VERSION ""

NS_ :

BS_:

BU_: TCM_Diesel ECM_Diesel BECMB_EPM TCM ECM Generic_BCM GWM _delete APIM BCM DCDC_VQM PAM TSTR PCM

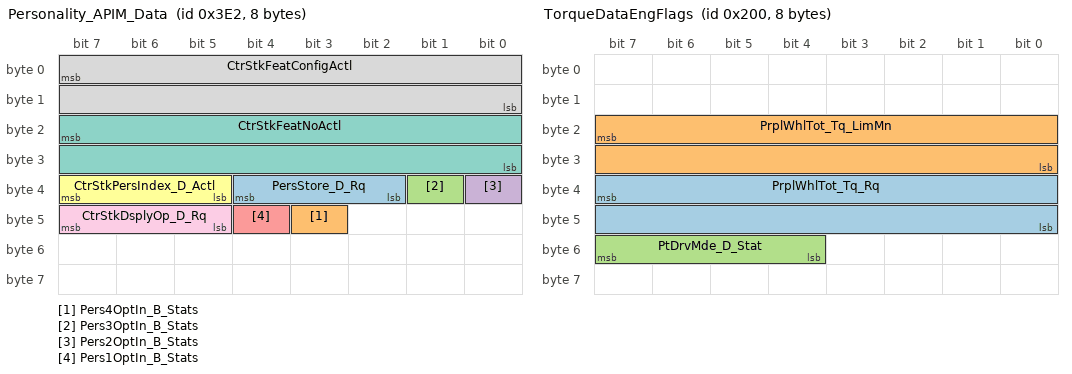
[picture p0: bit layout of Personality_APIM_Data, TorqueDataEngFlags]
BO_ 994 Personality_APIM_Data: 8 APIM
 SG_ PersStore_D_Rq : 36|3@0+ (1,0) [0|7] "SED"  GWM
 SG_ Pers4OptIn_B_Stats : 43|1@0+ (1,0) [0|1] "SED"  GWM,BCM
 SG_ Pers3OptIn_B_Stats : 33|1@0+ (1,0) [0|1] "SED"  GWM,BCM
 SG_ Pers2OptIn_B_Stats : 32|1@0+ (1,0) [0|1] "SED"  GWM,BCM
 SG_ Pers1OptIn_B_Stats : 44|1@0+ (1,0) [0|1] "SED"  GWM,BCM
 SG_ CtrStkPersIndex_D_Actl : 39|3@0+ (1,0) [0|7] "SED"  GWM,BCM
 SG_ CtrStkFeatNoActl : 23|16@0+ (1,0) [0|65535] "Undefined"  GWM,BCM
 SG_ CtrStkFeatConfigActl : 7|16@0+ (1,0) [0|65535] "Undefined"  GWM,BCM
 SG_ CtrStkDsplyOp_D_Rq : 47|3@0+ (1,0) [0|7] "SED"  GWM,BCM

BO_ 512 TorqueDataEngFlags: 8 PCM
 SG_ PrplWhlTot_Tq_Rq : 39|16@0+ (4,-131072) [-131072|131068] "Nm"  GWM
 SG_ PrplWhlTot_Tq_LimMn : 23|16@0+ (4,-131072) [-131072|131068] "Nm"  GWM
 SG_ PtDrvMde_D_Stat : 55|4@0+ (1,0) [0|15] "SED"  GWM

BO_ 65 Global_PATS_Control_Info: 8 BCM
 SG_ immoControlData_T1 : 15|40@0+ (1,0) [0|1099511627775] "Encrypted"  ECM_Diesel,ECM,PCM
 SG_ immoControlCmd_T1 : 7|3@0+ (1,0) [0|7] "SED"  ECM_Diesel,ECM,PCM

BO_ 1838 TesterPhysicalResBCM: 8 BCM
 SG_ TesterPhysicalResBCM : 7|64@0+ (1,0) [0|1.84467E+019] "unitless"  TSTR

BO_ 1830 TesterPhysicalReqBCM: 8 TSTR
 SG_ TesterPhysicalReqBCM : 7|64@0+ (1,0) [0|1.84467E+019] "unitless"  BCM

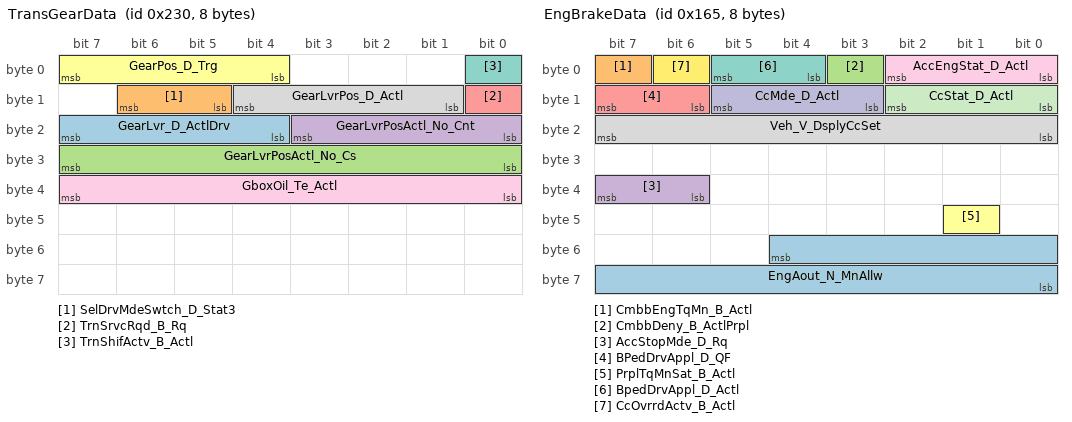
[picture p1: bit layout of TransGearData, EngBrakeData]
BO_ 560 TransGearData: 8 PCM
 SG_ GearLvr_D_ActlDrv : 23|4@0+ (1,0) [0|15] "SED"  GWM
 SG_ SelDrvMdeSwtch_D_Stat3 : 14|2@0+ (1,0) [0|3] "SED"  GWM
 SG_ GearLvrPosActl_No_Cs : 31|8@0+ (1,0) [0|255] "Unitless"  ECM_Diesel,GWM
 SG_ GearLvrPosActl_No_Cnt : 19|4@0+ (1,0) [0|15] "Unitless"  ECM_Diesel,GWM
 SG_ TrnSrvcRqd_B_Rq : 8|1@0+ (1,0) [0|1] "SED"  GWM
 SG_ GearPos_D_Trg : 7|4@0+ (1,0) [0|15] "SED"  ECM_Diesel,ECM,GWM
 SG_ TrnShifActv_B_Actl : 0|1@0+ (1,0) [0|1] "SED"  ECM_Diesel,ECM,GWM
 SG_ GearLvrPos_D_Actl : 12|4@0+ (1,0) [0|15] "SED"  ECM_Diesel,ECM,PAM,BCM,GWM
 SG_ GboxOil_Te_Actl : 39|8@0+ (1,-60) [-60|193] "degC"  ECM_Diesel,ECM,GWM

BO_ 357 EngBrakeData: 8 PCM
 SG_ EngAout_N_MnAllw : 52|13@0+ (2,0) [0|16382] "rpm"  GWM
 SG_ CmbbEngTqMn_B_Actl : 7|1@0+ (1,0) [0|1] "SED"  GWM
 SG_ CmbbDeny_B_ActlPrpl : 3|1@0+ (1,0) [0|1] "SED"  GWM
 SG_ AccStopMde_D_Rq : 39|2@0+ (1,0) [0|3] "SED"  GWM
 SG_ BPedDrvAppl_D_QF : 15|2@0+ (1,0) [0|3] "SED"  TCM_Diesel,TCM,GWM
 SG_ PrplTqMnSat_B_Actl : 41|1@0+ (1,0) [0|1] "SED"  GWM
 SG_ BpedDrvAppl_D_Actl : 5|2@0+ (1,0) [0|3] "SED"  TCM_Diesel,TCM,GWM
 SG_ Veh_V_DsplyCcSet : 23|8@0+ (1,0) [0|253] "Unitless"  GWM
 SG_ AccEngStat_D_Actl : 2|3@0+ (1,0) [0|7] "SED"  GWM
 SG_ CcMde_D_Actl : 13|3@0+ (1,0) [0|7] "SED"  TCM_Diesel,TCM,GWM
 SG_ CcStat_D_Actl : 10|3@0+ (1,0) [0|7] "SED"  TCM_Diesel,TCM,GWM
 SG_ CcOvrrdActv_B_Actl : 6|1@0+ (1,0) [0|1] "SED"  TCM_Diesel,TCM,GWM

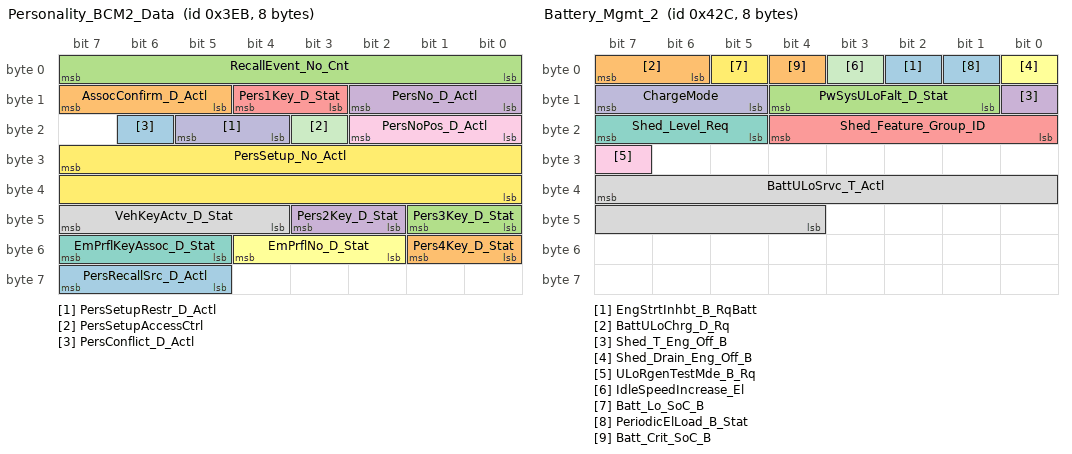
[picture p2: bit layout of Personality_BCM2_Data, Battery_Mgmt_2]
BO_ 1003 Personality_BCM2_Data: 8 BCM
 SG_ PersRecallSrc_D_Actl : 63|3@0+ (1,0) [0|7] "SED"  GWM
 SG_ Pers4Key_D_Stat : 49|2@0+ (1,0) [0|3] "SED"  GWM
 SG_ Pers3Key_D_Stat : 41|2@0+ (1,0) [0|3] "SED"  GWM
 SG_ Pers2Key_D_Stat : 43|2@0+ (1,0) [0|3] "SED"  GWM
 SG_ Pers1Key_D_Stat : 12|2@0+ (1,0) [0|3] "SED"  GWM
 SG_ EmPrflNo_D_Stat : 52|3@0+ (1,0) [0|7] "SED"  GWM
 SG_ EmPrflKeyAssoc_D_Stat : 55|3@0+ (1,0) [0|7] "SED"  GWM
 SG_ VehKeyActv_D_Stat : 47|4@0+ (1,0) [0|15] "SED"  GWM
 SG_ PersNoPos_D_Actl : 18|3@0+ (1,0) [0|7] "SED"  APIM,GWM
 SG_ PersSetupRestr_D_Actl : 21|2@0+ (1,0) [0|3] "SED"  APIM,GWM
 SG_ PersSetupAccessCtrl : 19|1@0+ (1,0) [0|1] "SED"  APIM,GWM
 SG_ PersSetup_No_Actl : 31|16@0+ (1,0) [0|65535] "Number"  APIM,GWM
 SG_ PersConflict_D_Actl : 22|1@0+ (1,0) [0|1] "SED"  APIM,GWM
 SG_ AssocConfirm_D_Actl : 15|3@0+ (1,0) [0|7] "SED"  APIM,GWM
 SG_ RecallEvent_No_Cnt : 7|8@0+ (1,0) [0|255] "Counts"  APIM,GWM
 SG_ PersNo_D_Actl : 10|3@0+ (1,0) [0|7] "SED"  APIM,GWM

BO_ 2016 TesterPhysicalReqPCM: 8 TSTR
 SG_ TesterPhysicalReqPCM : 7|64@0+ (1,0) [0|1.84467E+019] "unitless"  ECM_Diesel,ECM,PCM

BO_ 1034 GGCC_Config_Mgmt_ID_1: 8 BCM
 SG_ VehicleGGCCData : 7|64@0+ (1,0) [0|1.84467E+019] "mixed"  TCM_Diesel,ECM_Diesel,TCM,ECM,PAM,GWM,PCM

BO_ 1068 Battery_Mgmt_2: 8 BCM
 SG_ EngStrtInhbt_B_RqBatt : 2|1@0+ (1,0) [0|1] "SED"  ECM_Diesel,ECM,GWM,PCM
 SG_ BattULoChrg_D_Rq : 7|2@0+ (1,0) [0|3] "SED"  ECM_Diesel,ECM,GWM,PCM
 SG_ PwSysULoFalt_D_Stat : 12|4@0+ (1,0) [0|15] "SED"  GWM
 SG_ Shed_T_Eng_Off_B : 8|1@0+ (1,0) [0|1] "SED"  GWM
 SG_ Shed_Feature_Group_ID : 20|5@0+ (1,0) [0|31] "SED"  ECM_Diesel,ECM,PCM,GWM
 SG_ Shed_Drain_Eng_Off_B : 0|1@0+ (1,0) [0|1] "SED"  GWM
 SG_ Shed_Level_Req : 23|3@0+ (1,0) [0|7] "SED"  ECM_Diesel,ECM,PCM,GWM
 SG_ BattULoSrvc_T_Actl : 39|12@0+ (1,0) [0|4095] "days"  GWM
 SG_ ULoRgenTestMde_B_Rq : 31|1@0+ (1,0) [0|1] "SED"  ECM_Diesel,ECM,GWM,PCM
 SG_ ChargeMode : 15|3@0+ (1,0) [0|7] "SED"  ECM_Diesel,ECM,GWM,PCM
 SG_ IdleSpeedIncrease_El : 3|1@0+ (1,0) [0|1] "SED"  GWM
 SG_ Batt_Lo_SoC_B : 5|1@0+ (1,0) [0|1] "SED"  GWM
 SG_ PeriodicElLoad_B_Stat : 1|1@0+ (1,0) [0|1] "SED"  ECM_Diesel,GWM
 SG_ Batt_Crit_SoC_B : 4|1@0+ (1,0) [0|1] "SED"  GWM

BO_ 947 BodyInfo_3: 8 BCM
 SG_ ValetMode_D_Mem : 16|1@0+ (1,0) [0|1] "SED"  GWM
 SG_ DimmingLvlEvnt_No_Actl : 18|2@0+ (1,0) [0|3] "unitless"  GWM
 SG_ DrStatDrvErrCnt_B_Stat : 19|1@0+ (1,0) [0|1] "SED"  ECM_Diesel,ECM,GWM,PCM
 SG_ TurnLghtRight_D_Rq : 63|2@0+ (1,0) [0|3] "SED"  GWM
 SG_ TurnLghtRightOn_B_Stat : 35|1@0+ (1,0) [0|1] "SED"  GWM
 SG_ TurnLghtLeftOn_B_Stat : 54|1@0+ (1,0) [0|1] "SED"  GWM
 SG_ FogLghtRearOn_B_Stat : 1|1@0+ (1,0) [0|1] "SED"  GWM
 SG_ Backlit_LED_Status : 23|4@0+ (1,0) [0|15] "SED"  GWM
 SG_ TurnLghtLeft_D_Rq : 9|2@0+ (1,0) [0|3] "SED"  GWM
 SG_ FogLghtFrontOn_B_Stat : 56|1@0+ (1,0) [0|1] "SED"  GWM
 SG_ IgnKeyType_D_Actl : 39|4@0+ (1,0) [0|15] "SED"  ECM_Diesel,ECM,GWM,PCM,PAM
 SG_ Parklamp_Status : 3|2@0+ (1,0) [0|3] "SED"  GWM
 SG_ Litval : 47|8@0+ (1,0) [0|253] "SED"  GWM
 SG_ Key_In_Ignition_Stat : 11|1@0+ (1,0) [0|1] "SED"  GWM
 SG_ Ignition_Status : 7|4@0+ (1,0) [0|15] "SED"  TCM_Diesel,ECM_Diesel,BECMB_EPM,TCM,ECM,PAM,PCM,GWM
 SG_ Dimming_Lvl : 31|8@0+ (1,0) [0|253] "SED"  GWM
 SG_ Day_Night_Status : 15|2@0+ (1,0) [0|3] "SED"  ECM_Diesel,ECM,PAM,PCM,GWM
 SG_ Remote_Start_Status : 13|2@0+ (1,0) [0|3] "SED"  BECMB_EPM,GWM
 SG_ DrStatTgate_B_Actl : 0|1@0+ (1,0) [0|1] "SED"  PAM,GWM
 SG_ DrStatRr_B_Actl : 49|1@0+ (1,0) [0|1] "SED"  PAM,GWM
 SG_ DrStatRl_B_Actl : 48|1@0+ (1,0) [0|1] "SED"  PAM,GWM
 SG_ DrStatPsngr_B_Actl : 60|1@0+ (1,0) [0|1] "SED"  PAM,GWM
 SG_ DrStatInnrTgate_B_Actl : 58|1@0+ (1,0) [0|1] "SED"  PAM,GWM
 SG_ DrStatHood_B_Actl : 59|1@0+ (1,0) [0|1] "SED"  GWM
 SG_ DrStatDrv_B_Actl : 61|1@0+ (1,0) [0|1] "SED"  ECM_Diesel,ECM,PAM,PCM,GWM
 SG_ PrkBrkActv_B_Actl : 55|1@0+ (1,0) [0|1] "SED"  TCM_Diesel,ECM_Diesel,TCM,ECM,PAM,PCM,GWM
 SG_ LifeCycMde_D_Actl : 53|4@0+ (1,0) [0|15] "SED"  TCM_Diesel,ECM_Diesel,TCM,ECM,PAM,PCM,GWM
 SG_ Delay_Accy : 57|1@0+ (1,0) [0|1] "SED"  GWM
 SG_ CrashEvnt_D_Stat : 34|2@0+ (1,0) [0|3] "SED"  GWM
 SG_ FuelPmpInhbt_B_Stat : 32|1@0+ (1,0) [0|1] "SED"  GWM
 SG_ BodySrvcRqd_B_Rq : 10|1@0+ (1,0) [0|1] "SED"  GWM

BO_ 986 Personality_APIM_Data3_HS1: 8 GWM
 SG_ LightAmbIntsty_No_Rq : 15|8@0+ (1,0) [0|255] "unitless"  BCM
 SG_ LightAmbColor_No_Rq : 7|8@0+ (1,0) [0|255] "Discrete"  BCM

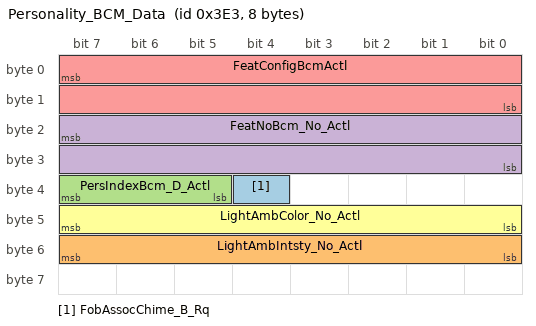
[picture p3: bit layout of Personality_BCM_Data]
BO_ 995 Personality_BCM_Data: 8 BCM
 SG_ FobAssocChime_B_Rq : 36|1@0+ (1,0) [0|1] "SED"  GWM
 SG_ LightAmbIntsty_No_Actl : 55|8@0+ (1,0) [0|255] "unitless"  APIM,GWM
 SG_ PersIndexBcm_D_Actl : 39|3@0+ (1,0) [0|7] "SED"  APIM,GWM
 SG_ FeatNoBcm_No_Actl : 23|16@0+ (1,0) [0|65535] "Number"  APIM,GWM
 SG_ FeatConfigBcmActl : 7|16@0+ (1,0) [0|65535] "Undefined"  APIM,GWM
 SG_ LightAmbColor_No_Actl : 47|8@0+ (1,0) [0|255] "Discrete"  APIM,GWM

BO_ 2000 TesterPhysicalReqAPIM: 8 TSTR
 SG_ TesterPhysicalReqAPIM : 7|64@0+ (1,0) [0|1.84467E+019] "unitless"  APIM

BO_TX_BU_ 994 : GWM,APIM;
BO_TX_BU_ 512 : ECM_Diesel,ECM,PCM;
BO_TX_BU_ 560 : TCM_Diesel,TCM,PCM;
BO_TX_BU_ 357 : ECM_Diesel,ECM,PCM;
CM_ SG_ 512 PtDrvMde_D_Stat "Applicable to Raptor, this signal will be removed for SDM, PCM will not transmit as of 10/15/15
";
CM_ BO_ 65 "Provide control function information to the target function of the Passive Anti-Theft Subsystem";
CM_ SG_ 560 GearLvrPosActl_No_Cs "TCM_D Tx only on P552";
CM_ SG_ 560 GearLvrPosActl_No_Cnt "TCM_D Tx only on P552";
CM_ SG_ 560 TrnSrvcRqd_B_Rq "Signal not transmitted on Diesel and HEV variants.";
CM_ SG_ 560 GearPos_D_Trg "Signal not transmitted on HEV variants.";
CM_ SG_ 560 TrnShifActv_B_Actl "Signal not transmitted on HEV variants.";
CM_ SG_ 560 GboxOil_Te_Actl "Signal not transmitted on HEV variants.";
CM_ SG_ 357 EngAout_N_MnAllw "Transmitted by ECM_D only on P552";
CM_ SG_ 357 CmbbEngTqMn_B_Actl "Not Supported on 2018.5 ECM_Diesel NID";
CM_ SG_ 357 CmbbDeny_B_ActlPrpl "Not Supported on 2018.5 ECM_Diesel NID
";
CM_ SG_ 357 AccStopMde_D_Rq "ABSGenSigTimeoutTime=1000
Not Supported by ECM_Diesel NID";
CM_ SG_ 357 BpedDrvAppl_D_Actl "CCMGenSigTimeoutTime=1000";
CM_ SG_ 357 CcStat_D_Actl "ABSGenSigTimeoutTime=1000";
CM_ SG_ 1034 VehicleGGCCData "RCMGenSigTimeout=6000";
CM_ SG_ 947 Dimming_Lvl "Refer to Vehicle Interior Illum Dimming Ctrl Sys Eng Spec, Table 2

";
CM_ SG_ 947 PrkBrkActv_B_Actl "Signal not transmitted on vehicles with electric park brake. ";
BA_DEF_ SG_  "U_V36X_MY18_5_Gas_Tx" ENUM  "No","Yes";
BA_DEF_ SG_  "U_V36X_MY18_5_Hev_Tx" ENUM  "No","Yes";
BA_DEF_ SG_  "U_V36X_MY19_5_Diesel_Tx" ENUM  "No","Yes";
BA_DEF_ SG_  "U_V363E_N_MY19_5_20_Gas_Tx" ENUM  "No","Yes";
BA_DEF_ SG_  "U_V363E_N_MY19_5_20_Diesel_Tx" ENUM  "No","Yes";
BA_DEF_ SG_  "U_CD42_MY19_Diesel_Tx" ENUM  "No","Yes";
BA_DEF_ SG_  "U_V408_MY18_Diesel_Rx" ENUM  "No","Yes";
BA_DEF_ SG_  "U_V408_MY18_Gas_Tx" ENUM  "No","Yes";
BA_DEF_ SG_  "U_V408_MY18_Diesel_Tx" ENUM  "No","Yes";
BA_DEF_ SG_  "U_V36X_MY18_5_Diesel_Tx" ENUM  "No","Yes";
BA_DEF_ SG_  "U_P552_MY18_5_Gas_Tx" ENUM  "No","Yes";
BA_DEF_ SG_  "U_P552_MY18_5_Diesel_Tx" ENUM  "No","Yes";
BA_DEF_ SG_  "U_U55x_MY18_Gas_Rx" ENUM  "No","Yes";
BA_DEF_ SG_  "U_U55x_MY18_Gas_Tx" ENUM  "No","Yes";
BA_DEF_ BO_  "FrameGatewayNetwork" STRING ;
BA_DEF_ SG_  "U_C489_MY17_Gas_Rx" ENUM  "No","Yes";
BA_DEF_ SG_  "U_CD43_MY17_Gas_Rx" ENUM  "No","Yes";
BA_DEF_ SG_  "U_P552_MY17_Gas_Rx" ENUM  "No","Yes";
BA_DEF_ SG_  "U_B515_MCA_MY17_Diesel_Rx" ENUM  "No","Yes";
BA_DEF_ SG_  "U_B515_MCA_MY17_Gas_Rx" ENUM  "No","Yes";
BA_DEF_ SG_  "U_C489_MY17_Gas_Tx" ENUM  "No","Yes";
BA_DEF_ SG_  "U_CD43_MY17_Gas_Tx" ENUM  "No","Yes";
BA_DEF_ SG_  "U_P552_MY17_Gas_Tx" ENUM  "No","Yes";
BA_DEF_ SG_  "U_B515_MCA_MY17_Diesel_Tx" ENUM  "No","Yes";
BA_DEF_ SG_  "U_B515_MCA_MY17_Gas_Tx" ENUM  "No","Yes";
BA_DEF_ SG_  "U_B479_MY17_Gas_Rx" ENUM  "No","Yes";
BA_DEF_ SG_  "U_CD4_MY17_Diesel_Rx" ENUM  "No","Yes";
BA_DEF_ SG_  "U_CD4_MY17_Gas_Rx" ENUM  "No","Yes";
BA_DEF_ SG_  "U_CD4_MY17_Hev_Rx" ENUM  "No","Yes";
BA_DEF_ SG_  "U_CD4_MY17_Phev_Rx" ENUM  "No","Yes";
BA_DEF_ SG_  "U_CD42_MY16_Diesel_Rx" ENUM  "No","Yes";
BA_DEF_ SG_  "U_CD42_MY16_Gas_Rx" ENUM  "No","Yes";
BA_DEF_ SG_  "U_CD4_MY17_Diesel_Tx" ENUM  "No","Yes";
BA_DEF_ SG_  "U_CD4_MY17_Gas_Tx" ENUM  "No","Yes";
BA_DEF_ SG_  "U_CD4_MY17_Hev_Tx" ENUM  "No","Yes";
BA_DEF_ SG_  "U_CD4_MY17_Phev_Tx" ENUM  "No","Yes";
BA_DEF_ SG_  "U_CD42_MY16_Diesel_Tx" ENUM  "No","Yes";
BA_DEF_ SG_  "U_CD42_MY16_Gas_Tx" ENUM  "No","Yes";
BA_DEF_ SG_  "U_CD42_MY15_Diesel_Rx" ENUM  "No","Yes";
BA_DEF_ SG_  "U_CD42_MY15_Gas_Rx" ENUM  "No","Yes";
BA_DEF_ SG_  "U_U502_MY16_Gas_Rx" ENUM  "No","Yes";
BA_DEF_ SG_  "U_P558_MY17_Gas_Rx" ENUM  "No","Yes";
BA_DEF_ SG_  "U_P558_MY17_Diesel_Rx" ENUM  "No","Yes";
BA_DEF_ SG_  "U_V36X_MY16_5_Diesel_Rx" ENUM  "No","Yes";
BA_DEF_ SG_  "U_CD42_MY15_Diesel_Tx" ENUM  "No","Yes";
BA_DEF_ SG_  "U_CD42_MY15_Gas_Tx" ENUM  "No","Yes";
BA_DEF_ SG_  "U_U502_MY16_Gas_Tx" ENUM  "No","Yes";
BA_DEF_ SG_  "U_CD4_MY15_Diesel_Tx" ENUM  "No","Yes";
BA_DEF_ SG_  "U_CD4_MY15_Gas_Tx" ENUM  "No","Yes";
BA_DEF_ SG_  "U_CD4_MY15_Hev_Tx" ENUM  "No","Yes";
BA_DEF_ SG_  "U_CD4_MY15_Phev_Tx" ENUM  "No","Yes";
BA_DEF_ SG_  "U_P558_MY17_Gas_Tx" ENUM  "No","Yes";
BA_DEF_ SG_  "U_P558_MY17_Diesel_Tx" ENUM  "No","Yes";
BA_DEF_ SG_  "U_V36X_MY16_5_Diesel_Tx" ENUM  "No","Yes";
BA_DEF_ SG_  "GenSigTimeoutTime_TCM" INT 0 100000;
BA_DEF_ SG_  "Gateway_ID" INT 0 0;
BA_DEF_ BO_  "FrameGatewayHS3" HEX 0 1407;
BA_DEF_ BO_  "NetworkInitialization" ENUM  "No","Yes";
BA_DEF_ BO_  "FrameGatewayId" HEX 0 1407;
BA_DEF_ BO_  "GenMsgStartDelayTime" INT 0 10000;
BA_DEF_ BO_  "GenMsgDelayTime" INT 0 1000;
BA_DEF_ BO_  "GenMsgCycleTime" INT 0 100000;
BA_DEF_ BO_  "GenMsgSendType" ENUM  "FixedPeriodic","Event","EnabledPeriodic","NotUsed","NotUsed","EventPeriodic","NotUsed","NotUsed","NoMsgSendType";
BA_DEF_ SG_  "U_CD4_MY14_Phev_Tx" ENUM  "No","Yes";
BA_DEF_ SG_  "U_CD4_MY14_Hev_Tx" ENUM  "No","Yes";
BA_DEF_ SG_  "U_CD4_MY14_Gas_Tx" ENUM  "No","Yes";
BA_DEF_ SG_  "U_CD4_MY14_Diesel_Tx" ENUM  "No","Yes";
BA_DEF_ SG_  "U_CD43_MY16_Gas_Tx" ENUM  "No","Yes";
BA_DEF_ SG_  "U_UP375_MY15_Diesel_Tx" ENUM  "No","Yes";
BA_DEF_ SG_  "U_UP375_MY15_Gas_Tx" ENUM  "No","Yes";
BA_DEF_ SG_  "U_U502_MY15_Gas_Tx" ENUM  "No","Yes";
BA_DEF_ SG_  "U_C489_MY14_Gas_Tx" ENUM  "No","Yes";
BA_DEF_ SG_  "U_S550_MY15_Gas_Tx" ENUM  "No","Yes";
BA_DEF_ SG_  "U_P552_MY15_Gas_Tx" ENUM  "No","Yes";
BA_DEF_ SG_  "U_CD42_MY14_Gas_Tx" ENUM  "No","Yes";
BA_DEF_ SG_  "U_CD42_MY14_Diesel_Tx" ENUM  "No","Yes";
BA_DEF_ SG_  "U_CD4_MY13_Phev_Tx" ENUM  "No","Yes";
BA_DEF_ SG_  "U_CD4_MY13_Hev_Tx" ENUM  "No","Yes";
BA_DEF_ SG_  "U_CD4_MY13_Gas_Tx" ENUM  "No","Yes";
BA_DEF_ SG_  "U_CD4_MY13_Diesel_Tx" ENUM  "No","Yes";
BA_DEF_ SG_  "U_CD4_MY14_Phev_Rx" ENUM  "No","Yes";
BA_DEF_ SG_  "U_CD4_MY14_Hev_Rx" ENUM  "No","Yes";
BA_DEF_ SG_  "U_CD4_MY14_Gas_Rx" ENUM  "No","Yes";
BA_DEF_ SG_  "U_CD4_MY14_Diesel_Rx" ENUM  "No","Yes";
BA_DEF_ SG_  "U_CD43_MY16_Gas_Rx" ENUM  "No","Yes";
BA_DEF_ SG_  "U_UP375_MY15_Diesel_Rx" ENUM  "No","Yes";
BA_DEF_ SG_  "U_UP375_MY15_Gas_Rx" ENUM  "No","Yes";
BA_DEF_ SG_  "U_B479_MY15_Gas_Rx" ENUM  "No","Yes";
BA_DEF_ SG_  "U_U502_MY15_Gas_Rx" ENUM  "No","Yes";
BA_DEF_ SG_  "U_C489_MY14_Gas_Rx" ENUM  "No","Yes";
BA_DEF_ SG_  "U_S550_MY15_Gas_Rx" ENUM  "No","Yes";
BA_DEF_ SG_  "U_P552_MY15_Gas_Rx" ENUM  "No","Yes";
BA_DEF_ SG_  "U_CD42_MY14_Gas_Rx" ENUM  "No","Yes";
BA_DEF_ SG_  "U_CD42_MY14_Diesel_Rx" ENUM  "No","Yes";
BA_DEF_ SG_  "U_CD4_MY13_Phev_Rx" ENUM  "No","Yes";
BA_DEF_ SG_  "U_CD4_MY13_Hev_Rx" ENUM  "No","Yes";
BA_DEF_ SG_  "U_CD4_MY13_Gas_Rx" ENUM  "No","Yes";
BA_DEF_ SG_  "U_CD4_MY13_Diesel_Rx" ENUM  "No","Yes";
BA_DEF_ SG_  "ContentDependant" ENUM  "No","Yes";
BA_DEF_ SG_  "GenSigStartValue" INT 0 1000000000;
BA_DEF_ SG_  "CrossOver_LIN" ENUM  "No","Yes";
BA_DEF_ SG_  "CrossOver_InfoCAN" ENUM  "No","Yes";
BA_DEF_ SG_  "WakeupSignal" ENUM  "No","Yes";
BA_DEF_ SG_  "GenSigSendType" ENUM  "Cyclic","OnWrite","vector_leerstring","OnChange","vector_leerstring","IfActive","vector_leerstring","NoSigSendType";
BA_DEF_ BO_  "DiagRequest" ENUM  "No","Yes";
BA_DEF_ BO_  "DiagResponse" ENUM  "No","Yes";
BA_DEF_ BO_  "GenMsgILSupport" ENUM  "No","Yes";
BA_DEF_DEF_  "U_V36X_MY18_5_Gas_Tx" "No";
BA_DEF_DEF_  "U_V36X_MY18_5_Hev_Tx" "No";
BA_DEF_DEF_  "U_V36X_MY19_5_Diesel_Tx" "No";
BA_DEF_DEF_  "U_V363E_N_MY19_5_20_Gas_Tx" "No";
BA_DEF_DEF_  "U_V363E_N_MY19_5_20_Diesel_Tx" "No";
BA_DEF_DEF_  "U_CD42_MY19_Diesel_Tx" "No";
BA_DEF_DEF_  "U_V408_MY18_Diesel_Rx" "No";
BA_DEF_DEF_  "U_V408_MY18_Gas_Tx" "No";
BA_DEF_DEF_  "U_V408_MY18_Diesel_Tx" "No";
BA_DEF_DEF_  "U_V36X_MY18_5_Diesel_Tx" "No";
BA_DEF_DEF_  "U_P552_MY18_5_Gas_Tx" "No";
BA_DEF_DEF_  "U_P552_MY18_5_Diesel_Tx" "No";
BA_DEF_DEF_  "U_U55x_MY18_Gas_Rx" "No";
BA_DEF_DEF_  "U_U55x_MY18_Gas_Tx" "No";
BA_DEF_DEF_  "FrameGatewayNetwork" "NONE";
BA_DEF_DEF_  "U_C489_MY17_Gas_Rx" "No";
BA_DEF_DEF_  "U_CD43_MY17_Gas_Rx" "No";
BA_DEF_DEF_  "U_P552_MY17_Gas_Rx" "No";
BA_DEF_DEF_  "U_B515_MCA_MY17_Diesel_Rx" "No";
BA_DEF_DEF_  "U_B515_MCA_MY17_Gas_Rx" "No";
BA_DEF_DEF_  "U_C489_MY17_Gas_Tx" "No";
BA_DEF_DEF_  "U_CD43_MY17_Gas_Tx" "No";
BA_DEF_DEF_  "U_P552_MY17_Gas_Tx" "No";
BA_DEF_DEF_  "U_B515_MCA_MY17_Diesel_Tx" "No";
BA_DEF_DEF_  "U_B515_MCA_MY17_Gas_Tx" "No";
BA_DEF_DEF_  "U_B479_MY17_Gas_Rx" "No";
BA_DEF_DEF_  "U_CD4_MY17_Diesel_Rx" "No";
BA_DEF_DEF_  "U_CD4_MY17_Gas_Rx" "No";
BA_DEF_DEF_  "U_CD4_MY17_Hev_Rx" "No";
BA_DEF_DEF_  "U_CD4_MY17_Phev_Rx" "No";
BA_DEF_DEF_  "U_CD42_MY16_Diesel_Rx" "No";
BA_DEF_DEF_  "U_CD42_MY16_Gas_Rx" "No";
BA_DEF_DEF_  "U_CD4_MY17_Diesel_Tx" "No";
BA_DEF_DEF_  "U_CD4_MY17_Gas_Tx" "No";
BA_DEF_DEF_  "U_CD4_MY17_Hev_Tx" "No";
BA_DEF_DEF_  "U_CD4_MY17_Phev_Tx" "No";
BA_DEF_DEF_  "U_CD42_MY16_Diesel_Tx" "No";
BA_DEF_DEF_  "U_CD42_MY16_Gas_Tx" "No";
BA_DEF_DEF_  "U_CD42_MY15_Diesel_Rx" "No";
BA_DEF_DEF_  "U_CD42_MY15_Gas_Rx" "No";
BA_DEF_DEF_  "U_U502_MY16_Gas_Rx" "No";
BA_DEF_DEF_  "U_P558_MY17_Gas_Rx" "No";
BA_DEF_DEF_  "U_P558_MY17_Diesel_Rx" "No";
BA_DEF_DEF_  "U_V36X_MY16_5_Diesel_Rx" "No";
BA_DEF_DEF_  "U_CD42_MY15_Diesel_Tx" "No";
BA_DEF_DEF_  "U_CD42_MY15_Gas_Tx" "No";
BA_DEF_DEF_  "U_U502_MY16_Gas_Tx" "No";
BA_DEF_DEF_  "U_CD4_MY15_Diesel_Tx" "No";
BA_DEF_DEF_  "U_CD4_MY15_Gas_Tx" "No";
BA_DEF_DEF_  "U_CD4_MY15_Hev_Tx" "No";
BA_DEF_DEF_  "U_CD4_MY15_Phev_Tx" "No";
BA_DEF_DEF_  "U_P558_MY17_Gas_Tx" "No";
BA_DEF_DEF_  "U_P558_MY17_Diesel_Tx" "No";
BA_DEF_DEF_  "U_V36X_MY16_5_Diesel_Tx" "No";
BA_DEF_DEF_  "GenSigTimeoutTime_TCM" 5000;
BA_DEF_DEF_  "Gateway_ID" 0;
BA_DEF_DEF_  "FrameGatewayHS3" 0;
BA_DEF_DEF_  "NetworkInitialization" "No";
BA_DEF_DEF_  "FrameGatewayId" 0;
BA_DEF_DEF_  "GenMsgStartDelayTime" 0;
BA_DEF_DEF_  "GenMsgDelayTime" 20;
BA_DEF_DEF_  "GenMsgCycleTime" 0;
BA_DEF_DEF_  "GenMsgSendType" "NoMsgSendType";
BA_DEF_DEF_  "U_CD4_MY14_Phev_Tx" "No";
BA_DEF_DEF_  "U_CD4_MY14_Hev_Tx" "No";
BA_DEF_DEF_  "U_CD4_MY14_Gas_Tx" "No";
BA_DEF_DEF_  "U_CD4_MY14_Diesel_Tx" "No";
BA_DEF_DEF_  "U_CD43_MY16_Gas_Tx" "No";
BA_DEF_DEF_  "U_UP375_MY15_Diesel_Tx" "No";
BA_DEF_DEF_  "U_UP375_MY15_Gas_Tx" "No";
BA_DEF_DEF_  "U_U502_MY15_Gas_Tx" "No";
BA_DEF_DEF_  "U_C489_MY14_Gas_Tx" "No";
BA_DEF_DEF_  "U_S550_MY15_Gas_Tx" "No";
BA_DEF_DEF_  "U_P552_MY15_Gas_Tx" "No";
BA_DEF_DEF_  "U_CD42_MY14_Gas_Tx" "No";
BA_DEF_DEF_  "U_CD42_MY14_Diesel_Tx" "No";
BA_DEF_DEF_  "U_CD4_MY13_Phev_Tx" "No";
BA_DEF_DEF_  "U_CD4_MY13_Hev_Tx" "No";
BA_DEF_DEF_  "U_CD4_MY13_Gas_Tx" "No";
BA_DEF_DEF_  "U_CD4_MY13_Diesel_Tx" "No";
BA_DEF_DEF_  "U_CD4_MY14_Phev_Rx" "No";
BA_DEF_DEF_  "U_CD4_MY14_Hev_Rx" "No";
BA_DEF_DEF_  "U_CD4_MY14_Gas_Rx" "No";
BA_DEF_DEF_  "U_CD4_MY14_Diesel_Rx" "No";
BA_DEF_DEF_  "U_CD43_MY16_Gas_Rx" "No";
BA_DEF_DEF_  "U_UP375_MY15_Diesel_Rx" "No";
BA_DEF_DEF_  "U_UP375_MY15_Gas_Rx" "No";
BA_DEF_DEF_  "U_B479_MY15_Gas_Rx" "No";
BA_DEF_DEF_  "U_U502_MY15_Gas_Rx" "No";
BA_DEF_DEF_  "U_C489_MY14_Gas_Rx" "No";
BA_DEF_DEF_  "U_S550_MY15_Gas_Rx" "No";
BA_DEF_DEF_  "U_P552_MY15_Gas_Rx" "No";
BA_DEF_DEF_  "U_CD42_MY14_Gas_Rx" "No";
BA_DEF_DEF_  "U_CD42_MY14_Diesel_Rx" "No";
BA_DEF_DEF_  "U_CD4_MY13_Phev_Rx" "No";
BA_DEF_DEF_  "U_CD4_MY13_Hev_Rx" "No";
BA_DEF_DEF_  "U_CD4_MY13_Gas_Rx" "No";
BA_DEF_DEF_  "U_CD4_MY13_Diesel_Rx" "No";
BA_DEF_DEF_  "ContentDependant" "No";
BA_DEF_DEF_  "GenSigStartValue" 0;
BA_DEF_DEF_  "CrossOver_LIN" "No";
BA_DEF_DEF_  "CrossOver_InfoCAN" "No";
BA_DEF_DEF_  "WakeupSignal" "No";
BA_DEF_DEF_  "GenSigSendType" "NoSigSendType";
BA_DEF_DEF_  "DiagRequest" "No";
BA_DEF_DEF_  "DiagResponse" "No";
BA_DEF_DEF_  "GenMsgILSupport" "Yes";
BA_ "NetworkInitialization" BO_ 994 1;
BA_ "FrameGatewayHS3" BO_ 994 987;
BA_ "GenMsgSendType" BO_ 994 5;
BA_ "GenMsgCycleTime" BO_ 994 1000;
BA_ "GenMsgSendType" BO_ 512 0;
BA_ "GenMsgCycleTime" BO_ 512 20;
BA_ "GenMsgDelayTime" BO_ 512 10;
BA_ "NetworkInitialization" BO_ 512 1;
BA_ "GenMsgSendType" BO_ 65 0;
BA_ "GenMsgCycleTime" BO_ 65 20;
BA_ "GenMsgDelayTime" BO_ 65 10;
BA_ "GenMsgILSupport" BO_ 1838 0;
BA_ "DiagResponse" BO_ 1838 1;
BA_ "GenMsgSendType" BO_ 1838 1;
BA_ "GenMsgDelayTime" BO_ 1838 0;
BA_ "GenMsgILSupport" BO_ 1830 0;
BA_ "DiagRequest" BO_ 1830 1;
BA_ "GenMsgSendType" BO_ 1830 1;
BA_ "GenMsgDelayTime" BO_ 1830 0;
BA_ "GenMsgSendType" BO_ 560 0;
BA_ "GenMsgCycleTime" BO_ 560 20;
BA_ "GenMsgDelayTime" BO_ 560 10;
BA_ "NetworkInitialization" BO_ 560 1;
BA_ "GenMsgSendType" BO_ 357 0;
BA_ "GenMsgCycleTime" BO_ 357 20;
BA_ "GenMsgDelayTime" BO_ 357 10;
BA_ "NetworkInitialization" BO_ 357 1;
BA_ "GenMsgSendType" BO_ 1003 5;
BA_ "GenMsgCycleTime" BO_ 1003 1000;
BA_ "NetworkInitialization" BO_ 1003 1;
BA_ "GenMsgILSupport" BO_ 2016 0;
BA_ "DiagRequest" BO_ 2016 1;
BA_ "GenMsgSendType" BO_ 2016 1;
BA_ "GenMsgDelayTime" BO_ 2016 0;
BA_ "GenMsgSendType" BO_ 1034 0;
BA_ "GenMsgCycleTime" BO_ 1034 200;
BA_ "GenMsgSendType" BO_ 1068 0;
BA_ "GenMsgCycleTime" BO_ 1068 50;
BA_ "NetworkInitialization" BO_ 947 1;
BA_ "GenMsgSendType" BO_ 947 5;
BA_ "GenMsgCycleTime" BO_ 947 500;
BA_ "GenMsgStartDelayTime" BO_ 947 100;
BA_ "FrameGatewayNetwork" BO_ 986 "HS3_CAN";
BA_ "FrameGatewayId" BO_ 986 986;
BA_ "FrameGatewayHS3" BO_ 986 986;
BA_ "GenMsgSendType" BO_ 995 5;
BA_ "GenMsgCycleTime" BO_ 995 1000;
BA_ "GenMsgILSupport" BO_ 2000 0;
BA_ "DiagRequest" BO_ 2000 1;
BA_ "GenMsgSendType" BO_ 2000 1;
BA_ "GenMsgDelayTime" BO_ 2000 0;
BA_ "CrossOver_InfoCAN" SG_ 994 PersStore_D_Rq 1;
BA_ "GenSigSendType" SG_ 994 PersStore_D_Rq 3;
BA_ "U_CD4_MY13_Diesel_Tx" SG_ 994 PersStore_D_Rq 1;
BA_ "U_CD4_MY13_Gas_Tx" SG_ 994 PersStore_D_Rq 1;
BA_ "U_CD4_MY13_Hev_Tx" SG_ 994 PersStore_D_Rq 1;
BA_ "U_CD4_MY13_Phev_Tx" SG_ 994 PersStore_D_Rq 1;
BA_ "U_CD42_MY14_Diesel_Tx" SG_ 994 PersStore_D_Rq 1;
BA_ "U_CD42_MY14_Gas_Tx" SG_ 994 PersStore_D_Rq 1;
BA_ "U_P552_MY15_Gas_Tx" SG_ 994 PersStore_D_Rq 1;
BA_ "U_S550_MY15_Gas_Tx" SG_ 994 PersStore_D_Rq 1;
BA_ "U_C489_MY14_Gas_Tx" SG_ 994 PersStore_D_Rq 1;
BA_ "U_U502_MY15_Gas_Tx" SG_ 994 PersStore_D_Rq 1;
BA_ "U_CD43_MY16_Gas_Tx" SG_ 994 PersStore_D_Rq 1;
BA_ "U_CD4_MY14_Diesel_Tx" SG_ 994 PersStore_D_Rq 1;
BA_ "U_CD4_MY14_Gas_Tx" SG_ 994 PersStore_D_Rq 1;
BA_ "U_CD4_MY14_Hev_Tx" SG_ 994 PersStore_D_Rq 1;
BA_ "U_CD4_MY14_Phev_Tx" SG_ 994 PersStore_D_Rq 1;
BA_ "CrossOver_InfoCAN" SG_ 994 Pers4OptIn_B_Stats 1;
BA_ "GenSigSendType" SG_ 994 Pers4OptIn_B_Stats 3;
BA_ "U_CD4_MY13_Diesel_Rx" SG_ 994 Pers4OptIn_B_Stats 1;
BA_ "U_CD4_MY13_Gas_Rx" SG_ 994 Pers4OptIn_B_Stats 1;
BA_ "U_CD4_MY13_Hev_Rx" SG_ 994 Pers4OptIn_B_Stats 1;
BA_ "U_CD4_MY13_Phev_Rx" SG_ 994 Pers4OptIn_B_Stats 1;
BA_ "U_CD42_MY14_Diesel_Rx" SG_ 994 Pers4OptIn_B_Stats 1;
BA_ "U_CD42_MY14_Gas_Rx" SG_ 994 Pers4OptIn_B_Stats 1;
BA_ "U_P552_MY15_Gas_Rx" SG_ 994 Pers4OptIn_B_Stats 1;
BA_ "U_S550_MY15_Gas_Rx" SG_ 994 Pers4OptIn_B_Stats 1;
BA_ "U_C489_MY14_Gas_Rx" SG_ 994 Pers4OptIn_B_Stats 1;
BA_ "U_U502_MY15_Gas_Rx" SG_ 994 Pers4OptIn_B_Stats 1;
BA_ "U_UP375_MY15_Gas_Rx" SG_ 994 Pers4OptIn_B_Stats 1;
BA_ "U_UP375_MY15_Diesel_Rx" SG_ 994 Pers4OptIn_B_Stats 1;
BA_ "U_CD43_MY16_Gas_Rx" SG_ 994 Pers4OptIn_B_Stats 1;
BA_ "U_CD4_MY14_Diesel_Rx" SG_ 994 Pers4OptIn_B_Stats 1;
BA_ "U_CD4_MY14_Gas_Rx" SG_ 994 Pers4OptIn_B_Stats 1;
BA_ "U_CD4_MY14_Hev_Rx" SG_ 994 Pers4OptIn_B_Stats 1;
BA_ "U_CD4_MY14_Phev_Rx" SG_ 994 Pers4OptIn_B_Stats 1;
BA_ "U_CD4_MY13_Diesel_Tx" SG_ 994 Pers4OptIn_B_Stats 1;
BA_ "U_CD4_MY13_Gas_Tx" SG_ 994 Pers4OptIn_B_Stats 1;
BA_ "U_CD4_MY13_Hev_Tx" SG_ 994 Pers4OptIn_B_Stats 1;
BA_ "U_CD4_MY13_Phev_Tx" SG_ 994 Pers4OptIn_B_Stats 1;
BA_ "U_CD42_MY14_Diesel_Tx" SG_ 994 Pers4OptIn_B_Stats 1;
BA_ "U_CD42_MY14_Gas_Tx" SG_ 994 Pers4OptIn_B_Stats 1;
BA_ "U_P552_MY15_Gas_Tx" SG_ 994 Pers4OptIn_B_Stats 1;
BA_ "U_S550_MY15_Gas_Tx" SG_ 994 Pers4OptIn_B_Stats 1;
BA_ "U_C489_MY14_Gas_Tx" SG_ 994 Pers4OptIn_B_Stats 1;
BA_ "U_U502_MY15_Gas_Tx" SG_ 994 Pers4OptIn_B_Stats 1;
BA_ "U_CD43_MY16_Gas_Tx" SG_ 994 Pers4OptIn_B_Stats 1;
BA_ "U_CD4_MY14_Diesel_Tx" SG_ 994 Pers4OptIn_B_Stats 1;
BA_ "U_CD4_MY14_Gas_Tx" SG_ 994 Pers4OptIn_B_Stats 1;
BA_ "U_CD4_MY14_Hev_Tx" SG_ 994 Pers4OptIn_B_Stats 1;
BA_ "U_CD4_MY14_Phev_Tx" SG_ 994 Pers4OptIn_B_Stats 1;
BA_ "CrossOver_InfoCAN" SG_ 994 Pers3OptIn_B_Stats 1;
BA_ "GenSigSendType" SG_ 994 Pers3OptIn_B_Stats 3;
BA_ "U_CD4_MY13_Diesel_Rx" SG_ 994 Pers3OptIn_B_Stats 1;
BA_ "U_CD4_MY13_Gas_Rx" SG_ 994 Pers3OptIn_B_Stats 1;
BA_ "U_CD4_MY13_Hev_Rx" SG_ 994 Pers3OptIn_B_Stats 1;
BA_ "U_CD4_MY13_Phev_Rx" SG_ 994 Pers3OptIn_B_Stats 1;
BA_ "U_CD42_MY14_Diesel_Rx" SG_ 994 Pers3OptIn_B_Stats 1;
BA_ "U_CD42_MY14_Gas_Rx" SG_ 994 Pers3OptIn_B_Stats 1;
BA_ "U_P552_MY15_Gas_Rx" SG_ 994 Pers3OptIn_B_Stats 1;
BA_ "U_S550_MY15_Gas_Rx" SG_ 994 Pers3OptIn_B_Stats 1;
BA_ "U_C489_MY14_Gas_Rx" SG_ 994 Pers3OptIn_B_Stats 1;
BA_ "U_U502_MY15_Gas_Rx" SG_ 994 Pers3OptIn_B_Stats 1;
BA_ "U_UP375_MY15_Gas_Rx" SG_ 994 Pers3OptIn_B_Stats 1;
BA_ "U_UP375_MY15_Diesel_Rx" SG_ 994 Pers3OptIn_B_Stats 1;
BA_ "U_CD43_MY16_Gas_Rx" SG_ 994 Pers3OptIn_B_Stats 1;
BA_ "U_CD4_MY14_Diesel_Rx" SG_ 994 Pers3OptIn_B_Stats 1;
BA_ "U_CD4_MY14_Gas_Rx" SG_ 994 Pers3OptIn_B_Stats 1;
BA_ "U_CD4_MY14_Hev_Rx" SG_ 994 Pers3OptIn_B_Stats 1;
BA_ "U_CD4_MY14_Phev_Rx" SG_ 994 Pers3OptIn_B_Stats 1;
BA_ "U_CD4_MY13_Diesel_Tx" SG_ 994 Pers3OptIn_B_Stats 1;
BA_ "U_CD4_MY13_Gas_Tx" SG_ 994 Pers3OptIn_B_Stats 1;
BA_ "U_CD4_MY13_Hev_Tx" SG_ 994 Pers3OptIn_B_Stats 1;
BA_ "U_CD4_MY13_Phev_Tx" SG_ 994 Pers3OptIn_B_Stats 1;
BA_ "U_CD42_MY14_Diesel_Tx" SG_ 994 Pers3OptIn_B_Stats 1;
BA_ "U_CD42_MY14_Gas_Tx" SG_ 994 Pers3OptIn_B_Stats 1;
BA_ "U_P552_MY15_Gas_Tx" SG_ 994 Pers3OptIn_B_Stats 1;
BA_ "U_S550_MY15_Gas_Tx" SG_ 994 Pers3OptIn_B_Stats 1;
BA_ "U_C489_MY14_Gas_Tx" SG_ 994 Pers3OptIn_B_Stats 1;
BA_ "U_U502_MY15_Gas_Tx" SG_ 994 Pers3OptIn_B_Stats 1;
BA_ "U_CD43_MY16_Gas_Tx" SG_ 994 Pers3OptIn_B_Stats 1;
BA_ "U_CD4_MY14_Diesel_Tx" SG_ 994 Pers3OptIn_B_Stats 1;
BA_ "U_CD4_MY14_Gas_Tx" SG_ 994 Pers3OptIn_B_Stats 1;
BA_ "U_CD4_MY14_Hev_Tx" SG_ 994 Pers3OptIn_B_Stats 1;
BA_ "U_CD4_MY14_Phev_Tx" SG_ 994 Pers3OptIn_B_Stats 1;
BA_ "CrossOver_InfoCAN" SG_ 994 Pers2OptIn_B_Stats 1;
BA_ "GenSigSendType" SG_ 994 Pers2OptIn_B_Stats 3;
BA_ "U_CD4_MY13_Diesel_Rx" SG_ 994 Pers2OptIn_B_Stats 1;
BA_ "U_CD4_MY13_Gas_Rx" SG_ 994 Pers2OptIn_B_Stats 1;
BA_ "U_CD4_MY13_Hev_Rx" SG_ 994 Pers2OptIn_B_Stats 1;
BA_ "U_CD4_MY13_Phev_Rx" SG_ 994 Pers2OptIn_B_Stats 1;
BA_ "U_CD42_MY14_Diesel_Rx" SG_ 994 Pers2OptIn_B_Stats 1;
BA_ "U_CD42_MY14_Gas_Rx" SG_ 994 Pers2OptIn_B_Stats 1;
BA_ "U_P552_MY15_Gas_Rx" SG_ 994 Pers2OptIn_B_Stats 1;
BA_ "U_S550_MY15_Gas_Rx" SG_ 994 Pers2OptIn_B_Stats 1;
BA_ "U_C489_MY14_Gas_Rx" SG_ 994 Pers2OptIn_B_Stats 1;
BA_ "U_U502_MY15_Gas_Rx" SG_ 994 Pers2OptIn_B_Stats 1;
BA_ "U_UP375_MY15_Gas_Rx" SG_ 994 Pers2OptIn_B_Stats 1;
BA_ "U_UP375_MY15_Diesel_Rx" SG_ 994 Pers2OptIn_B_Stats 1;
BA_ "U_CD43_MY16_Gas_Rx" SG_ 994 Pers2OptIn_B_Stats 1;
BA_ "U_CD4_MY14_Diesel_Rx" SG_ 994 Pers2OptIn_B_Stats 1;
BA_ "U_CD4_MY14_Gas_Rx" SG_ 994 Pers2OptIn_B_Stats 1;
BA_ "U_CD4_MY14_Hev_Rx" SG_ 994 Pers2OptIn_B_Stats 1;
BA_ "U_CD4_MY14_Phev_Rx" SG_ 994 Pers2OptIn_B_Stats 1;
BA_ "U_CD4_MY13_Diesel_Tx" SG_ 994 Pers2OptIn_B_Stats 1;
BA_ "U_CD4_MY13_Gas_Tx" SG_ 994 Pers2OptIn_B_Stats 1;
BA_ "U_CD4_MY13_Hev_Tx" SG_ 994 Pers2OptIn_B_Stats 1;
BA_ "U_CD4_MY13_Phev_Tx" SG_ 994 Pers2OptIn_B_Stats 1;
BA_ "U_CD42_MY14_Diesel_Tx" SG_ 994 Pers2OptIn_B_Stats 1;
BA_ "U_CD42_MY14_Gas_Tx" SG_ 994 Pers2OptIn_B_Stats 1;
BA_ "U_P552_MY15_Gas_Tx" SG_ 994 Pers2OptIn_B_Stats 1;
BA_ "U_S550_MY15_Gas_Tx" SG_ 994 Pers2OptIn_B_Stats 1;
BA_ "U_C489_MY14_Gas_Tx" SG_ 994 Pers2OptIn_B_Stats 1;
BA_ "U_U502_MY15_Gas_Tx" SG_ 994 Pers2OptIn_B_Stats 1;
BA_ "U_CD43_MY16_Gas_Tx" SG_ 994 Pers2OptIn_B_Stats 1;
BA_ "U_CD4_MY14_Diesel_Tx" SG_ 994 Pers2OptIn_B_Stats 1;
BA_ "U_CD4_MY14_Gas_Tx" SG_ 994 Pers2OptIn_B_Stats 1;
BA_ "U_CD4_MY14_Hev_Tx" SG_ 994 Pers2OptIn_B_Stats 1;
BA_ "U_CD4_MY14_Phev_Tx" SG_ 994 Pers2OptIn_B_Stats 1;
BA_ "CrossOver_InfoCAN" SG_ 994 Pers1OptIn_B_Stats 1;
BA_ "GenSigSendType" SG_ 994 Pers1OptIn_B_Stats 3;
BA_ "U_CD4_MY13_Diesel_Rx" SG_ 994 Pers1OptIn_B_Stats 1;
BA_ "U_CD4_MY13_Gas_Rx" SG_ 994 Pers1OptIn_B_Stats 1;
BA_ "U_CD4_MY13_Hev_Rx" SG_ 994 Pers1OptIn_B_Stats 1;
BA_ "U_CD4_MY13_Phev_Rx" SG_ 994 Pers1OptIn_B_Stats 1;
BA_ "U_CD42_MY14_Diesel_Rx" SG_ 994 Pers1OptIn_B_Stats 1;
BA_ "U_CD42_MY14_Gas_Rx" SG_ 994 Pers1OptIn_B_Stats 1;
BA_ "U_P552_MY15_Gas_Rx" SG_ 994 Pers1OptIn_B_Stats 1;
BA_ "U_S550_MY15_Gas_Rx" SG_ 994 Pers1OptIn_B_Stats 1;
BA_ "U_C489_MY14_Gas_Rx" SG_ 994 Pers1OptIn_B_Stats 1;
BA_ "U_U502_MY15_Gas_Rx" SG_ 994 Pers1OptIn_B_Stats 1;
BA_ "U_UP375_MY15_Gas_Rx" SG_ 994 Pers1OptIn_B_Stats 1;
BA_ "U_UP375_MY15_Diesel_Rx" SG_ 994 Pers1OptIn_B_Stats 1;
BA_ "U_CD43_MY16_Gas_Rx" SG_ 994 Pers1OptIn_B_Stats 1;
BA_ "U_CD4_MY14_Diesel_Rx" SG_ 994 Pers1OptIn_B_Stats 1;
BA_ "U_CD4_MY14_Gas_Rx" SG_ 994 Pers1OptIn_B_Stats 1;
BA_ "U_CD4_MY14_Hev_Rx" SG_ 994 Pers1OptIn_B_Stats 1;
BA_ "U_CD4_MY14_Phev_Rx" SG_ 994 Pers1OptIn_B_Stats 1;
BA_ "U_CD4_MY13_Diesel_Tx" SG_ 994 Pers1OptIn_B_Stats 1;
BA_ "U_CD4_MY13_Gas_Tx" SG_ 994 Pers1OptIn_B_Stats 1;
BA_ "U_CD4_MY13_Hev_Tx" SG_ 994 Pers1OptIn_B_Stats 1;
BA_ "U_CD4_MY13_Phev_Tx" SG_ 994 Pers1OptIn_B_Stats 1;
BA_ "U_CD42_MY14_Diesel_Tx" SG_ 994 Pers1OptIn_B_Stats 1;
BA_ "U_CD42_MY14_Gas_Tx" SG_ 994 Pers1OptIn_B_Stats 1;
BA_ "U_P552_MY15_Gas_Tx" SG_ 994 Pers1OptIn_B_Stats 1;
BA_ "U_S550_MY15_Gas_Tx" SG_ 994 Pers1OptIn_B_Stats 1;
BA_ "U_C489_MY14_Gas_Tx" SG_ 994 Pers1OptIn_B_Stats 1;
BA_ "U_U502_MY15_Gas_Tx" SG_ 994 Pers1OptIn_B_Stats 1;
BA_ "U_CD43_MY16_Gas_Tx" SG_ 994 Pers1OptIn_B_Stats 1;
BA_ "U_CD4_MY14_Diesel_Tx" SG_ 994 Pers1OptIn_B_Stats 1;
BA_ "U_CD4_MY14_Gas_Tx" SG_ 994 Pers1OptIn_B_Stats 1;
BA_ "U_CD4_MY14_Hev_Tx" SG_ 994 Pers1OptIn_B_Stats 1;
BA_ "U_CD4_MY14_Phev_Tx" SG_ 994 Pers1OptIn_B_Stats 1;
BA_ "CrossOver_InfoCAN" SG_ 994 CtrStkPersIndex_D_Actl 1;
BA_ "GenSigStartValue" SG_ 994 CtrStkPersIndex_D_Actl 4;
BA_ "GenSigSendType" SG_ 994 CtrStkPersIndex_D_Actl 3;
BA_ "U_CD4_MY13_Diesel_Rx" SG_ 994 CtrStkPersIndex_D_Actl 1;
BA_ "U_CD4_MY13_Gas_Rx" SG_ 994 CtrStkPersIndex_D_Actl 1;
BA_ "U_CD4_MY13_Hev_Rx" SG_ 994 CtrStkPersIndex_D_Actl 1;
BA_ "U_CD4_MY13_Phev_Rx" SG_ 994 CtrStkPersIndex_D_Actl 1;
BA_ "U_CD42_MY14_Diesel_Rx" SG_ 994 CtrStkPersIndex_D_Actl 1;
BA_ "U_CD42_MY14_Gas_Rx" SG_ 994 CtrStkPersIndex_D_Actl 1;
BA_ "U_P552_MY15_Gas_Rx" SG_ 994 CtrStkPersIndex_D_Actl 1;
BA_ "U_S550_MY15_Gas_Rx" SG_ 994 CtrStkPersIndex_D_Actl 1;
BA_ "U_C489_MY14_Gas_Rx" SG_ 994 CtrStkPersIndex_D_Actl 1;
BA_ "U_U502_MY15_Gas_Rx" SG_ 994 CtrStkPersIndex_D_Actl 1;
BA_ "U_UP375_MY15_Gas_Rx" SG_ 994 CtrStkPersIndex_D_Actl 1;
BA_ "U_UP375_MY15_Diesel_Rx" SG_ 994 CtrStkPersIndex_D_Actl 1;
BA_ "U_CD43_MY16_Gas_Rx" SG_ 994 CtrStkPersIndex_D_Actl 1;
BA_ "U_CD4_MY14_Diesel_Rx" SG_ 994 CtrStkPersIndex_D_Actl 1;
BA_ "U_CD4_MY14_Gas_Rx" SG_ 994 CtrStkPersIndex_D_Actl 1;
BA_ "U_CD4_MY14_Hev_Rx" SG_ 994 CtrStkPersIndex_D_Actl 1;
BA_ "U_CD4_MY14_Phev_Rx" SG_ 994 CtrStkPersIndex_D_Actl 1;
BA_ "U_CD4_MY13_Diesel_Tx" SG_ 994 CtrStkPersIndex_D_Actl 1;
BA_ "U_CD4_MY13_Gas_Tx" SG_ 994 CtrStkPersIndex_D_Actl 1;
BA_ "U_CD4_MY13_Hev_Tx" SG_ 994 CtrStkPersIndex_D_Actl 1;
BA_ "U_CD4_MY13_Phev_Tx" SG_ 994 CtrStkPersIndex_D_Actl 1;
BA_ "U_CD42_MY14_Diesel_Tx" SG_ 994 CtrStkPersIndex_D_Actl 1;
BA_ "U_CD42_MY14_Gas_Tx" SG_ 994 CtrStkPersIndex_D_Actl 1;
BA_ "U_P552_MY15_Gas_Tx" SG_ 994 CtrStkPersIndex_D_Actl 1;
BA_ "U_S550_MY15_Gas_Tx" SG_ 994 CtrStkPersIndex_D_Actl 1;
BA_ "U_C489_MY14_Gas_Tx" SG_ 994 CtrStkPersIndex_D_Actl 1;
BA_ "U_U502_MY15_Gas_Tx" SG_ 994 CtrStkPersIndex_D_Actl 1;
BA_ "U_CD43_MY16_Gas_Tx" SG_ 994 CtrStkPersIndex_D_Actl 1;
BA_ "U_CD4_MY14_Diesel_Tx" SG_ 994 CtrStkPersIndex_D_Actl 1;
BA_ "U_CD4_MY14_Gas_Tx" SG_ 994 CtrStkPersIndex_D_Actl 1;
BA_ "U_CD4_MY14_Hev_Tx" SG_ 994 CtrStkPersIndex_D_Actl 1;
BA_ "U_CD4_MY14_Phev_Tx" SG_ 994 CtrStkPersIndex_D_Actl 1;
BA_ "CrossOver_InfoCAN" SG_ 994 CtrStkFeatNoActl 1;
BA_ "GenSigSendType" SG_ 994 CtrStkFeatNoActl 3;
BA_ "U_CD4_MY13_Diesel_Rx" SG_ 994 CtrStkFeatNoActl 1;
BA_ "U_CD4_MY13_Gas_Rx" SG_ 994 CtrStkFeatNoActl 1;
BA_ "U_CD4_MY13_Hev_Rx" SG_ 994 CtrStkFeatNoActl 1;
BA_ "U_CD4_MY13_Phev_Rx" SG_ 994 CtrStkFeatNoActl 1;
BA_ "U_CD42_MY14_Diesel_Rx" SG_ 994 CtrStkFeatNoActl 1;
BA_ "U_CD42_MY14_Gas_Rx" SG_ 994 CtrStkFeatNoActl 1;
BA_ "U_P552_MY15_Gas_Rx" SG_ 994 CtrStkFeatNoActl 1;
BA_ "U_S550_MY15_Gas_Rx" SG_ 994 CtrStkFeatNoActl 1;
BA_ "U_C489_MY14_Gas_Rx" SG_ 994 CtrStkFeatNoActl 1;
BA_ "U_U502_MY15_Gas_Rx" SG_ 994 CtrStkFeatNoActl 1;
BA_ "U_UP375_MY15_Gas_Rx" SG_ 994 CtrStkFeatNoActl 1;
BA_ "U_UP375_MY15_Diesel_Rx" SG_ 994 CtrStkFeatNoActl 1;
BA_ "U_CD43_MY16_Gas_Rx" SG_ 994 CtrStkFeatNoActl 1;
BA_ "U_CD4_MY14_Diesel_Rx" SG_ 994 CtrStkFeatNoActl 1;
BA_ "U_CD4_MY14_Gas_Rx" SG_ 994 CtrStkFeatNoActl 1;
BA_ "U_CD4_MY14_Hev_Rx" SG_ 994 CtrStkFeatNoActl 1;
BA_ "U_CD4_MY14_Phev_Rx" SG_ 994 CtrStkFeatNoActl 1;
BA_ "U_CD4_MY13_Diesel_Tx" SG_ 994 CtrStkFeatNoActl 1;
BA_ "U_CD4_MY13_Gas_Tx" SG_ 994 CtrStkFeatNoActl 1;
BA_ "U_CD4_MY13_Hev_Tx" SG_ 994 CtrStkFeatNoActl 1;
BA_ "U_CD4_MY13_Phev_Tx" SG_ 994 CtrStkFeatNoActl 1;
BA_ "U_CD42_MY14_Diesel_Tx" SG_ 994 CtrStkFeatNoActl 1;
BA_ "U_CD42_MY14_Gas_Tx" SG_ 994 CtrStkFeatNoActl 1;
BA_ "U_P552_MY15_Gas_Tx" SG_ 994 CtrStkFeatNoActl 1;
BA_ "U_S550_MY15_Gas_Tx" SG_ 994 CtrStkFeatNoActl 1;
BA_ "U_C489_MY14_Gas_Tx" SG_ 994 CtrStkFeatNoActl 1;
BA_ "U_U502_MY15_Gas_Tx" SG_ 994 CtrStkFeatNoActl 1;
BA_ "U_CD43_MY16_Gas_Tx" SG_ 994 CtrStkFeatNoActl 1;
BA_ "U_CD4_MY14_Diesel_Tx" SG_ 994 CtrStkFeatNoActl 1;
BA_ "U_CD4_MY14_Gas_Tx" SG_ 994 CtrStkFeatNoActl 1;
BA_ "U_CD4_MY14_Hev_Tx" SG_ 994 CtrStkFeatNoActl 1;
BA_ "U_CD4_MY14_Phev_Tx" SG_ 994 CtrStkFeatNoActl 1;
BA_ "CrossOver_InfoCAN" SG_ 994 CtrStkFeatConfigActl 1;
BA_ "GenSigSendType" SG_ 994 CtrStkFeatConfigActl 3;
BA_ "U_CD4_MY13_Diesel_Rx" SG_ 994 CtrStkFeatConfigActl 1;
BA_ "U_CD4_MY13_Gas_Rx" SG_ 994 CtrStkFeatConfigActl 1;
BA_ "U_CD4_MY13_Hev_Rx" SG_ 994 CtrStkFeatConfigActl 1;
BA_ "U_CD4_MY13_Phev_Rx" SG_ 994 CtrStkFeatConfigActl 1;
BA_ "U_CD42_MY14_Diesel_Rx" SG_ 994 CtrStkFeatConfigActl 1;
BA_ "U_CD42_MY14_Gas_Rx" SG_ 994 CtrStkFeatConfigActl 1;
BA_ "U_P552_MY15_Gas_Rx" SG_ 994 CtrStkFeatConfigActl 1;
BA_ "U_S550_MY15_Gas_Rx" SG_ 994 CtrStkFeatConfigActl 1;
BA_ "U_C489_MY14_Gas_Rx" SG_ 994 CtrStkFeatConfigActl 1;
BA_ "U_U502_MY15_Gas_Rx" SG_ 994 CtrStkFeatConfigActl 1;
BA_ "U_UP375_MY15_Gas_Rx" SG_ 994 CtrStkFeatConfigActl 1;
BA_ "U_UP375_MY15_Diesel_Rx" SG_ 994 CtrStkFeatConfigActl 1;
BA_ "U_CD43_MY16_Gas_Rx" SG_ 994 CtrStkFeatConfigActl 1;
BA_ "U_CD4_MY14_Diesel_Rx" SG_ 994 CtrStkFeatConfigActl 1;
BA_ "U_CD4_MY14_Gas_Rx" SG_ 994 CtrStkFeatConfigActl 1;
BA_ "U_CD4_MY14_Hev_Rx" SG_ 994 CtrStkFeatConfigActl 1;
BA_ "U_CD4_MY14_Phev_Rx" SG_ 994 CtrStkFeatConfigActl 1;
BA_ "U_CD4_MY13_Diesel_Tx" SG_ 994 CtrStkFeatConfigActl 1;
BA_ "U_CD4_MY13_Gas_Tx" SG_ 994 CtrStkFeatConfigActl 1;
BA_ "U_CD4_MY13_Hev_Tx" SG_ 994 CtrStkFeatConfigActl 1;
BA_ "U_CD4_MY13_Phev_Tx" SG_ 994 CtrStkFeatConfigActl 1;
BA_ "U_CD42_MY14_Diesel_Tx" SG_ 994 CtrStkFeatConfigActl 1;
BA_ "U_CD42_MY14_Gas_Tx" SG_ 994 CtrStkFeatConfigActl 1;
BA_ "U_P552_MY15_Gas_Tx" SG_ 994 CtrStkFeatConfigActl 1;
BA_ "U_S550_MY15_Gas_Tx" SG_ 994 CtrStkFeatConfigActl 1;
BA_ "U_C489_MY14_Gas_Tx" SG_ 994 CtrStkFeatConfigActl 1;
BA_ "U_U502_MY15_Gas_Tx" SG_ 994 CtrStkFeatConfigActl 1;
BA_ "U_CD43_MY16_Gas_Tx" SG_ 994 CtrStkFeatConfigActl 1;
BA_ "U_CD4_MY14_Diesel_Tx" SG_ 994 CtrStkFeatConfigActl 1;
BA_ "U_CD4_MY14_Gas_Tx" SG_ 994 CtrStkFeatConfigActl 1;
BA_ "U_CD4_MY14_Hev_Tx" SG_ 994 CtrStkFeatConfigActl 1;
BA_ "U_CD4_MY14_Phev_Tx" SG_ 994 CtrStkFeatConfigActl 1;
BA_ "CrossOver_InfoCAN" SG_ 994 CtrStkDsplyOp_D_Rq 1;
BA_ "GenSigSendType" SG_ 994 CtrStkDsplyOp_D_Rq 3;
BA_ "U_CD4_MY13_Diesel_Rx" SG_ 994 CtrStkDsplyOp_D_Rq 1;
BA_ "U_CD4_MY13_Gas_Rx" SG_ 994 CtrStkDsplyOp_D_Rq 1;
BA_ "U_CD4_MY13_Hev_Rx" SG_ 994 CtrStkDsplyOp_D_Rq 1;
BA_ "U_CD4_MY13_Phev_Rx" SG_ 994 CtrStkDsplyOp_D_Rq 1;
BA_ "U_CD42_MY14_Diesel_Rx" SG_ 994 CtrStkDsplyOp_D_Rq 1;
BA_ "U_CD42_MY14_Gas_Rx" SG_ 994 CtrStkDsplyOp_D_Rq 1;
BA_ "U_P552_MY15_Gas_Rx" SG_ 994 CtrStkDsplyOp_D_Rq 1;
BA_ "U_S550_MY15_Gas_Rx" SG_ 994 CtrStkDsplyOp_D_Rq 1;
BA_ "U_C489_MY14_Gas_Rx" SG_ 994 CtrStkDsplyOp_D_Rq 1;
BA_ "U_U502_MY15_Gas_Rx" SG_ 994 CtrStkDsplyOp_D_Rq 1;
BA_ "U_UP375_MY15_Gas_Rx" SG_ 994 CtrStkDsplyOp_D_Rq 1;
BA_ "U_UP375_MY15_Diesel_Rx" SG_ 994 CtrStkDsplyOp_D_Rq 1;
BA_ "U_CD43_MY16_Gas_Rx" SG_ 994 CtrStkDsplyOp_D_Rq 1;
BA_ "U_CD4_MY14_Diesel_Rx" SG_ 994 CtrStkDsplyOp_D_Rq 1;
BA_ "U_CD4_MY14_Gas_Rx" SG_ 994 CtrStkDsplyOp_D_Rq 1;
BA_ "U_CD4_MY14_Hev_Rx" SG_ 994 CtrStkDsplyOp_D_Rq 1;
BA_ "U_CD4_MY14_Phev_Rx" SG_ 994 CtrStkDsplyOp_D_Rq 1;
BA_ "U_CD4_MY13_Diesel_Tx" SG_ 994 CtrStkDsplyOp_D_Rq 1;
BA_ "U_CD4_MY13_Gas_Tx" SG_ 994 CtrStkDsplyOp_D_Rq 1;
BA_ "U_CD4_MY13_Hev_Tx" SG_ 994 CtrStkDsplyOp_D_Rq 1;
BA_ "U_CD4_MY13_Phev_Tx" SG_ 994 CtrStkDsplyOp_D_Rq 1;
BA_ "U_CD42_MY14_Diesel_Tx" SG_ 994 CtrStkDsplyOp_D_Rq 1;
BA_ "U_CD42_MY14_Gas_Tx" SG_ 994 CtrStkDsplyOp_D_Rq 1;
BA_ "U_P552_MY15_Gas_Tx" SG_ 994 CtrStkDsplyOp_D_Rq 1;
BA_ "U_S550_MY15_Gas_Tx" SG_ 994 CtrStkDsplyOp_D_Rq 1;
BA_ "U_C489_MY14_Gas_Tx" SG_ 994 CtrStkDsplyOp_D_Rq 1;
BA_ "U_U502_MY15_Gas_Tx" SG_ 994 CtrStkDsplyOp_D_Rq 1;
BA_ "U_CD43_MY16_Gas_Tx" SG_ 994 CtrStkDsplyOp_D_Rq 1;
BA_ "U_CD4_MY14_Diesel_Tx" SG_ 994 CtrStkDsplyOp_D_Rq 1;
BA_ "U_CD4_MY14_Gas_Tx" SG_ 994 CtrStkDsplyOp_D_Rq 1;
BA_ "U_CD4_MY14_Hev_Tx" SG_ 994 CtrStkDsplyOp_D_Rq 1;
BA_ "U_CD4_MY14_Phev_Tx" SG_ 994 CtrStkDsplyOp_D_Rq 1;
BA_ "U_CD4_MY13_Gas_Tx" SG_ 512 PrplWhlTot_Tq_Rq 1;
BA_ "U_CD42_MY14_Gas_Tx" SG_ 512 PrplWhlTot_Tq_Rq 1;
BA_ "U_P552_MY15_Gas_Tx" SG_ 512 PrplWhlTot_Tq_Rq 1;
BA_ "U_S550_MY15_Gas_Tx" SG_ 512 PrplWhlTot_Tq_Rq 1;
BA_ "U_C489_MY14_Gas_Tx" SG_ 512 PrplWhlTot_Tq_Rq 1;
BA_ "U_U502_MY15_Gas_Tx" SG_ 512 PrplWhlTot_Tq_Rq 1;
BA_ "U_UP375_MY15_Gas_Tx" SG_ 512 PrplWhlTot_Tq_Rq 1;
BA_ "U_CD43_MY16_Gas_Tx" SG_ 512 PrplWhlTot_Tq_Rq 1;
BA_ "U_CD4_MY14_Gas_Tx" SG_ 512 PrplWhlTot_Tq_Rq 1;
BA_ "U_CD4_MY13_Gas_Tx" SG_ 512 PrplWhlTot_Tq_LimMn 1;
BA_ "U_CD42_MY14_Gas_Tx" SG_ 512 PrplWhlTot_Tq_LimMn 1;
BA_ "U_P552_MY15_Gas_Tx" SG_ 512 PrplWhlTot_Tq_LimMn 1;
BA_ "U_S550_MY15_Gas_Tx" SG_ 512 PrplWhlTot_Tq_LimMn 1;
BA_ "U_C489_MY14_Gas_Tx" SG_ 512 PrplWhlTot_Tq_LimMn 1;
BA_ "U_U502_MY15_Gas_Tx" SG_ 512 PrplWhlTot_Tq_LimMn 1;
BA_ "U_UP375_MY15_Gas_Tx" SG_ 512 PrplWhlTot_Tq_LimMn 1;
BA_ "U_CD43_MY16_Gas_Tx" SG_ 512 PrplWhlTot_Tq_LimMn 1;
BA_ "U_CD4_MY14_Gas_Tx" SG_ 512 PrplWhlTot_Tq_LimMn 1;
BA_ "ContentDependant" SG_ 512 PtDrvMde_D_Stat 1;
BA_ "U_P552_MY15_Gas_Tx" SG_ 512 PtDrvMde_D_Stat 1;
BA_ "U_S550_MY15_Gas_Tx" SG_ 512 PtDrvMde_D_Stat 1;
BA_ "U_CD43_MY16_Gas_Tx" SG_ 512 PtDrvMde_D_Stat 1;
BA_ "U_CD4_MY13_Gas_Rx" SG_ 65 immoControlData_T1 1;
BA_ "U_CD42_MY14_Gas_Rx" SG_ 65 immoControlData_T1 1;
BA_ "U_P552_MY15_Gas_Rx" SG_ 65 immoControlData_T1 1;
BA_ "U_S550_MY15_Gas_Rx" SG_ 65 immoControlData_T1 1;
BA_ "U_C489_MY14_Gas_Rx" SG_ 65 immoControlData_T1 1;
BA_ "U_U502_MY15_Gas_Rx" SG_ 65 immoControlData_T1 1;
BA_ "U_UP375_MY15_Gas_Rx" SG_ 65 immoControlData_T1 1;
BA_ "U_CD43_MY16_Gas_Rx" SG_ 65 immoControlData_T1 1;
BA_ "U_CD4_MY14_Gas_Rx" SG_ 65 immoControlData_T1 1;
BA_ "U_CD4_MY13_Diesel_Tx" SG_ 65 immoControlData_T1 1;
BA_ "U_CD4_MY13_Gas_Tx" SG_ 65 immoControlData_T1 1;
BA_ "U_CD4_MY13_Hev_Tx" SG_ 65 immoControlData_T1 1;
BA_ "U_CD4_MY13_Phev_Tx" SG_ 65 immoControlData_T1 1;
BA_ "U_CD42_MY14_Diesel_Tx" SG_ 65 immoControlData_T1 1;
BA_ "U_CD42_MY14_Gas_Tx" SG_ 65 immoControlData_T1 1;
BA_ "U_P552_MY15_Gas_Tx" SG_ 65 immoControlData_T1 1;
BA_ "U_S550_MY15_Gas_Tx" SG_ 65 immoControlData_T1 1;
BA_ "U_C489_MY14_Gas_Tx" SG_ 65 immoControlData_T1 1;
BA_ "U_U502_MY15_Gas_Tx" SG_ 65 immoControlData_T1 1;
BA_ "U_UP375_MY15_Gas_Tx" SG_ 65 immoControlData_T1 1;
BA_ "U_UP375_MY15_Diesel_Tx" SG_ 65 immoControlData_T1 1;
BA_ "U_CD43_MY16_Gas_Tx" SG_ 65 immoControlData_T1 1;
BA_ "U_CD4_MY14_Diesel_Tx" SG_ 65 immoControlData_T1 1;
BA_ "U_CD4_MY14_Gas_Tx" SG_ 65 immoControlData_T1 1;
BA_ "U_CD4_MY14_Hev_Tx" SG_ 65 immoControlData_T1 1;
BA_ "U_CD4_MY14_Phev_Tx" SG_ 65 immoControlData_T1 1;
BA_ "U_CD4_MY13_Gas_Rx" SG_ 65 immoControlCmd_T1 1;
BA_ "U_CD42_MY14_Gas_Rx" SG_ 65 immoControlCmd_T1 1;
BA_ "U_P552_MY15_Gas_Rx" SG_ 65 immoControlCmd_T1 1;
BA_ "U_S550_MY15_Gas_Rx" SG_ 65 immoControlCmd_T1 1;
BA_ "U_C489_MY14_Gas_Rx" SG_ 65 immoControlCmd_T1 1;
BA_ "U_U502_MY15_Gas_Rx" SG_ 65 immoControlCmd_T1 1;
BA_ "U_UP375_MY15_Gas_Rx" SG_ 65 immoControlCmd_T1 1;
BA_ "U_CD43_MY16_Gas_Rx" SG_ 65 immoControlCmd_T1 1;
BA_ "U_CD4_MY14_Gas_Rx" SG_ 65 immoControlCmd_T1 1;
BA_ "U_CD4_MY13_Diesel_Tx" SG_ 65 immoControlCmd_T1 1;
BA_ "U_CD4_MY13_Gas_Tx" SG_ 65 immoControlCmd_T1 1;
BA_ "U_CD4_MY13_Hev_Tx" SG_ 65 immoControlCmd_T1 1;
BA_ "U_CD4_MY13_Phev_Tx" SG_ 65 immoControlCmd_T1 1;
BA_ "U_CD42_MY14_Diesel_Tx" SG_ 65 immoControlCmd_T1 1;
BA_ "U_CD42_MY14_Gas_Tx" SG_ 65 immoControlCmd_T1 1;
BA_ "U_P552_MY15_Gas_Tx" SG_ 65 immoControlCmd_T1 1;
BA_ "U_S550_MY15_Gas_Tx" SG_ 65 immoControlCmd_T1 1;
BA_ "U_C489_MY14_Gas_Tx" SG_ 65 immoControlCmd_T1 1;
BA_ "U_U502_MY15_Gas_Tx" SG_ 65 immoControlCmd_T1 1;
BA_ "U_UP375_MY15_Gas_Tx" SG_ 65 immoControlCmd_T1 1;
BA_ "U_UP375_MY15_Diesel_Tx" SG_ 65 immoControlCmd_T1 1;
BA_ "U_CD43_MY16_Gas_Tx" SG_ 65 immoControlCmd_T1 1;
BA_ "U_CD4_MY14_Diesel_Tx" SG_ 65 immoControlCmd_T1 1;
BA_ "U_CD4_MY14_Gas_Tx" SG_ 65 immoControlCmd_T1 1;
BA_ "U_CD4_MY14_Hev_Tx" SG_ 65 immoControlCmd_T1 1;
BA_ "U_CD4_MY14_Phev_Tx" SG_ 65 immoControlCmd_T1 1;
BA_ "GenSigSendType" SG_ 1838 TesterPhysicalResBCM 3;
BA_ "U_CD4_MY13_Diesel_Rx" SG_ 1838 TesterPhysicalResBCM 1;
BA_ "U_CD4_MY13_Gas_Rx" SG_ 1838 TesterPhysicalResBCM 1;
BA_ "U_CD4_MY13_Hev_Rx" SG_ 1838 TesterPhysicalResBCM 1;
BA_ "U_CD4_MY13_Phev_Rx" SG_ 1838 TesterPhysicalResBCM 1;
BA_ "U_CD42_MY14_Diesel_Rx" SG_ 1838 TesterPhysicalResBCM 1;
BA_ "U_CD42_MY14_Gas_Rx" SG_ 1838 TesterPhysicalResBCM 1;
BA_ "U_P552_MY15_Gas_Rx" SG_ 1838 TesterPhysicalResBCM 1;
BA_ "U_S550_MY15_Gas_Rx" SG_ 1838 TesterPhysicalResBCM 1;
BA_ "U_C489_MY14_Gas_Rx" SG_ 1838 TesterPhysicalResBCM 1;
BA_ "U_CD4_MY13_Diesel_Tx" SG_ 1838 TesterPhysicalResBCM 1;
BA_ "U_CD4_MY13_Gas_Tx" SG_ 1838 TesterPhysicalResBCM 1;
BA_ "U_CD4_MY13_Hev_Tx" SG_ 1838 TesterPhysicalResBCM 1;
BA_ "U_CD4_MY13_Phev_Tx" SG_ 1838 TesterPhysicalResBCM 1;
BA_ "U_CD42_MY14_Diesel_Tx" SG_ 1838 TesterPhysicalResBCM 1;
BA_ "U_CD42_MY14_Gas_Tx" SG_ 1838 TesterPhysicalResBCM 1;
BA_ "U_P552_MY15_Gas_Tx" SG_ 1838 TesterPhysicalResBCM 1;
BA_ "U_S550_MY15_Gas_Tx" SG_ 1838 TesterPhysicalResBCM 1;
BA_ "U_C489_MY14_Gas_Tx" SG_ 1838 TesterPhysicalResBCM 1;
BA_ "U_U502_MY15_Gas_Tx" SG_ 1838 TesterPhysicalResBCM 1;
BA_ "U_UP375_MY15_Gas_Tx" SG_ 1838 TesterPhysicalResBCM 1;
BA_ "U_UP375_MY15_Diesel_Tx" SG_ 1838 TesterPhysicalResBCM 1;
BA_ "U_CD43_MY16_Gas_Tx" SG_ 1838 TesterPhysicalResBCM 1;
BA_ "U_CD4_MY14_Diesel_Tx" SG_ 1838 TesterPhysicalResBCM 1;
BA_ "U_CD4_MY14_Gas_Tx" SG_ 1838 TesterPhysicalResBCM 1;
BA_ "U_CD4_MY14_Hev_Tx" SG_ 1838 TesterPhysicalResBCM 1;
BA_ "U_CD4_MY14_Phev_Tx" SG_ 1838 TesterPhysicalResBCM 1;
BA_ "GenSigSendType" SG_ 1830 TesterPhysicalReqBCM 3;
BA_ "U_CD4_MY13_Diesel_Rx" SG_ 1830 TesterPhysicalReqBCM 1;
BA_ "U_CD4_MY13_Gas_Rx" SG_ 1830 TesterPhysicalReqBCM 1;
BA_ "U_CD4_MY13_Hev_Rx" SG_ 1830 TesterPhysicalReqBCM 1;
BA_ "U_CD4_MY13_Phev_Rx" SG_ 1830 TesterPhysicalReqBCM 1;
BA_ "U_CD42_MY14_Diesel_Rx" SG_ 1830 TesterPhysicalReqBCM 1;
BA_ "U_CD42_MY14_Gas_Rx" SG_ 1830 TesterPhysicalReqBCM 1;
BA_ "U_P552_MY15_Gas_Rx" SG_ 1830 TesterPhysicalReqBCM 1;
BA_ "U_S550_MY15_Gas_Rx" SG_ 1830 TesterPhysicalReqBCM 1;
BA_ "U_C489_MY14_Gas_Rx" SG_ 1830 TesterPhysicalReqBCM 1;
BA_ "U_U502_MY15_Gas_Rx" SG_ 1830 TesterPhysicalReqBCM 1;
BA_ "U_UP375_MY15_Gas_Rx" SG_ 1830 TesterPhysicalReqBCM 1;
BA_ "U_UP375_MY15_Diesel_Rx" SG_ 1830 TesterPhysicalReqBCM 1;
BA_ "U_CD43_MY16_Gas_Rx" SG_ 1830 TesterPhysicalReqBCM 1;
BA_ "U_CD4_MY14_Diesel_Rx" SG_ 1830 TesterPhysicalReqBCM 1;
BA_ "U_CD4_MY14_Gas_Rx" SG_ 1830 TesterPhysicalReqBCM 1;
BA_ "U_CD4_MY14_Hev_Rx" SG_ 1830 TesterPhysicalReqBCM 1;
BA_ "U_CD4_MY14_Phev_Rx" SG_ 1830 TesterPhysicalReqBCM 1;
BA_ "U_CD4_MY13_Diesel_Tx" SG_ 1830 TesterPhysicalReqBCM 1;
BA_ "U_CD4_MY13_Gas_Tx" SG_ 1830 TesterPhysicalReqBCM 1;
BA_ "U_CD4_MY13_Hev_Tx" SG_ 1830 TesterPhysicalReqBCM 1;
BA_ "U_CD4_MY13_Phev_Tx" SG_ 1830 TesterPhysicalReqBCM 1;
BA_ "U_CD42_MY14_Diesel_Tx" SG_ 1830 TesterPhysicalReqBCM 1;
BA_ "U_CD42_MY14_Gas_Tx" SG_ 1830 TesterPhysicalReqBCM 1;
BA_ "U_P552_MY15_Gas_Tx" SG_ 1830 TesterPhysicalReqBCM 1;
BA_ "U_S550_MY15_Gas_Tx" SG_ 1830 TesterPhysicalReqBCM 1;
BA_ "U_C489_MY14_Gas_Tx" SG_ 1830 TesterPhysicalReqBCM 1;
BA_ "U_V408_MY18_Diesel_Rx" SG_ 560 GearLvr_D_ActlDrv 1;
BA_ "U_U55x_MY18_Gas_Tx" SG_ 560 GearLvr_D_ActlDrv 1;
BA_ "U_V408_MY18_Diesel_Tx" SG_ 560 GearLvr_D_ActlDrv 1;
BA_ "U_P552_MY18_5_Gas_Tx" SG_ 560 GearLvr_D_ActlDrv 1;
BA_ "U_P552_MY18_5_Diesel_Tx" SG_ 560 GearLvr_D_ActlDrv 1;
BA_ "U_CD42_MY19_Diesel_Tx" SG_ 560 GearLvr_D_ActlDrv 1;
BA_ "U_U55x_MY18_Gas_Tx" SG_ 560 GearLvrPosActl_No_Cs 1;
BA_ "U_CD42_MY16_Diesel_Tx" SG_ 560 GearLvrPosActl_No_Cs 1;
BA_ "U_CD4_MY17_Diesel_Tx" SG_ 560 GearLvrPosActl_No_Cs 1;
BA_ "U_CD4_MY14_Diesel_Tx" SG_ 560 GearLvrPosActl_No_Cs 1;
BA_ "U_CD42_MY16_Diesel_Rx" SG_ 560 GearLvrPosActl_No_Cs 1;
BA_ "U_CD4_MY17_Diesel_Rx" SG_ 560 GearLvrPosActl_No_Cs 1;
BA_ "U_CD4_MY14_Diesel_Rx" SG_ 560 GearLvrPosActl_No_Cs 1;
BA_ "U_CD42_MY15_Diesel_Rx" SG_ 560 GearLvrPosActl_No_Cs 1;
BA_ "U_CD4_MY13_Diesel_Rx" SG_ 560 GearLvrPosActl_No_Cs 1;
BA_ "ContentDependant" SG_ 560 GearLvrPosActl_No_Cs 1;
BA_ "U_U55x_MY18_Gas_Tx" SG_ 560 GearLvrPosActl_No_Cnt 1;
BA_ "U_CD42_MY16_Diesel_Tx" SG_ 560 GearLvrPosActl_No_Cnt 1;
BA_ "U_CD4_MY17_Diesel_Tx" SG_ 560 GearLvrPosActl_No_Cnt 1;
BA_ "U_CD4_MY14_Diesel_Tx" SG_ 560 GearLvrPosActl_No_Cnt 1;
BA_ "U_CD42_MY16_Diesel_Rx" SG_ 560 GearLvrPosActl_No_Cnt 1;
BA_ "U_CD4_MY17_Diesel_Rx" SG_ 560 GearLvrPosActl_No_Cnt 1;
BA_ "U_CD4_MY14_Diesel_Rx" SG_ 560 GearLvrPosActl_No_Cnt 1;
BA_ "U_CD42_MY15_Diesel_Rx" SG_ 560 GearLvrPosActl_No_Cnt 1;
BA_ "U_CD4_MY13_Diesel_Rx" SG_ 560 GearLvrPosActl_No_Cnt 1;
BA_ "ContentDependant" SG_ 560 GearLvrPosActl_No_Cnt 1;
BA_ "CrossOver_InfoCAN" SG_ 560 TrnSrvcRqd_B_Rq 1;
BA_ "ContentDependant" SG_ 560 TrnSrvcRqd_B_Rq 1;
BA_ "U_CD4_MY13_Gas_Tx" SG_ 560 TrnSrvcRqd_B_Rq 1;
BA_ "U_CD42_MY14_Gas_Tx" SG_ 560 TrnSrvcRqd_B_Rq 1;
BA_ "U_P552_MY15_Gas_Tx" SG_ 560 TrnSrvcRqd_B_Rq 1;
BA_ "U_S550_MY15_Gas_Tx" SG_ 560 TrnSrvcRqd_B_Rq 1;
BA_ "U_C489_MY14_Gas_Tx" SG_ 560 TrnSrvcRqd_B_Rq 1;
BA_ "U_U502_MY15_Gas_Tx" SG_ 560 TrnSrvcRqd_B_Rq 1;
BA_ "U_UP375_MY15_Gas_Tx" SG_ 560 TrnSrvcRqd_B_Rq 1;
BA_ "U_CD43_MY16_Gas_Tx" SG_ 560 TrnSrvcRqd_B_Rq 1;
BA_ "U_CD4_MY14_Gas_Tx" SG_ 560 TrnSrvcRqd_B_Rq 1;
BA_ "CrossOver_InfoCAN" SG_ 560 GearPos_D_Trg 1;
BA_ "ContentDependant" SG_ 560 GearPos_D_Trg 1;
BA_ "U_CD4_MY13_Gas_Tx" SG_ 560 GearPos_D_Trg 1;
BA_ "U_CD42_MY14_Gas_Tx" SG_ 560 GearPos_D_Trg 1;
BA_ "U_P552_MY15_Gas_Tx" SG_ 560 GearPos_D_Trg 1;
BA_ "U_S550_MY15_Gas_Tx" SG_ 560 GearPos_D_Trg 1;
BA_ "U_C489_MY14_Gas_Tx" SG_ 560 GearPos_D_Trg 1;
BA_ "U_U502_MY15_Gas_Tx" SG_ 560 GearPos_D_Trg 1;
BA_ "U_UP375_MY15_Gas_Tx" SG_ 560 GearPos_D_Trg 1;
BA_ "U_CD43_MY16_Gas_Tx" SG_ 560 GearPos_D_Trg 1;
BA_ "U_CD4_MY14_Gas_Tx" SG_ 560 GearPos_D_Trg 1;
BA_ "GenSigStartValue" SG_ 560 GearPos_D_Trg 15;
BA_ "ContentDependant" SG_ 560 TrnShifActv_B_Actl 1;
BA_ "U_CD4_MY13_Gas_Tx" SG_ 560 TrnShifActv_B_Actl 1;
BA_ "U_CD42_MY14_Gas_Tx" SG_ 560 TrnShifActv_B_Actl 1;
BA_ "U_P552_MY15_Gas_Tx" SG_ 560 TrnShifActv_B_Actl 1;
BA_ "U_S550_MY15_Gas_Tx" SG_ 560 TrnShifActv_B_Actl 1;
BA_ "U_C489_MY14_Gas_Tx" SG_ 560 TrnShifActv_B_Actl 1;
BA_ "U_U502_MY15_Gas_Tx" SG_ 560 TrnShifActv_B_Actl 1;
BA_ "U_UP375_MY15_Gas_Tx" SG_ 560 TrnShifActv_B_Actl 1;
BA_ "U_CD43_MY16_Gas_Tx" SG_ 560 TrnShifActv_B_Actl 1;
BA_ "U_CD4_MY14_Gas_Tx" SG_ 560 TrnShifActv_B_Actl 1;
BA_ "CrossOver_InfoCAN" SG_ 560 GearLvrPos_D_Actl 1;
BA_ "CrossOver_LIN" SG_ 560 GearLvrPos_D_Actl 1;
BA_ "U_CD4_MY13_Diesel_Rx" SG_ 560 GearLvrPos_D_Actl 1;
BA_ "U_CD4_MY13_Gas_Rx" SG_ 560 GearLvrPos_D_Actl 1;
BA_ "U_CD4_MY13_Hev_Rx" SG_ 560 GearLvrPos_D_Actl 1;
BA_ "U_CD4_MY13_Phev_Rx" SG_ 560 GearLvrPos_D_Actl 1;
BA_ "U_CD42_MY14_Diesel_Rx" SG_ 560 GearLvrPos_D_Actl 1;
BA_ "U_CD42_MY14_Gas_Rx" SG_ 560 GearLvrPos_D_Actl 1;
BA_ "U_P552_MY15_Gas_Rx" SG_ 560 GearLvrPos_D_Actl 1;
BA_ "U_S550_MY15_Gas_Rx" SG_ 560 GearLvrPos_D_Actl 1;
BA_ "U_C489_MY14_Gas_Rx" SG_ 560 GearLvrPos_D_Actl 1;
BA_ "U_U502_MY15_Gas_Rx" SG_ 560 GearLvrPos_D_Actl 1;
BA_ "U_UP375_MY15_Gas_Rx" SG_ 560 GearLvrPos_D_Actl 1;
BA_ "U_UP375_MY15_Diesel_Rx" SG_ 560 GearLvrPos_D_Actl 1;
BA_ "U_CD43_MY16_Gas_Rx" SG_ 560 GearLvrPos_D_Actl 1;
BA_ "U_CD4_MY14_Diesel_Rx" SG_ 560 GearLvrPos_D_Actl 1;
BA_ "U_CD4_MY14_Gas_Rx" SG_ 560 GearLvrPos_D_Actl 1;
BA_ "U_CD4_MY14_Hev_Rx" SG_ 560 GearLvrPos_D_Actl 1;
BA_ "U_CD4_MY14_Phev_Rx" SG_ 560 GearLvrPos_D_Actl 1;
BA_ "U_CD4_MY13_Gas_Tx" SG_ 560 GearLvrPos_D_Actl 1;
BA_ "U_CD42_MY14_Gas_Tx" SG_ 560 GearLvrPos_D_Actl 1;
BA_ "U_P552_MY15_Gas_Tx" SG_ 560 GearLvrPos_D_Actl 1;
BA_ "U_S550_MY15_Gas_Tx" SG_ 560 GearLvrPos_D_Actl 1;
BA_ "U_C489_MY14_Gas_Tx" SG_ 560 GearLvrPos_D_Actl 1;
BA_ "U_U502_MY15_Gas_Tx" SG_ 560 GearLvrPos_D_Actl 1;
BA_ "U_UP375_MY15_Gas_Tx" SG_ 560 GearLvrPos_D_Actl 1;
BA_ "U_CD43_MY16_Gas_Tx" SG_ 560 GearLvrPos_D_Actl 1;
BA_ "U_CD4_MY14_Gas_Tx" SG_ 560 GearLvrPos_D_Actl 1;
BA_ "ContentDependant" SG_ 560 GboxOil_Te_Actl 1;
BA_ "U_CD4_MY13_Gas_Tx" SG_ 560 GboxOil_Te_Actl 1;
BA_ "U_CD42_MY14_Gas_Tx" SG_ 560 GboxOil_Te_Actl 1;
BA_ "U_P552_MY15_Gas_Tx" SG_ 560 GboxOil_Te_Actl 1;
BA_ "U_S550_MY15_Gas_Tx" SG_ 560 GboxOil_Te_Actl 1;
BA_ "U_C489_MY14_Gas_Tx" SG_ 560 GboxOil_Te_Actl 1;
BA_ "U_U502_MY15_Gas_Tx" SG_ 560 GboxOil_Te_Actl 1;
BA_ "U_CD43_MY16_Gas_Tx" SG_ 560 GboxOil_Te_Actl 1;
BA_ "U_CD4_MY14_Gas_Tx" SG_ 560 GboxOil_Te_Actl 1;
BA_ "GenSigStartValue" SG_ 560 GboxOil_Te_Actl 254;
BA_ "ContentDependant" SG_ 357 EngAout_N_MnAllw 1;
BA_ "U_V36X_MY16_5_Diesel_Tx" SG_ 357 EngAout_N_MnAllw 1;
BA_ "U_P558_MY17_Diesel_Tx" SG_ 357 EngAout_N_MnAllw 1;
BA_ "U_CD4_MY17_Phev_Tx" SG_ 357 EngAout_N_MnAllw 1;
BA_ "U_CD4_MY17_Hev_Tx" SG_ 357 EngAout_N_MnAllw 1;
BA_ "U_CD4_MY14_Phev_Tx" SG_ 357 EngAout_N_MnAllw 1;
BA_ "U_CD4_MY14_Hev_Tx" SG_ 357 EngAout_N_MnAllw 1;
BA_ "U_UP375_MY15_Diesel_Tx" SG_ 357 EngAout_N_MnAllw 1;
BA_ "U_V36X_MY16_5_Diesel_Rx" SG_ 357 EngAout_N_MnAllw 1;
BA_ "U_P558_MY17_Diesel_Rx" SG_ 357 EngAout_N_MnAllw 1;
BA_ "U_CD4_MY17_Phev_Rx" SG_ 357 EngAout_N_MnAllw 1;
BA_ "U_CD4_MY17_Hev_Rx" SG_ 357 EngAout_N_MnAllw 1;
BA_ "U_CD4_MY14_Phev_Rx" SG_ 357 EngAout_N_MnAllw 1;
BA_ "U_CD4_MY14_Hev_Rx" SG_ 357 EngAout_N_MnAllw 1;
BA_ "U_UP375_MY15_Diesel_Rx" SG_ 357 EngAout_N_MnAllw 1;
BA_ "ContentDependant" SG_ 357 CmbbEngTqMn_B_Actl 1;
BA_ "U_CD43_MY16_Gas_Tx" SG_ 357 CmbbEngTqMn_B_Actl 1;
BA_ "U_CD4_MY14_Diesel_Tx" SG_ 357 CmbbEngTqMn_B_Actl 1;
BA_ "U_CD4_MY17_Diesel_Tx" SG_ 357 CmbbEngTqMn_B_Actl 1;
BA_ "U_CD4_MY17_Gas_Tx" SG_ 357 CmbbEngTqMn_B_Actl 1;
BA_ "U_V36X_MY16_5_Diesel_Tx" SG_ 357 CmbbEngTqMn_B_Actl 1;
BA_ "U_CD42_MY16_Diesel_Tx" SG_ 357 CmbbEngTqMn_B_Actl 1;
BA_ "U_CD43_MY17_Gas_Tx" SG_ 357 CmbbEngTqMn_B_Actl 1;
BA_ "U_U55x_MY18_Gas_Tx" SG_ 357 CmbbEngTqMn_B_Actl 1;
BA_ "ContentDependant" SG_ 357 CmbbDeny_B_ActlPrpl 1;
BA_ "U_CD43_MY16_Gas_Tx" SG_ 357 CmbbDeny_B_ActlPrpl 1;
BA_ "U_CD4_MY14_Diesel_Tx" SG_ 357 CmbbDeny_B_ActlPrpl 1;
BA_ "U_CD4_MY17_Diesel_Tx" SG_ 357 CmbbDeny_B_ActlPrpl 1;
BA_ "U_CD4_MY17_Gas_Tx" SG_ 357 CmbbDeny_B_ActlPrpl 1;
BA_ "U_V36X_MY16_5_Diesel_Tx" SG_ 357 CmbbDeny_B_ActlPrpl 1;
BA_ "U_CD42_MY16_Diesel_Tx" SG_ 357 CmbbDeny_B_ActlPrpl 1;
BA_ "U_CD43_MY17_Gas_Tx" SG_ 357 CmbbDeny_B_ActlPrpl 1;
BA_ "U_U55x_MY18_Gas_Tx" SG_ 357 CmbbDeny_B_ActlPrpl 1;
BA_ "ContentDependant" SG_ 357 AccStopMde_D_Rq 1;
BA_ "U_CD4_MY13_Hev_Tx" SG_ 357 AccStopMde_D_Rq 1;
BA_ "U_CD4_MY13_Phev_Tx" SG_ 357 AccStopMde_D_Rq 1;
BA_ "U_CD43_MY16_Gas_Tx" SG_ 357 AccStopMde_D_Rq 1;
BA_ "U_CD4_MY14_Diesel_Tx" SG_ 357 AccStopMde_D_Rq 1;
BA_ "U_CD4_MY14_Gas_Tx" SG_ 357 AccStopMde_D_Rq 1;
BA_ "U_CD4_MY14_Hev_Tx" SG_ 357 AccStopMde_D_Rq 1;
BA_ "U_CD4_MY14_Phev_Tx" SG_ 357 AccStopMde_D_Rq 1;
BA_ "U_CD4_MY17_Diesel_Tx" SG_ 357 AccStopMde_D_Rq 1;
BA_ "U_CD4_MY17_Gas_Tx" SG_ 357 AccStopMde_D_Rq 1;
BA_ "U_CD4_MY17_Hev_Tx" SG_ 357 AccStopMde_D_Rq 1;
BA_ "U_CD4_MY17_Phev_Tx" SG_ 357 AccStopMde_D_Rq 1;
BA_ "U_CD42_MY16_Diesel_Tx" SG_ 357 AccStopMde_D_Rq 1;
BA_ "U_CD42_MY16_Gas_Tx" SG_ 357 AccStopMde_D_Rq 1;
BA_ "U_CD43_MY17_Gas_Tx" SG_ 357 AccStopMde_D_Rq 1;
BA_ "U_U55x_MY18_Gas_Tx" SG_ 357 AccStopMde_D_Rq 1;
BA_ "U_CD4_MY13_Gas_Tx" SG_ 357 BPedDrvAppl_D_QF 1;
BA_ "U_CD42_MY14_Gas_Tx" SG_ 357 BPedDrvAppl_D_QF 1;
BA_ "U_P552_MY15_Gas_Tx" SG_ 357 BPedDrvAppl_D_QF 1;
BA_ "U_S550_MY15_Gas_Tx" SG_ 357 BPedDrvAppl_D_QF 1;
BA_ "U_C489_MY14_Gas_Tx" SG_ 357 BPedDrvAppl_D_QF 1;
BA_ "U_U502_MY15_Gas_Tx" SG_ 357 BPedDrvAppl_D_QF 1;
BA_ "U_UP375_MY15_Gas_Tx" SG_ 357 BPedDrvAppl_D_QF 1;
BA_ "U_CD43_MY16_Gas_Tx" SG_ 357 BPedDrvAppl_D_QF 1;
BA_ "U_CD4_MY14_Gas_Tx" SG_ 357 BPedDrvAppl_D_QF 1;
BA_ "GenSigTimeoutTime_TCM" SG_ 357 BPedDrvAppl_D_QF 60;
BA_ "U_CD4_MY13_Gas_Tx" SG_ 357 PrplTqMnSat_B_Actl 1;
BA_ "U_CD42_MY14_Gas_Tx" SG_ 357 PrplTqMnSat_B_Actl 1;
BA_ "U_P552_MY15_Gas_Tx" SG_ 357 PrplTqMnSat_B_Actl 1;
BA_ "U_S550_MY15_Gas_Tx" SG_ 357 PrplTqMnSat_B_Actl 1;
BA_ "U_C489_MY14_Gas_Tx" SG_ 357 PrplTqMnSat_B_Actl 1;
BA_ "U_U502_MY15_Gas_Tx" SG_ 357 PrplTqMnSat_B_Actl 1;
BA_ "U_UP375_MY15_Gas_Tx" SG_ 357 PrplTqMnSat_B_Actl 1;
BA_ "U_CD43_MY16_Gas_Tx" SG_ 357 PrplTqMnSat_B_Actl 1;
BA_ "U_CD4_MY14_Gas_Tx" SG_ 357 PrplTqMnSat_B_Actl 1;
BA_ "CrossOver_InfoCAN" SG_ 357 BpedDrvAppl_D_Actl 1;
BA_ "U_CD4_MY13_Gas_Tx" SG_ 357 BpedDrvAppl_D_Actl 1;
BA_ "U_CD42_MY14_Gas_Tx" SG_ 357 BpedDrvAppl_D_Actl 1;
BA_ "U_P552_MY15_Gas_Tx" SG_ 357 BpedDrvAppl_D_Actl 1;
BA_ "U_S550_MY15_Gas_Tx" SG_ 357 BpedDrvAppl_D_Actl 1;
BA_ "U_C489_MY14_Gas_Tx" SG_ 357 BpedDrvAppl_D_Actl 1;
BA_ "U_U502_MY15_Gas_Tx" SG_ 357 BpedDrvAppl_D_Actl 1;
BA_ "U_UP375_MY15_Gas_Tx" SG_ 357 BpedDrvAppl_D_Actl 1;
BA_ "U_CD43_MY16_Gas_Tx" SG_ 357 BpedDrvAppl_D_Actl 1;
BA_ "U_CD4_MY14_Gas_Tx" SG_ 357 BpedDrvAppl_D_Actl 1;
BA_ "GenSigTimeoutTime_TCM" SG_ 357 BpedDrvAppl_D_Actl 60;
BA_ "CrossOver_InfoCAN" SG_ 357 Veh_V_DsplyCcSet 1;
BA_ "U_CD4_MY13_Gas_Tx" SG_ 357 Veh_V_DsplyCcSet 1;
BA_ "U_CD42_MY14_Gas_Tx" SG_ 357 Veh_V_DsplyCcSet 1;
BA_ "U_P552_MY15_Gas_Tx" SG_ 357 Veh_V_DsplyCcSet 1;
BA_ "U_S550_MY15_Gas_Tx" SG_ 357 Veh_V_DsplyCcSet 1;
BA_ "U_C489_MY14_Gas_Tx" SG_ 357 Veh_V_DsplyCcSet 1;
BA_ "U_U502_MY15_Gas_Tx" SG_ 357 Veh_V_DsplyCcSet 1;
BA_ "U_UP375_MY15_Gas_Tx" SG_ 357 Veh_V_DsplyCcSet 1;
BA_ "U_CD43_MY16_Gas_Tx" SG_ 357 Veh_V_DsplyCcSet 1;
BA_ "U_CD4_MY14_Gas_Tx" SG_ 357 Veh_V_DsplyCcSet 1;
BA_ "U_CD4_MY13_Gas_Tx" SG_ 357 AccEngStat_D_Actl 1;
BA_ "U_CD42_MY14_Gas_Tx" SG_ 357 AccEngStat_D_Actl 1;
BA_ "U_P552_MY15_Gas_Tx" SG_ 357 AccEngStat_D_Actl 1;
BA_ "U_S550_MY15_Gas_Tx" SG_ 357 AccEngStat_D_Actl 1;
BA_ "U_C489_MY14_Gas_Tx" SG_ 357 AccEngStat_D_Actl 1;
BA_ "U_U502_MY15_Gas_Tx" SG_ 357 AccEngStat_D_Actl 1;
BA_ "U_UP375_MY15_Gas_Tx" SG_ 357 AccEngStat_D_Actl 1;
BA_ "U_CD43_MY16_Gas_Tx" SG_ 357 AccEngStat_D_Actl 1;
BA_ "U_CD4_MY14_Gas_Tx" SG_ 357 AccEngStat_D_Actl 1;
BA_ "U_CD4_MY13_Gas_Tx" SG_ 357 CcMde_D_Actl 1;
BA_ "U_CD42_MY14_Gas_Tx" SG_ 357 CcMde_D_Actl 1;
BA_ "U_P552_MY15_Gas_Tx" SG_ 357 CcMde_D_Actl 1;
BA_ "U_S550_MY15_Gas_Tx" SG_ 357 CcMde_D_Actl 1;
BA_ "U_C489_MY14_Gas_Tx" SG_ 357 CcMde_D_Actl 1;
BA_ "U_U502_MY15_Gas_Tx" SG_ 357 CcMde_D_Actl 1;
BA_ "U_UP375_MY15_Gas_Tx" SG_ 357 CcMde_D_Actl 1;
BA_ "U_CD43_MY16_Gas_Tx" SG_ 357 CcMde_D_Actl 1;
BA_ "U_CD4_MY14_Gas_Tx" SG_ 357 CcMde_D_Actl 1;
BA_ "GenSigTimeoutTime_TCM" SG_ 357 CcMde_D_Actl 60;
BA_ "CrossOver_InfoCAN" SG_ 357 CcStat_D_Actl 1;
BA_ "U_CD4_MY13_Gas_Tx" SG_ 357 CcStat_D_Actl 1;
BA_ "U_CD42_MY14_Gas_Tx" SG_ 357 CcStat_D_Actl 1;
BA_ "U_P552_MY15_Gas_Tx" SG_ 357 CcStat_D_Actl 1;
BA_ "U_S550_MY15_Gas_Tx" SG_ 357 CcStat_D_Actl 1;
BA_ "U_C489_MY14_Gas_Tx" SG_ 357 CcStat_D_Actl 1;
BA_ "U_U502_MY15_Gas_Tx" SG_ 357 CcStat_D_Actl 1;
BA_ "U_UP375_MY15_Gas_Tx" SG_ 357 CcStat_D_Actl 1;
BA_ "U_CD43_MY16_Gas_Tx" SG_ 357 CcStat_D_Actl 1;
BA_ "U_CD4_MY14_Gas_Tx" SG_ 357 CcStat_D_Actl 1;
BA_ "GenSigTimeoutTime_TCM" SG_ 357 CcStat_D_Actl 60;
BA_ "CrossOver_InfoCAN" SG_ 357 CcOvrrdActv_B_Actl 1;
BA_ "U_CD4_MY13_Gas_Tx" SG_ 357 CcOvrrdActv_B_Actl 1;
BA_ "U_CD42_MY14_Gas_Tx" SG_ 357 CcOvrrdActv_B_Actl 1;
BA_ "U_P552_MY15_Gas_Tx" SG_ 357 CcOvrrdActv_B_Actl 1;
BA_ "U_S550_MY15_Gas_Tx" SG_ 357 CcOvrrdActv_B_Actl 1;
BA_ "U_C489_MY14_Gas_Tx" SG_ 357 CcOvrrdActv_B_Actl 1;
BA_ "U_U502_MY15_Gas_Tx" SG_ 357 CcOvrrdActv_B_Actl 1;
BA_ "U_UP375_MY15_Gas_Tx" SG_ 357 CcOvrrdActv_B_Actl 1;
BA_ "U_CD43_MY16_Gas_Tx" SG_ 357 CcOvrrdActv_B_Actl 1;
BA_ "U_CD4_MY14_Gas_Tx" SG_ 357 CcOvrrdActv_B_Actl 1;
BA_ "GenSigTimeoutTime_TCM" SG_ 357 CcOvrrdActv_B_Actl 60;
BA_ "GenSigSendType" SG_ 1003 PersRecallSrc_D_Actl 3;
BA_ "U_U55x_MY18_Gas_Tx" SG_ 1003 PersRecallSrc_D_Actl 1;
BA_ "U_V36X_MY18_5_Hev_Tx" SG_ 1003 Pers4Key_D_Stat 1;
BA_ "U_V36X_MY18_5_Gas_Tx" SG_ 1003 Pers4Key_D_Stat 1;
BA_ "U_V363E_N_MY19_5_20_Diesel_Tx" SG_ 1003 Pers4Key_D_Stat 1;
BA_ "U_V363E_N_MY19_5_20_Gas_Tx" SG_ 1003 Pers4Key_D_Stat 1;
BA_ "U_V36X_MY19_5_Diesel_Tx" SG_ 1003 Pers4Key_D_Stat 1;
BA_ "U_P552_MY18_5_Diesel_Tx" SG_ 1003 Pers4Key_D_Stat 1;
BA_ "U_P552_MY18_5_Gas_Tx" SG_ 1003 Pers4Key_D_Stat 1;
BA_ "U_V36X_MY18_5_Diesel_Tx" SG_ 1003 Pers4Key_D_Stat 1;
BA_ "U_V408_MY18_Diesel_Tx" SG_ 1003 Pers4Key_D_Stat 1;
BA_ "U_V408_MY18_Gas_Tx" SG_ 1003 Pers4Key_D_Stat 1;
BA_ "U_U55x_MY18_Gas_Tx" SG_ 1003 Pers4Key_D_Stat 1;
BA_ "GenSigSendType" SG_ 1003 Pers4Key_D_Stat 3;
BA_ "U_V36X_MY18_5_Hev_Tx" SG_ 1003 Pers3Key_D_Stat 1;
BA_ "U_V36X_MY18_5_Gas_Tx" SG_ 1003 Pers3Key_D_Stat 1;
BA_ "U_V363E_N_MY19_5_20_Diesel_Tx" SG_ 1003 Pers3Key_D_Stat 1;
BA_ "U_V363E_N_MY19_5_20_Gas_Tx" SG_ 1003 Pers3Key_D_Stat 1;
BA_ "U_V36X_MY19_5_Diesel_Tx" SG_ 1003 Pers3Key_D_Stat 1;
BA_ "U_P552_MY18_5_Diesel_Tx" SG_ 1003 Pers3Key_D_Stat 1;
BA_ "U_P552_MY18_5_Gas_Tx" SG_ 1003 Pers3Key_D_Stat 1;
BA_ "U_V36X_MY18_5_Diesel_Tx" SG_ 1003 Pers3Key_D_Stat 1;
BA_ "U_V408_MY18_Diesel_Tx" SG_ 1003 Pers3Key_D_Stat 1;
BA_ "U_V408_MY18_Gas_Tx" SG_ 1003 Pers3Key_D_Stat 1;
BA_ "U_U55x_MY18_Gas_Tx" SG_ 1003 Pers3Key_D_Stat 1;
BA_ "GenSigSendType" SG_ 1003 Pers3Key_D_Stat 3;
BA_ "U_V36X_MY18_5_Hev_Tx" SG_ 1003 Pers2Key_D_Stat 1;
BA_ "U_V36X_MY18_5_Gas_Tx" SG_ 1003 Pers2Key_D_Stat 1;
BA_ "U_V363E_N_MY19_5_20_Diesel_Tx" SG_ 1003 Pers2Key_D_Stat 1;
BA_ "U_V363E_N_MY19_5_20_Gas_Tx" SG_ 1003 Pers2Key_D_Stat 1;
BA_ "U_V36X_MY19_5_Diesel_Tx" SG_ 1003 Pers2Key_D_Stat 1;
BA_ "U_P552_MY18_5_Diesel_Tx" SG_ 1003 Pers2Key_D_Stat 1;
BA_ "U_P552_MY18_5_Gas_Tx" SG_ 1003 Pers2Key_D_Stat 1;
BA_ "U_V36X_MY18_5_Diesel_Tx" SG_ 1003 Pers2Key_D_Stat 1;
BA_ "U_V408_MY18_Diesel_Tx" SG_ 1003 Pers2Key_D_Stat 1;
BA_ "U_V408_MY18_Gas_Tx" SG_ 1003 Pers2Key_D_Stat 1;
BA_ "U_U55x_MY18_Gas_Tx" SG_ 1003 Pers2Key_D_Stat 1;
BA_ "GenSigSendType" SG_ 1003 Pers2Key_D_Stat 3;
BA_ "U_V36X_MY18_5_Hev_Tx" SG_ 1003 Pers1Key_D_Stat 1;
BA_ "U_V36X_MY18_5_Gas_Tx" SG_ 1003 Pers1Key_D_Stat 1;
BA_ "U_V363E_N_MY19_5_20_Diesel_Tx" SG_ 1003 Pers1Key_D_Stat 1;
BA_ "U_V363E_N_MY19_5_20_Gas_Tx" SG_ 1003 Pers1Key_D_Stat 1;
BA_ "U_V36X_MY19_5_Diesel_Tx" SG_ 1003 Pers1Key_D_Stat 1;
BA_ "U_P552_MY18_5_Diesel_Tx" SG_ 1003 Pers1Key_D_Stat 1;
BA_ "U_P552_MY18_5_Gas_Tx" SG_ 1003 Pers1Key_D_Stat 1;
BA_ "U_V36X_MY18_5_Diesel_Tx" SG_ 1003 Pers1Key_D_Stat 1;
BA_ "U_V408_MY18_Diesel_Tx" SG_ 1003 Pers1Key_D_Stat 1;
BA_ "U_V408_MY18_Gas_Tx" SG_ 1003 Pers1Key_D_Stat 1;
BA_ "U_U55x_MY18_Gas_Tx" SG_ 1003 Pers1Key_D_Stat 1;
BA_ "GenSigSendType" SG_ 1003 Pers1Key_D_Stat 3;
BA_ "U_V36X_MY18_5_Hev_Tx" SG_ 1003 EmPrflNo_D_Stat 1;
BA_ "U_V36X_MY18_5_Gas_Tx" SG_ 1003 EmPrflNo_D_Stat 1;
BA_ "U_V363E_N_MY19_5_20_Diesel_Tx" SG_ 1003 EmPrflNo_D_Stat 1;
BA_ "U_V363E_N_MY19_5_20_Gas_Tx" SG_ 1003 EmPrflNo_D_Stat 1;
BA_ "U_V36X_MY19_5_Diesel_Tx" SG_ 1003 EmPrflNo_D_Stat 1;
BA_ "U_P552_MY18_5_Diesel_Tx" SG_ 1003 EmPrflNo_D_Stat 1;
BA_ "U_P552_MY18_5_Gas_Tx" SG_ 1003 EmPrflNo_D_Stat 1;
BA_ "U_V36X_MY18_5_Diesel_Tx" SG_ 1003 EmPrflNo_D_Stat 1;
BA_ "U_V408_MY18_Diesel_Tx" SG_ 1003 EmPrflNo_D_Stat 1;
BA_ "U_V408_MY18_Gas_Tx" SG_ 1003 EmPrflNo_D_Stat 1;
BA_ "U_U55x_MY18_Gas_Tx" SG_ 1003 EmPrflNo_D_Stat 1;
BA_ "GenSigSendType" SG_ 1003 EmPrflNo_D_Stat 3;
BA_ "U_V36X_MY18_5_Hev_Tx" SG_ 1003 EmPrflKeyAssoc_D_Stat 1;
BA_ "U_V36X_MY18_5_Gas_Tx" SG_ 1003 EmPrflKeyAssoc_D_Stat 1;
BA_ "U_V363E_N_MY19_5_20_Diesel_Tx" SG_ 1003 EmPrflKeyAssoc_D_Stat 1;
BA_ "U_V363E_N_MY19_5_20_Gas_Tx" SG_ 1003 EmPrflKeyAssoc_D_Stat 1;
BA_ "U_V36X_MY19_5_Diesel_Tx" SG_ 1003 EmPrflKeyAssoc_D_Stat 1;
BA_ "U_P552_MY18_5_Diesel_Tx" SG_ 1003 EmPrflKeyAssoc_D_Stat 1;
BA_ "U_P552_MY18_5_Gas_Tx" SG_ 1003 EmPrflKeyAssoc_D_Stat 1;
BA_ "U_V36X_MY18_5_Diesel_Tx" SG_ 1003 EmPrflKeyAssoc_D_Stat 1;
BA_ "U_V408_MY18_Diesel_Tx" SG_ 1003 EmPrflKeyAssoc_D_Stat 1;
BA_ "U_V408_MY18_Gas_Tx" SG_ 1003 EmPrflKeyAssoc_D_Stat 1;
BA_ "U_U55x_MY18_Gas_Tx" SG_ 1003 EmPrflKeyAssoc_D_Stat 1;
BA_ "GenSigSendType" SG_ 1003 EmPrflKeyAssoc_D_Stat 3;
BA_ "GenSigSendType" SG_ 1003 VehKeyActv_D_Stat 3;
BA_ "U_P552_MY15_Gas_Tx" SG_ 1003 VehKeyActv_D_Stat 1;
BA_ "U_S550_MY15_Gas_Tx" SG_ 1003 VehKeyActv_D_Stat 1;
BA_ "U_C489_MY14_Gas_Tx" SG_ 1003 VehKeyActv_D_Stat 1;
BA_ "U_CD43_MY16_Gas_Tx" SG_ 1003 VehKeyActv_D_Stat 1;
BA_ "U_CD4_MY14_Diesel_Tx" SG_ 1003 VehKeyActv_D_Stat 1;
BA_ "U_CD4_MY14_Gas_Tx" SG_ 1003 VehKeyActv_D_Stat 1;
BA_ "U_CD4_MY14_Hev_Tx" SG_ 1003 VehKeyActv_D_Stat 1;
BA_ "U_CD4_MY14_Phev_Tx" SG_ 1003 VehKeyActv_D_Stat 1;
BA_ "CrossOver_InfoCAN" SG_ 1003 PersNoPos_D_Actl 1;
BA_ "GenSigStartValue" SG_ 1003 PersNoPos_D_Actl 4;
BA_ "GenSigSendType" SG_ 1003 PersNoPos_D_Actl 3;
BA_ "U_CD4_MY13_Diesel_Rx" SG_ 1003 PersNoPos_D_Actl 1;
BA_ "U_CD4_MY13_Gas_Rx" SG_ 1003 PersNoPos_D_Actl 1;
BA_ "U_CD4_MY13_Hev_Rx" SG_ 1003 PersNoPos_D_Actl 1;
BA_ "U_CD4_MY13_Phev_Rx" SG_ 1003 PersNoPos_D_Actl 1;
BA_ "U_CD42_MY14_Diesel_Rx" SG_ 1003 PersNoPos_D_Actl 1;
BA_ "U_CD42_MY14_Gas_Rx" SG_ 1003 PersNoPos_D_Actl 1;
BA_ "U_P552_MY15_Gas_Rx" SG_ 1003 PersNoPos_D_Actl 1;
BA_ "U_S550_MY15_Gas_Rx" SG_ 1003 PersNoPos_D_Actl 1;
BA_ "U_C489_MY14_Gas_Rx" SG_ 1003 PersNoPos_D_Actl 1;
BA_ "U_U502_MY15_Gas_Rx" SG_ 1003 PersNoPos_D_Actl 1;
BA_ "U_CD43_MY16_Gas_Rx" SG_ 1003 PersNoPos_D_Actl 1;
BA_ "U_CD4_MY14_Diesel_Rx" SG_ 1003 PersNoPos_D_Actl 1;
BA_ "U_CD4_MY14_Gas_Rx" SG_ 1003 PersNoPos_D_Actl 1;
BA_ "U_CD4_MY14_Hev_Rx" SG_ 1003 PersNoPos_D_Actl 1;
BA_ "U_CD4_MY14_Phev_Rx" SG_ 1003 PersNoPos_D_Actl 1;
BA_ "U_CD4_MY13_Diesel_Tx" SG_ 1003 PersNoPos_D_Actl 1;
BA_ "U_CD4_MY13_Gas_Tx" SG_ 1003 PersNoPos_D_Actl 1;
BA_ "U_CD4_MY13_Hev_Tx" SG_ 1003 PersNoPos_D_Actl 1;
BA_ "U_CD4_MY13_Phev_Tx" SG_ 1003 PersNoPos_D_Actl 1;
BA_ "U_CD42_MY14_Diesel_Tx" SG_ 1003 PersNoPos_D_Actl 1;
BA_ "U_CD42_MY14_Gas_Tx" SG_ 1003 PersNoPos_D_Actl 1;
BA_ "U_P552_MY15_Gas_Tx" SG_ 1003 PersNoPos_D_Actl 1;
BA_ "U_S550_MY15_Gas_Tx" SG_ 1003 PersNoPos_D_Actl 1;
BA_ "U_C489_MY14_Gas_Tx" SG_ 1003 PersNoPos_D_Actl 1;
BA_ "U_U502_MY15_Gas_Tx" SG_ 1003 PersNoPos_D_Actl 1;
BA_ "U_UP375_MY15_Gas_Tx" SG_ 1003 PersNoPos_D_Actl 1;
BA_ "U_UP375_MY15_Diesel_Tx" SG_ 1003 PersNoPos_D_Actl 1;
BA_ "U_CD43_MY16_Gas_Tx" SG_ 1003 PersNoPos_D_Actl 1;
BA_ "U_CD4_MY14_Diesel_Tx" SG_ 1003 PersNoPos_D_Actl 1;
BA_ "U_CD4_MY14_Gas_Tx" SG_ 1003 PersNoPos_D_Actl 1;
BA_ "U_CD4_MY14_Hev_Tx" SG_ 1003 PersNoPos_D_Actl 1;
BA_ "U_CD4_MY14_Phev_Tx" SG_ 1003 PersNoPos_D_Actl 1;
BA_ "CrossOver_InfoCAN" SG_ 1003 PersSetupRestr_D_Actl 1;
BA_ "GenSigSendType" SG_ 1003 PersSetupRestr_D_Actl 3;
BA_ "U_CD4_MY13_Diesel_Rx" SG_ 1003 PersSetupRestr_D_Actl 1;
BA_ "U_CD4_MY13_Gas_Rx" SG_ 1003 PersSetupRestr_D_Actl 1;
BA_ "U_CD4_MY13_Hev_Rx" SG_ 1003 PersSetupRestr_D_Actl 1;
BA_ "U_CD4_MY13_Phev_Rx" SG_ 1003 PersSetupRestr_D_Actl 1;
BA_ "U_CD42_MY14_Diesel_Rx" SG_ 1003 PersSetupRestr_D_Actl 1;
BA_ "U_CD42_MY14_Gas_Rx" SG_ 1003 PersSetupRestr_D_Actl 1;
BA_ "U_P552_MY15_Gas_Rx" SG_ 1003 PersSetupRestr_D_Actl 1;
BA_ "U_S550_MY15_Gas_Rx" SG_ 1003 PersSetupRestr_D_Actl 1;
BA_ "U_C489_MY14_Gas_Rx" SG_ 1003 PersSetupRestr_D_Actl 1;
BA_ "U_U502_MY15_Gas_Rx" SG_ 1003 PersSetupRestr_D_Actl 1;
BA_ "U_CD43_MY16_Gas_Rx" SG_ 1003 PersSetupRestr_D_Actl 1;
BA_ "U_CD4_MY14_Diesel_Rx" SG_ 1003 PersSetupRestr_D_Actl 1;
BA_ "U_CD4_MY14_Gas_Rx" SG_ 1003 PersSetupRestr_D_Actl 1;
BA_ "U_CD4_MY14_Hev_Rx" SG_ 1003 PersSetupRestr_D_Actl 1;
BA_ "U_CD4_MY14_Phev_Rx" SG_ 1003 PersSetupRestr_D_Actl 1;
BA_ "U_CD4_MY13_Diesel_Tx" SG_ 1003 PersSetupRestr_D_Actl 1;
BA_ "U_CD4_MY13_Gas_Tx" SG_ 1003 PersSetupRestr_D_Actl 1;
BA_ "U_CD4_MY13_Hev_Tx" SG_ 1003 PersSetupRestr_D_Actl 1;
BA_ "U_CD4_MY13_Phev_Tx" SG_ 1003 PersSetupRestr_D_Actl 1;
BA_ "U_CD42_MY14_Diesel_Tx" SG_ 1003 PersSetupRestr_D_Actl 1;
BA_ "U_CD42_MY14_Gas_Tx" SG_ 1003 PersSetupRestr_D_Actl 1;
BA_ "U_P552_MY15_Gas_Tx" SG_ 1003 PersSetupRestr_D_Actl 1;
BA_ "U_S550_MY15_Gas_Tx" SG_ 1003 PersSetupRestr_D_Actl 1;
BA_ "U_C489_MY14_Gas_Tx" SG_ 1003 PersSetupRestr_D_Actl 1;
BA_ "U_U502_MY15_Gas_Tx" SG_ 1003 PersSetupRestr_D_Actl 1;
BA_ "U_UP375_MY15_Gas_Tx" SG_ 1003 PersSetupRestr_D_Actl 1;
BA_ "U_UP375_MY15_Diesel_Tx" SG_ 1003 PersSetupRestr_D_Actl 1;
BA_ "U_CD43_MY16_Gas_Tx" SG_ 1003 PersSetupRestr_D_Actl 1;
BA_ "U_CD4_MY14_Diesel_Tx" SG_ 1003 PersSetupRestr_D_Actl 1;
BA_ "U_CD4_MY14_Gas_Tx" SG_ 1003 PersSetupRestr_D_Actl 1;
BA_ "U_CD4_MY14_Hev_Tx" SG_ 1003 PersSetupRestr_D_Actl 1;
BA_ "U_CD4_MY14_Phev_Tx" SG_ 1003 PersSetupRestr_D_Actl 1;
BA_ "CrossOver_InfoCAN" SG_ 1003 PersSetupAccessCtrl 1;
BA_ "GenSigSendType" SG_ 1003 PersSetupAccessCtrl 3;
BA_ "U_CD4_MY13_Diesel_Rx" SG_ 1003 PersSetupAccessCtrl 1;
BA_ "U_CD4_MY13_Gas_Rx" SG_ 1003 PersSetupAccessCtrl 1;
BA_ "U_CD4_MY13_Hev_Rx" SG_ 1003 PersSetupAccessCtrl 1;
BA_ "U_CD4_MY13_Phev_Rx" SG_ 1003 PersSetupAccessCtrl 1;
BA_ "U_CD42_MY14_Diesel_Rx" SG_ 1003 PersSetupAccessCtrl 1;
BA_ "U_CD42_MY14_Gas_Rx" SG_ 1003 PersSetupAccessCtrl 1;
BA_ "U_P552_MY15_Gas_Rx" SG_ 1003 PersSetupAccessCtrl 1;
BA_ "U_S550_MY15_Gas_Rx" SG_ 1003 PersSetupAccessCtrl 1;
BA_ "U_C489_MY14_Gas_Rx" SG_ 1003 PersSetupAccessCtrl 1;
BA_ "U_U502_MY15_Gas_Rx" SG_ 1003 PersSetupAccessCtrl 1;
BA_ "U_CD43_MY16_Gas_Rx" SG_ 1003 PersSetupAccessCtrl 1;
BA_ "U_CD4_MY14_Diesel_Rx" SG_ 1003 PersSetupAccessCtrl 1;
BA_ "U_CD4_MY14_Gas_Rx" SG_ 1003 PersSetupAccessCtrl 1;
BA_ "U_CD4_MY14_Hev_Rx" SG_ 1003 PersSetupAccessCtrl 1;
BA_ "U_CD4_MY14_Phev_Rx" SG_ 1003 PersSetupAccessCtrl 1;
BA_ "U_CD4_MY13_Diesel_Tx" SG_ 1003 PersSetupAccessCtrl 1;
BA_ "U_CD4_MY13_Gas_Tx" SG_ 1003 PersSetupAccessCtrl 1;
BA_ "U_CD4_MY13_Hev_Tx" SG_ 1003 PersSetupAccessCtrl 1;
BA_ "U_CD4_MY13_Phev_Tx" SG_ 1003 PersSetupAccessCtrl 1;
BA_ "U_CD42_MY14_Diesel_Tx" SG_ 1003 PersSetupAccessCtrl 1;
BA_ "U_CD42_MY14_Gas_Tx" SG_ 1003 PersSetupAccessCtrl 1;
BA_ "U_P552_MY15_Gas_Tx" SG_ 1003 PersSetupAccessCtrl 1;
BA_ "U_S550_MY15_Gas_Tx" SG_ 1003 PersSetupAccessCtrl 1;
BA_ "U_C489_MY14_Gas_Tx" SG_ 1003 PersSetupAccessCtrl 1;
BA_ "U_U502_MY15_Gas_Tx" SG_ 1003 PersSetupAccessCtrl 1;
BA_ "U_UP375_MY15_Gas_Tx" SG_ 1003 PersSetupAccessCtrl 1;
BA_ "U_UP375_MY15_Diesel_Tx" SG_ 1003 PersSetupAccessCtrl 1;
BA_ "U_CD43_MY16_Gas_Tx" SG_ 1003 PersSetupAccessCtrl 1;
BA_ "U_CD4_MY14_Diesel_Tx" SG_ 1003 PersSetupAccessCtrl 1;
BA_ "U_CD4_MY14_Gas_Tx" SG_ 1003 PersSetupAccessCtrl 1;
BA_ "U_CD4_MY14_Hev_Tx" SG_ 1003 PersSetupAccessCtrl 1;
BA_ "U_CD4_MY14_Phev_Tx" SG_ 1003 PersSetupAccessCtrl 1;
BA_ "CrossOver_InfoCAN" SG_ 1003 PersSetup_No_Actl 1;
BA_ "GenSigSendType" SG_ 1003 PersSetup_No_Actl 3;
BA_ "U_CD4_MY13_Diesel_Rx" SG_ 1003 PersSetup_No_Actl 1;
BA_ "U_CD4_MY13_Gas_Rx" SG_ 1003 PersSetup_No_Actl 1;
BA_ "U_CD4_MY13_Hev_Rx" SG_ 1003 PersSetup_No_Actl 1;
BA_ "U_CD4_MY13_Phev_Rx" SG_ 1003 PersSetup_No_Actl 1;
BA_ "U_CD42_MY14_Diesel_Rx" SG_ 1003 PersSetup_No_Actl 1;
BA_ "U_CD42_MY14_Gas_Rx" SG_ 1003 PersSetup_No_Actl 1;
BA_ "U_P552_MY15_Gas_Rx" SG_ 1003 PersSetup_No_Actl 1;
BA_ "U_S550_MY15_Gas_Rx" SG_ 1003 PersSetup_No_Actl 1;
BA_ "U_C489_MY14_Gas_Rx" SG_ 1003 PersSetup_No_Actl 1;
BA_ "U_U502_MY15_Gas_Rx" SG_ 1003 PersSetup_No_Actl 1;
BA_ "U_CD43_MY16_Gas_Rx" SG_ 1003 PersSetup_No_Actl 1;
BA_ "U_CD4_MY14_Diesel_Rx" SG_ 1003 PersSetup_No_Actl 1;
BA_ "U_CD4_MY14_Gas_Rx" SG_ 1003 PersSetup_No_Actl 1;
BA_ "U_CD4_MY14_Hev_Rx" SG_ 1003 PersSetup_No_Actl 1;
BA_ "U_CD4_MY14_Phev_Rx" SG_ 1003 PersSetup_No_Actl 1;
BA_ "U_CD4_MY13_Diesel_Tx" SG_ 1003 PersSetup_No_Actl 1;
BA_ "U_CD4_MY13_Gas_Tx" SG_ 1003 PersSetup_No_Actl 1;
BA_ "U_CD4_MY13_Hev_Tx" SG_ 1003 PersSetup_No_Actl 1;
BA_ "U_CD4_MY13_Phev_Tx" SG_ 1003 PersSetup_No_Actl 1;
BA_ "U_CD42_MY14_Diesel_Tx" SG_ 1003 PersSetup_No_Actl 1;
BA_ "U_CD42_MY14_Gas_Tx" SG_ 1003 PersSetup_No_Actl 1;
BA_ "U_P552_MY15_Gas_Tx" SG_ 1003 PersSetup_No_Actl 1;
BA_ "U_S550_MY15_Gas_Tx" SG_ 1003 PersSetup_No_Actl 1;
BA_ "U_C489_MY14_Gas_Tx" SG_ 1003 PersSetup_No_Actl 1;
BA_ "U_U502_MY15_Gas_Tx" SG_ 1003 PersSetup_No_Actl 1;
BA_ "U_UP375_MY15_Gas_Tx" SG_ 1003 PersSetup_No_Actl 1;
BA_ "U_UP375_MY15_Diesel_Tx" SG_ 1003 PersSetup_No_Actl 1;
BA_ "U_CD43_MY16_Gas_Tx" SG_ 1003 PersSetup_No_Actl 1;
BA_ "U_CD4_MY14_Diesel_Tx" SG_ 1003 PersSetup_No_Actl 1;
BA_ "U_CD4_MY14_Gas_Tx" SG_ 1003 PersSetup_No_Actl 1;
BA_ "U_CD4_MY14_Hev_Tx" SG_ 1003 PersSetup_No_Actl 1;
BA_ "U_CD4_MY14_Phev_Tx" SG_ 1003 PersSetup_No_Actl 1;
BA_ "CrossOver_InfoCAN" SG_ 1003 PersConflict_D_Actl 1;
BA_ "GenSigStartValue" SG_ 1003 PersConflict_D_Actl 1;
BA_ "GenSigSendType" SG_ 1003 PersConflict_D_Actl 3;
BA_ "U_CD4_MY13_Diesel_Rx" SG_ 1003 PersConflict_D_Actl 1;
BA_ "U_CD4_MY13_Gas_Rx" SG_ 1003 PersConflict_D_Actl 1;
BA_ "U_CD4_MY13_Hev_Rx" SG_ 1003 PersConflict_D_Actl 1;
BA_ "U_CD4_MY13_Phev_Rx" SG_ 1003 PersConflict_D_Actl 1;
BA_ "U_CD42_MY14_Diesel_Rx" SG_ 1003 PersConflict_D_Actl 1;
BA_ "U_CD42_MY14_Gas_Rx" SG_ 1003 PersConflict_D_Actl 1;
BA_ "U_P552_MY15_Gas_Rx" SG_ 1003 PersConflict_D_Actl 1;
BA_ "U_S550_MY15_Gas_Rx" SG_ 1003 PersConflict_D_Actl 1;
BA_ "U_C489_MY14_Gas_Rx" SG_ 1003 PersConflict_D_Actl 1;
BA_ "U_U502_MY15_Gas_Rx" SG_ 1003 PersConflict_D_Actl 1;
BA_ "U_CD43_MY16_Gas_Rx" SG_ 1003 PersConflict_D_Actl 1;
BA_ "U_CD4_MY14_Diesel_Rx" SG_ 1003 PersConflict_D_Actl 1;
BA_ "U_CD4_MY14_Gas_Rx" SG_ 1003 PersConflict_D_Actl 1;
BA_ "U_CD4_MY14_Hev_Rx" SG_ 1003 PersConflict_D_Actl 1;
BA_ "U_CD4_MY14_Phev_Rx" SG_ 1003 PersConflict_D_Actl 1;
BA_ "U_CD4_MY13_Diesel_Tx" SG_ 1003 PersConflict_D_Actl 1;
BA_ "U_CD4_MY13_Gas_Tx" SG_ 1003 PersConflict_D_Actl 1;
BA_ "U_CD4_MY13_Hev_Tx" SG_ 1003 PersConflict_D_Actl 1;
BA_ "U_CD4_MY13_Phev_Tx" SG_ 1003 PersConflict_D_Actl 1;
BA_ "U_CD42_MY14_Diesel_Tx" SG_ 1003 PersConflict_D_Actl 1;
BA_ "U_CD42_MY14_Gas_Tx" SG_ 1003 PersConflict_D_Actl 1;
BA_ "U_P552_MY15_Gas_Tx" SG_ 1003 PersConflict_D_Actl 1;
BA_ "U_S550_MY15_Gas_Tx" SG_ 1003 PersConflict_D_Actl 1;
BA_ "U_C489_MY14_Gas_Tx" SG_ 1003 PersConflict_D_Actl 1;
BA_ "U_U502_MY15_Gas_Tx" SG_ 1003 PersConflict_D_Actl 1;
BA_ "U_UP375_MY15_Gas_Tx" SG_ 1003 PersConflict_D_Actl 1;
BA_ "U_UP375_MY15_Diesel_Tx" SG_ 1003 PersConflict_D_Actl 1;
BA_ "U_CD43_MY16_Gas_Tx" SG_ 1003 PersConflict_D_Actl 1;
BA_ "U_CD4_MY14_Diesel_Tx" SG_ 1003 PersConflict_D_Actl 1;
BA_ "U_CD4_MY14_Gas_Tx" SG_ 1003 PersConflict_D_Actl 1;
BA_ "U_CD4_MY14_Hev_Tx" SG_ 1003 PersConflict_D_Actl 1;
BA_ "U_CD4_MY14_Phev_Tx" SG_ 1003 PersConflict_D_Actl 1;
BA_ "CrossOver_InfoCAN" SG_ 1003 AssocConfirm_D_Actl 1;
BA_ "GenSigSendType" SG_ 1003 AssocConfirm_D_Actl 3;
BA_ "U_CD4_MY13_Diesel_Rx" SG_ 1003 AssocConfirm_D_Actl 1;
BA_ "U_CD4_MY13_Gas_Rx" SG_ 1003 AssocConfirm_D_Actl 1;
BA_ "U_CD4_MY13_Hev_Rx" SG_ 1003 AssocConfirm_D_Actl 1;
BA_ "U_CD4_MY13_Phev_Rx" SG_ 1003 AssocConfirm_D_Actl 1;
BA_ "U_CD42_MY14_Diesel_Rx" SG_ 1003 AssocConfirm_D_Actl 1;
BA_ "U_CD42_MY14_Gas_Rx" SG_ 1003 AssocConfirm_D_Actl 1;
BA_ "U_P552_MY15_Gas_Rx" SG_ 1003 AssocConfirm_D_Actl 1;
BA_ "U_S550_MY15_Gas_Rx" SG_ 1003 AssocConfirm_D_Actl 1;
BA_ "U_C489_MY14_Gas_Rx" SG_ 1003 AssocConfirm_D_Actl 1;
BA_ "U_U502_MY15_Gas_Rx" SG_ 1003 AssocConfirm_D_Actl 1;
BA_ "U_CD43_MY16_Gas_Rx" SG_ 1003 AssocConfirm_D_Actl 1;
BA_ "U_CD4_MY14_Diesel_Rx" SG_ 1003 AssocConfirm_D_Actl 1;
BA_ "U_CD4_MY14_Gas_Rx" SG_ 1003 AssocConfirm_D_Actl 1;
BA_ "U_CD4_MY14_Hev_Rx" SG_ 1003 AssocConfirm_D_Actl 1;
BA_ "U_CD4_MY14_Phev_Rx" SG_ 1003 AssocConfirm_D_Actl 1;
BA_ "U_CD4_MY13_Diesel_Tx" SG_ 1003 AssocConfirm_D_Actl 1;
BA_ "U_CD4_MY13_Gas_Tx" SG_ 1003 AssocConfirm_D_Actl 1;
BA_ "U_CD4_MY13_Hev_Tx" SG_ 1003 AssocConfirm_D_Actl 1;
BA_ "U_CD4_MY13_Phev_Tx" SG_ 1003 AssocConfirm_D_Actl 1;
BA_ "U_CD42_MY14_Diesel_Tx" SG_ 1003 AssocConfirm_D_Actl 1;
BA_ "U_CD42_MY14_Gas_Tx" SG_ 1003 AssocConfirm_D_Actl 1;
BA_ "U_P552_MY15_Gas_Tx" SG_ 1003 AssocConfirm_D_Actl 1;
BA_ "U_S550_MY15_Gas_Tx" SG_ 1003 AssocConfirm_D_Actl 1;
BA_ "U_C489_MY14_Gas_Tx" SG_ 1003 AssocConfirm_D_Actl 1;
BA_ "U_U502_MY15_Gas_Tx" SG_ 1003 AssocConfirm_D_Actl 1;
BA_ "U_UP375_MY15_Gas_Tx" SG_ 1003 AssocConfirm_D_Actl 1;
BA_ "U_UP375_MY15_Diesel_Tx" SG_ 1003 AssocConfirm_D_Actl 1;
BA_ "U_CD43_MY16_Gas_Tx" SG_ 1003 AssocConfirm_D_Actl 1;
BA_ "U_CD4_MY14_Diesel_Tx" SG_ 1003 AssocConfirm_D_Actl 1;
BA_ "U_CD4_MY14_Gas_Tx" SG_ 1003 AssocConfirm_D_Actl 1;
BA_ "U_CD4_MY14_Hev_Tx" SG_ 1003 AssocConfirm_D_Actl 1;
BA_ "U_CD4_MY14_Phev_Tx" SG_ 1003 AssocConfirm_D_Actl 1;
BA_ "CrossOver_InfoCAN" SG_ 1003 RecallEvent_No_Cnt 1;
BA_ "GenSigSendType" SG_ 1003 RecallEvent_No_Cnt 3;
BA_ "U_CD4_MY13_Diesel_Rx" SG_ 1003 RecallEvent_No_Cnt 1;
BA_ "U_CD4_MY13_Gas_Rx" SG_ 1003 RecallEvent_No_Cnt 1;
BA_ "U_CD4_MY13_Hev_Rx" SG_ 1003 RecallEvent_No_Cnt 1;
BA_ "U_CD4_MY13_Phev_Rx" SG_ 1003 RecallEvent_No_Cnt 1;
BA_ "U_CD42_MY14_Diesel_Rx" SG_ 1003 RecallEvent_No_Cnt 1;
BA_ "U_CD42_MY14_Gas_Rx" SG_ 1003 RecallEvent_No_Cnt 1;
BA_ "U_P552_MY15_Gas_Rx" SG_ 1003 RecallEvent_No_Cnt 1;
BA_ "U_S550_MY15_Gas_Rx" SG_ 1003 RecallEvent_No_Cnt 1;
BA_ "U_C489_MY14_Gas_Rx" SG_ 1003 RecallEvent_No_Cnt 1;
BA_ "U_U502_MY15_Gas_Rx" SG_ 1003 RecallEvent_No_Cnt 1;
BA_ "U_CD43_MY16_Gas_Rx" SG_ 1003 RecallEvent_No_Cnt 1;
BA_ "U_CD4_MY14_Diesel_Rx" SG_ 1003 RecallEvent_No_Cnt 1;
BA_ "U_CD4_MY14_Gas_Rx" SG_ 1003 RecallEvent_No_Cnt 1;
BA_ "U_CD4_MY14_Hev_Rx" SG_ 1003 RecallEvent_No_Cnt 1;
BA_ "U_CD4_MY14_Phev_Rx" SG_ 1003 RecallEvent_No_Cnt 1;
BA_ "U_CD4_MY13_Diesel_Tx" SG_ 1003 RecallEvent_No_Cnt 1;
BA_ "U_CD4_MY13_Gas_Tx" SG_ 1003 RecallEvent_No_Cnt 1;
BA_ "U_CD4_MY13_Hev_Tx" SG_ 1003 RecallEvent_No_Cnt 1;
BA_ "U_CD4_MY13_Phev_Tx" SG_ 1003 RecallEvent_No_Cnt 1;
BA_ "U_CD42_MY14_Diesel_Tx" SG_ 1003 RecallEvent_No_Cnt 1;
BA_ "U_CD42_MY14_Gas_Tx" SG_ 1003 RecallEvent_No_Cnt 1;
BA_ "U_P552_MY15_Gas_Tx" SG_ 1003 RecallEvent_No_Cnt 1;
BA_ "U_S550_MY15_Gas_Tx" SG_ 1003 RecallEvent_No_Cnt 1;
BA_ "U_C489_MY14_Gas_Tx" SG_ 1003 RecallEvent_No_Cnt 1;
BA_ "U_U502_MY15_Gas_Tx" SG_ 1003 RecallEvent_No_Cnt 1;
BA_ "U_UP375_MY15_Gas_Tx" SG_ 1003 RecallEvent_No_Cnt 1;
BA_ "U_UP375_MY15_Diesel_Tx" SG_ 1003 RecallEvent_No_Cnt 1;
BA_ "U_CD43_MY16_Gas_Tx" SG_ 1003 RecallEvent_No_Cnt 1;
BA_ "U_CD4_MY14_Diesel_Tx" SG_ 1003 RecallEvent_No_Cnt 1;
BA_ "U_CD4_MY14_Gas_Tx" SG_ 1003 RecallEvent_No_Cnt 1;
BA_ "U_CD4_MY14_Hev_Tx" SG_ 1003 RecallEvent_No_Cnt 1;
BA_ "U_CD4_MY14_Phev_Tx" SG_ 1003 RecallEvent_No_Cnt 1;
BA_ "CrossOver_InfoCAN" SG_ 1003 PersNo_D_Actl 1;
BA_ "GenSigStartValue" SG_ 1003 PersNo_D_Actl 4;
BA_ "GenSigSendType" SG_ 1003 PersNo_D_Actl 3;
BA_ "U_CD4_MY13_Diesel_Rx" SG_ 1003 PersNo_D_Actl 1;
BA_ "U_CD4_MY13_Gas_Rx" SG_ 1003 PersNo_D_Actl 1;
BA_ "U_CD4_MY13_Hev_Rx" SG_ 1003 PersNo_D_Actl 1;
BA_ "U_CD4_MY13_Phev_Rx" SG_ 1003 PersNo_D_Actl 1;
BA_ "U_CD42_MY14_Diesel_Rx" SG_ 1003 PersNo_D_Actl 1;
BA_ "U_CD42_MY14_Gas_Rx" SG_ 1003 PersNo_D_Actl 1;
BA_ "U_P552_MY15_Gas_Rx" SG_ 1003 PersNo_D_Actl 1;
BA_ "U_S550_MY15_Gas_Rx" SG_ 1003 PersNo_D_Actl 1;
BA_ "U_C489_MY14_Gas_Rx" SG_ 1003 PersNo_D_Actl 1;
BA_ "U_U502_MY15_Gas_Rx" SG_ 1003 PersNo_D_Actl 1;
BA_ "U_CD43_MY16_Gas_Rx" SG_ 1003 PersNo_D_Actl 1;
BA_ "U_CD4_MY14_Diesel_Rx" SG_ 1003 PersNo_D_Actl 1;
BA_ "U_CD4_MY14_Gas_Rx" SG_ 1003 PersNo_D_Actl 1;
BA_ "U_CD4_MY14_Hev_Rx" SG_ 1003 PersNo_D_Actl 1;
BA_ "U_CD4_MY14_Phev_Rx" SG_ 1003 PersNo_D_Actl 1;
BA_ "U_CD4_MY13_Diesel_Tx" SG_ 1003 PersNo_D_Actl 1;
BA_ "U_CD4_MY13_Gas_Tx" SG_ 1003 PersNo_D_Actl 1;
BA_ "U_CD4_MY13_Hev_Tx" SG_ 1003 PersNo_D_Actl 1;
BA_ "U_CD4_MY13_Phev_Tx" SG_ 1003 PersNo_D_Actl 1;
BA_ "U_CD42_MY14_Diesel_Tx" SG_ 1003 PersNo_D_Actl 1;
BA_ "U_CD42_MY14_Gas_Tx" SG_ 1003 PersNo_D_Actl 1;
BA_ "U_P552_MY15_Gas_Tx" SG_ 1003 PersNo_D_Actl 1;
BA_ "U_S550_MY15_Gas_Tx" SG_ 1003 PersNo_D_Actl 1;
BA_ "U_C489_MY14_Gas_Tx" SG_ 1003 PersNo_D_Actl 1;
BA_ "U_U502_MY15_Gas_Tx" SG_ 1003 PersNo_D_Actl 1;
BA_ "U_UP375_MY15_Gas_Tx" SG_ 1003 PersNo_D_Actl 1;
BA_ "U_UP375_MY15_Diesel_Tx" SG_ 1003 PersNo_D_Actl 1;
BA_ "U_CD43_MY16_Gas_Tx" SG_ 1003 PersNo_D_Actl 1;
BA_ "U_CD4_MY14_Diesel_Tx" SG_ 1003 PersNo_D_Actl 1;
BA_ "U_CD4_MY14_Gas_Tx" SG_ 1003 PersNo_D_Actl 1;
BA_ "U_CD4_MY14_Hev_Tx" SG_ 1003 PersNo_D_Actl 1;
BA_ "U_CD4_MY14_Phev_Tx" SG_ 1003 PersNo_D_Actl 1;
BA_ "GenSigSendType" SG_ 2016 TesterPhysicalReqPCM 3;
BA_ "U_CD4_MY13_Gas_Rx" SG_ 2016 TesterPhysicalReqPCM 1;
BA_ "U_CD42_MY14_Gas_Rx" SG_ 2016 TesterPhysicalReqPCM 1;
BA_ "U_P552_MY15_Gas_Rx" SG_ 2016 TesterPhysicalReqPCM 1;
BA_ "U_S550_MY15_Gas_Rx" SG_ 2016 TesterPhysicalReqPCM 1;
BA_ "U_C489_MY14_Gas_Rx" SG_ 2016 TesterPhysicalReqPCM 1;
BA_ "U_U502_MY15_Gas_Rx" SG_ 2016 TesterPhysicalReqPCM 1;
BA_ "U_CD43_MY16_Gas_Rx" SG_ 2016 TesterPhysicalReqPCM 1;
BA_ "U_CD4_MY14_Gas_Rx" SG_ 2016 TesterPhysicalReqPCM 1;
BA_ "U_CD4_MY13_Diesel_Tx" SG_ 2016 TesterPhysicalReqPCM 1;
BA_ "U_CD4_MY13_Gas_Tx" SG_ 2016 TesterPhysicalReqPCM 1;
BA_ "U_CD4_MY13_Hev_Tx" SG_ 2016 TesterPhysicalReqPCM 1;
BA_ "U_CD4_MY13_Phev_Tx" SG_ 2016 TesterPhysicalReqPCM 1;
BA_ "U_CD42_MY14_Diesel_Tx" SG_ 2016 TesterPhysicalReqPCM 1;
BA_ "U_CD42_MY14_Gas_Tx" SG_ 2016 TesterPhysicalReqPCM 1;
BA_ "U_P552_MY15_Gas_Tx" SG_ 2016 TesterPhysicalReqPCM 1;
BA_ "U_S550_MY15_Gas_Tx" SG_ 2016 TesterPhysicalReqPCM 1;
BA_ "U_C489_MY14_Gas_Tx" SG_ 2016 TesterPhysicalReqPCM 1;
BA_ "CrossOver_InfoCAN" SG_ 1034 VehicleGGCCData 1;
BA_ "U_CD4_MY13_Gas_Rx" SG_ 1034 VehicleGGCCData 1;
BA_ "U_CD42_MY14_Gas_Rx" SG_ 1034 VehicleGGCCData 1;
BA_ "U_P552_MY15_Gas_Rx" SG_ 1034 VehicleGGCCData 1;
BA_ "U_S550_MY15_Gas_Rx" SG_ 1034 VehicleGGCCData 1;
BA_ "U_C489_MY14_Gas_Rx" SG_ 1034 VehicleGGCCData 1;
BA_ "U_U502_MY15_Gas_Rx" SG_ 1034 VehicleGGCCData 1;
BA_ "U_CD43_MY16_Gas_Rx" SG_ 1034 VehicleGGCCData 1;
BA_ "U_CD4_MY14_Gas_Rx" SG_ 1034 VehicleGGCCData 1;
BA_ "U_CD4_MY13_Diesel_Tx" SG_ 1034 VehicleGGCCData 1;
BA_ "U_CD4_MY13_Gas_Tx" SG_ 1034 VehicleGGCCData 1;
BA_ "U_CD4_MY13_Hev_Tx" SG_ 1034 VehicleGGCCData 1;
BA_ "U_CD4_MY13_Phev_Tx" SG_ 1034 VehicleGGCCData 1;
BA_ "U_CD42_MY14_Diesel_Tx" SG_ 1034 VehicleGGCCData 1;
BA_ "U_CD42_MY14_Gas_Tx" SG_ 1034 VehicleGGCCData 1;
BA_ "U_P552_MY15_Gas_Tx" SG_ 1034 VehicleGGCCData 1;
BA_ "U_S550_MY15_Gas_Tx" SG_ 1034 VehicleGGCCData 1;
BA_ "U_C489_MY14_Gas_Tx" SG_ 1034 VehicleGGCCData 1;
BA_ "U_U502_MY15_Gas_Tx" SG_ 1034 VehicleGGCCData 1;
BA_ "U_UP375_MY15_Gas_Tx" SG_ 1034 VehicleGGCCData 1;
BA_ "U_UP375_MY15_Diesel_Tx" SG_ 1034 VehicleGGCCData 1;
BA_ "U_CD43_MY16_Gas_Tx" SG_ 1034 VehicleGGCCData 1;
BA_ "U_CD4_MY14_Diesel_Tx" SG_ 1034 VehicleGGCCData 1;
BA_ "U_CD4_MY14_Gas_Tx" SG_ 1034 VehicleGGCCData 1;
BA_ "U_CD4_MY14_Hev_Tx" SG_ 1034 VehicleGGCCData 1;
BA_ "U_CD4_MY14_Phev_Tx" SG_ 1034 VehicleGGCCData 1;
BA_ "GenSigTimeoutTime_TCM" SG_ 1034 VehicleGGCCData 600;
BA_ "U_CD4_MY13_Gas_Rx" SG_ 1068 EngStrtInhbt_B_RqBatt 1;
BA_ "U_CD42_MY14_Gas_Rx" SG_ 1068 EngStrtInhbt_B_RqBatt 1;
BA_ "U_P552_MY15_Gas_Rx" SG_ 1068 EngStrtInhbt_B_RqBatt 1;
BA_ "U_U502_MY15_Gas_Rx" SG_ 1068 EngStrtInhbt_B_RqBatt 1;
BA_ "U_CD43_MY16_Gas_Rx" SG_ 1068 EngStrtInhbt_B_RqBatt 1;
BA_ "U_CD4_MY14_Gas_Rx" SG_ 1068 EngStrtInhbt_B_RqBatt 1;
BA_ "U_CD4_MY13_Diesel_Tx" SG_ 1068 EngStrtInhbt_B_RqBatt 1;
BA_ "U_CD4_MY13_Gas_Tx" SG_ 1068 EngStrtInhbt_B_RqBatt 1;
BA_ "U_CD4_MY13_Hev_Tx" SG_ 1068 EngStrtInhbt_B_RqBatt 1;
BA_ "U_CD4_MY13_Phev_Tx" SG_ 1068 EngStrtInhbt_B_RqBatt 1;
BA_ "U_CD42_MY14_Diesel_Tx" SG_ 1068 EngStrtInhbt_B_RqBatt 1;
BA_ "U_CD42_MY14_Gas_Tx" SG_ 1068 EngStrtInhbt_B_RqBatt 1;
BA_ "U_P552_MY15_Gas_Tx" SG_ 1068 EngStrtInhbt_B_RqBatt 1;
BA_ "U_S550_MY15_Gas_Tx" SG_ 1068 EngStrtInhbt_B_RqBatt 1;
BA_ "U_C489_MY14_Gas_Tx" SG_ 1068 EngStrtInhbt_B_RqBatt 1;
BA_ "U_U502_MY15_Gas_Tx" SG_ 1068 EngStrtInhbt_B_RqBatt 1;
BA_ "U_UP375_MY15_Gas_Tx" SG_ 1068 EngStrtInhbt_B_RqBatt 1;
BA_ "U_UP375_MY15_Diesel_Tx" SG_ 1068 EngStrtInhbt_B_RqBatt 1;
BA_ "U_CD43_MY16_Gas_Tx" SG_ 1068 EngStrtInhbt_B_RqBatt 1;
BA_ "U_CD4_MY14_Diesel_Tx" SG_ 1068 EngStrtInhbt_B_RqBatt 1;
BA_ "U_CD4_MY14_Gas_Tx" SG_ 1068 EngStrtInhbt_B_RqBatt 1;
BA_ "U_CD4_MY14_Hev_Tx" SG_ 1068 EngStrtInhbt_B_RqBatt 1;
BA_ "U_CD4_MY14_Phev_Tx" SG_ 1068 EngStrtInhbt_B_RqBatt 1;
BA_ "U_CD4_MY13_Gas_Rx" SG_ 1068 BattULoChrg_D_Rq 1;
BA_ "U_CD42_MY14_Gas_Rx" SG_ 1068 BattULoChrg_D_Rq 1;
BA_ "U_P552_MY15_Gas_Rx" SG_ 1068 BattULoChrg_D_Rq 1;
BA_ "U_S550_MY15_Gas_Rx" SG_ 1068 BattULoChrg_D_Rq 1;
BA_ "U_U502_MY15_Gas_Rx" SG_ 1068 BattULoChrg_D_Rq 1;
BA_ "U_CD43_MY16_Gas_Rx" SG_ 1068 BattULoChrg_D_Rq 1;
BA_ "U_CD4_MY14_Gas_Rx" SG_ 1068 BattULoChrg_D_Rq 1;
BA_ "U_CD4_MY13_Diesel_Tx" SG_ 1068 BattULoChrg_D_Rq 1;
BA_ "U_CD4_MY13_Gas_Tx" SG_ 1068 BattULoChrg_D_Rq 1;
BA_ "U_CD4_MY13_Hev_Tx" SG_ 1068 BattULoChrg_D_Rq 1;
BA_ "U_CD4_MY13_Phev_Tx" SG_ 1068 BattULoChrg_D_Rq 1;
BA_ "U_CD42_MY14_Diesel_Tx" SG_ 1068 BattULoChrg_D_Rq 1;
BA_ "U_CD42_MY14_Gas_Tx" SG_ 1068 BattULoChrg_D_Rq 1;
BA_ "U_P552_MY15_Gas_Tx" SG_ 1068 BattULoChrg_D_Rq 1;
BA_ "U_S550_MY15_Gas_Tx" SG_ 1068 BattULoChrg_D_Rq 1;
BA_ "U_C489_MY14_Gas_Tx" SG_ 1068 BattULoChrg_D_Rq 1;
BA_ "U_U502_MY15_Gas_Tx" SG_ 1068 BattULoChrg_D_Rq 1;
BA_ "U_UP375_MY15_Gas_Tx" SG_ 1068 BattULoChrg_D_Rq 1;
BA_ "U_UP375_MY15_Diesel_Tx" SG_ 1068 BattULoChrg_D_Rq 1;
BA_ "U_CD43_MY16_Gas_Tx" SG_ 1068 BattULoChrg_D_Rq 1;
BA_ "U_CD4_MY14_Diesel_Tx" SG_ 1068 BattULoChrg_D_Rq 1;
BA_ "U_CD4_MY14_Gas_Tx" SG_ 1068 BattULoChrg_D_Rq 1;
BA_ "U_CD4_MY14_Hev_Tx" SG_ 1068 BattULoChrg_D_Rq 1;
BA_ "U_CD4_MY14_Phev_Tx" SG_ 1068 BattULoChrg_D_Rq 1;
BA_ "WakeupSignal" SG_ 1068 PwSysULoFalt_D_Stat 1;
BA_ "CrossOver_InfoCAN" SG_ 1068 PwSysULoFalt_D_Stat 1;
BA_ "U_CD4_MY13_Diesel_Tx" SG_ 1068 PwSysULoFalt_D_Stat 1;
BA_ "U_CD4_MY13_Gas_Tx" SG_ 1068 PwSysULoFalt_D_Stat 1;
BA_ "U_CD4_MY13_Hev_Tx" SG_ 1068 PwSysULoFalt_D_Stat 1;
BA_ "U_CD4_MY13_Phev_Tx" SG_ 1068 PwSysULoFalt_D_Stat 1;
BA_ "U_CD42_MY14_Diesel_Tx" SG_ 1068 PwSysULoFalt_D_Stat 1;
BA_ "U_CD42_MY14_Gas_Tx" SG_ 1068 PwSysULoFalt_D_Stat 1;
BA_ "U_P552_MY15_Gas_Tx" SG_ 1068 PwSysULoFalt_D_Stat 1;
BA_ "U_S550_MY15_Gas_Tx" SG_ 1068 PwSysULoFalt_D_Stat 1;
BA_ "U_C489_MY14_Gas_Tx" SG_ 1068 PwSysULoFalt_D_Stat 1;
BA_ "U_U502_MY15_Gas_Tx" SG_ 1068 PwSysULoFalt_D_Stat 1;
BA_ "U_UP375_MY15_Gas_Tx" SG_ 1068 PwSysULoFalt_D_Stat 1;
BA_ "U_UP375_MY15_Diesel_Tx" SG_ 1068 PwSysULoFalt_D_Stat 1;
BA_ "U_CD43_MY16_Gas_Tx" SG_ 1068 PwSysULoFalt_D_Stat 1;
BA_ "U_CD4_MY14_Diesel_Tx" SG_ 1068 PwSysULoFalt_D_Stat 1;
BA_ "U_CD4_MY14_Gas_Tx" SG_ 1068 PwSysULoFalt_D_Stat 1;
BA_ "U_CD4_MY14_Hev_Tx" SG_ 1068 PwSysULoFalt_D_Stat 1;
BA_ "U_CD4_MY14_Phev_Tx" SG_ 1068 PwSysULoFalt_D_Stat 1;
BA_ "CrossOver_InfoCAN" SG_ 1068 Shed_T_Eng_Off_B 1;
BA_ "U_CD4_MY13_Diesel_Tx" SG_ 1068 Shed_T_Eng_Off_B 1;
BA_ "U_CD4_MY13_Gas_Tx" SG_ 1068 Shed_T_Eng_Off_B 1;
BA_ "U_CD4_MY13_Hev_Tx" SG_ 1068 Shed_T_Eng_Off_B 1;
BA_ "U_CD4_MY13_Phev_Tx" SG_ 1068 Shed_T_Eng_Off_B 1;
BA_ "U_CD42_MY14_Diesel_Tx" SG_ 1068 Shed_T_Eng_Off_B 1;
BA_ "U_CD42_MY14_Gas_Tx" SG_ 1068 Shed_T_Eng_Off_B 1;
BA_ "U_P552_MY15_Gas_Tx" SG_ 1068 Shed_T_Eng_Off_B 1;
BA_ "U_S550_MY15_Gas_Tx" SG_ 1068 Shed_T_Eng_Off_B 1;
BA_ "U_C489_MY14_Gas_Tx" SG_ 1068 Shed_T_Eng_Off_B 1;
BA_ "U_U502_MY15_Gas_Tx" SG_ 1068 Shed_T_Eng_Off_B 1;
BA_ "U_UP375_MY15_Gas_Tx" SG_ 1068 Shed_T_Eng_Off_B 1;
BA_ "U_UP375_MY15_Diesel_Tx" SG_ 1068 Shed_T_Eng_Off_B 1;
BA_ "U_CD43_MY16_Gas_Tx" SG_ 1068 Shed_T_Eng_Off_B 1;
BA_ "U_CD4_MY14_Diesel_Tx" SG_ 1068 Shed_T_Eng_Off_B 1;
BA_ "U_CD4_MY14_Gas_Tx" SG_ 1068 Shed_T_Eng_Off_B 1;
BA_ "U_CD4_MY14_Hev_Tx" SG_ 1068 Shed_T_Eng_Off_B 1;
BA_ "U_CD4_MY14_Phev_Tx" SG_ 1068 Shed_T_Eng_Off_B 1;
BA_ "WakeupSignal" SG_ 1068 Shed_Feature_Group_ID 1;
BA_ "U_CD4_MY13_Gas_Rx" SG_ 1068 Shed_Feature_Group_ID 1;
BA_ "U_CD42_MY14_Gas_Rx" SG_ 1068 Shed_Feature_Group_ID 1;
BA_ "U_P552_MY15_Gas_Rx" SG_ 1068 Shed_Feature_Group_ID 1;
BA_ "U_S550_MY15_Gas_Rx" SG_ 1068 Shed_Feature_Group_ID 1;
BA_ "U_C489_MY14_Gas_Rx" SG_ 1068 Shed_Feature_Group_ID 1;
BA_ "U_U502_MY15_Gas_Rx" SG_ 1068 Shed_Feature_Group_ID 1;
BA_ "U_CD43_MY16_Gas_Rx" SG_ 1068 Shed_Feature_Group_ID 1;
BA_ "U_CD4_MY14_Gas_Rx" SG_ 1068 Shed_Feature_Group_ID 1;
BA_ "U_CD4_MY13_Diesel_Tx" SG_ 1068 Shed_Feature_Group_ID 1;
BA_ "U_CD4_MY13_Gas_Tx" SG_ 1068 Shed_Feature_Group_ID 1;
BA_ "U_CD4_MY13_Hev_Tx" SG_ 1068 Shed_Feature_Group_ID 1;
BA_ "U_CD4_MY13_Phev_Tx" SG_ 1068 Shed_Feature_Group_ID 1;
BA_ "U_CD42_MY14_Diesel_Tx" SG_ 1068 Shed_Feature_Group_ID 1;
BA_ "U_CD42_MY14_Gas_Tx" SG_ 1068 Shed_Feature_Group_ID 1;
BA_ "U_P552_MY15_Gas_Tx" SG_ 1068 Shed_Feature_Group_ID 1;
BA_ "U_S550_MY15_Gas_Tx" SG_ 1068 Shed_Feature_Group_ID 1;
BA_ "U_C489_MY14_Gas_Tx" SG_ 1068 Shed_Feature_Group_ID 1;
BA_ "U_U502_MY15_Gas_Tx" SG_ 1068 Shed_Feature_Group_ID 1;
BA_ "U_UP375_MY15_Gas_Tx" SG_ 1068 Shed_Feature_Group_ID 1;
BA_ "U_UP375_MY15_Diesel_Tx" SG_ 1068 Shed_Feature_Group_ID 1;
BA_ "U_CD43_MY16_Gas_Tx" SG_ 1068 Shed_Feature_Group_ID 1;
BA_ "U_CD4_MY14_Diesel_Tx" SG_ 1068 Shed_Feature_Group_ID 1;
BA_ "U_CD4_MY14_Gas_Tx" SG_ 1068 Shed_Feature_Group_ID 1;
BA_ "U_CD4_MY14_Hev_Tx" SG_ 1068 Shed_Feature_Group_ID 1;
BA_ "U_CD4_MY14_Phev_Tx" SG_ 1068 Shed_Feature_Group_ID 1;
BA_ "CrossOver_InfoCAN" SG_ 1068 Shed_Drain_Eng_Off_B 1;
BA_ "U_CD4_MY13_Diesel_Tx" SG_ 1068 Shed_Drain_Eng_Off_B 1;
BA_ "U_CD4_MY13_Gas_Tx" SG_ 1068 Shed_Drain_Eng_Off_B 1;
BA_ "U_CD4_MY13_Hev_Tx" SG_ 1068 Shed_Drain_Eng_Off_B 1;
BA_ "U_CD4_MY13_Phev_Tx" SG_ 1068 Shed_Drain_Eng_Off_B 1;
BA_ "U_CD42_MY14_Diesel_Tx" SG_ 1068 Shed_Drain_Eng_Off_B 1;
BA_ "U_CD42_MY14_Gas_Tx" SG_ 1068 Shed_Drain_Eng_Off_B 1;
BA_ "U_P552_MY15_Gas_Tx" SG_ 1068 Shed_Drain_Eng_Off_B 1;
BA_ "U_S550_MY15_Gas_Tx" SG_ 1068 Shed_Drain_Eng_Off_B 1;
BA_ "U_C489_MY14_Gas_Tx" SG_ 1068 Shed_Drain_Eng_Off_B 1;
BA_ "U_U502_MY15_Gas_Tx" SG_ 1068 Shed_Drain_Eng_Off_B 1;
BA_ "U_UP375_MY15_Gas_Tx" SG_ 1068 Shed_Drain_Eng_Off_B 1;
BA_ "U_UP375_MY15_Diesel_Tx" SG_ 1068 Shed_Drain_Eng_Off_B 1;
BA_ "U_CD43_MY16_Gas_Tx" SG_ 1068 Shed_Drain_Eng_Off_B 1;
BA_ "U_CD4_MY14_Diesel_Tx" SG_ 1068 Shed_Drain_Eng_Off_B 1;
BA_ "U_CD4_MY14_Gas_Tx" SG_ 1068 Shed_Drain_Eng_Off_B 1;
BA_ "U_CD4_MY14_Hev_Tx" SG_ 1068 Shed_Drain_Eng_Off_B 1;
BA_ "U_CD4_MY14_Phev_Tx" SG_ 1068 Shed_Drain_Eng_Off_B 1;
BA_ "WakeupSignal" SG_ 1068 Shed_Level_Req 1;
BA_ "CrossOver_InfoCAN" SG_ 1068 Shed_Level_Req 1;
BA_ "U_CD4_MY13_Gas_Rx" SG_ 1068 Shed_Level_Req 1;
BA_ "U_CD42_MY14_Gas_Rx" SG_ 1068 Shed_Level_Req 1;
BA_ "U_P552_MY15_Gas_Rx" SG_ 1068 Shed_Level_Req 1;
BA_ "U_S550_MY15_Gas_Rx" SG_ 1068 Shed_Level_Req 1;
BA_ "U_C489_MY14_Gas_Rx" SG_ 1068 Shed_Level_Req 1;
BA_ "U_U502_MY15_Gas_Rx" SG_ 1068 Shed_Level_Req 1;
BA_ "U_CD43_MY16_Gas_Rx" SG_ 1068 Shed_Level_Req 1;
BA_ "U_CD4_MY14_Gas_Rx" SG_ 1068 Shed_Level_Req 1;
BA_ "U_CD4_MY13_Diesel_Tx" SG_ 1068 Shed_Level_Req 1;
BA_ "U_CD4_MY13_Gas_Tx" SG_ 1068 Shed_Level_Req 1;
BA_ "U_CD4_MY13_Hev_Tx" SG_ 1068 Shed_Level_Req 1;
BA_ "U_CD4_MY13_Phev_Tx" SG_ 1068 Shed_Level_Req 1;
BA_ "U_CD42_MY14_Diesel_Tx" SG_ 1068 Shed_Level_Req 1;
BA_ "U_CD42_MY14_Gas_Tx" SG_ 1068 Shed_Level_Req 1;
BA_ "U_P552_MY15_Gas_Tx" SG_ 1068 Shed_Level_Req 1;
BA_ "U_S550_MY15_Gas_Tx" SG_ 1068 Shed_Level_Req 1;
BA_ "U_C489_MY14_Gas_Tx" SG_ 1068 Shed_Level_Req 1;
BA_ "U_U502_MY15_Gas_Tx" SG_ 1068 Shed_Level_Req 1;
BA_ "U_UP375_MY15_Gas_Tx" SG_ 1068 Shed_Level_Req 1;
BA_ "U_UP375_MY15_Diesel_Tx" SG_ 1068 Shed_Level_Req 1;
BA_ "U_CD43_MY16_Gas_Tx" SG_ 1068 Shed_Level_Req 1;
BA_ "U_CD4_MY14_Diesel_Tx" SG_ 1068 Shed_Level_Req 1;
BA_ "U_CD4_MY14_Gas_Tx" SG_ 1068 Shed_Level_Req 1;
BA_ "U_CD4_MY14_Hev_Tx" SG_ 1068 Shed_Level_Req 1;
BA_ "U_CD4_MY14_Phev_Tx" SG_ 1068 Shed_Level_Req 1;
BA_ "U_CD4_MY13_Diesel_Tx" SG_ 1068 BattULoSrvc_T_Actl 1;
BA_ "U_CD4_MY13_Gas_Tx" SG_ 1068 BattULoSrvc_T_Actl 1;
BA_ "U_CD4_MY13_Hev_Tx" SG_ 1068 BattULoSrvc_T_Actl 1;
BA_ "U_CD4_MY13_Phev_Tx" SG_ 1068 BattULoSrvc_T_Actl 1;
BA_ "U_CD42_MY14_Diesel_Tx" SG_ 1068 BattULoSrvc_T_Actl 1;
BA_ "U_CD42_MY14_Gas_Tx" SG_ 1068 BattULoSrvc_T_Actl 1;
BA_ "U_P552_MY15_Gas_Tx" SG_ 1068 BattULoSrvc_T_Actl 1;
BA_ "U_S550_MY15_Gas_Tx" SG_ 1068 BattULoSrvc_T_Actl 1;
BA_ "U_C489_MY14_Gas_Tx" SG_ 1068 BattULoSrvc_T_Actl 1;
BA_ "U_U502_MY15_Gas_Tx" SG_ 1068 BattULoSrvc_T_Actl 1;
BA_ "U_UP375_MY15_Gas_Tx" SG_ 1068 BattULoSrvc_T_Actl 1;
BA_ "U_UP375_MY15_Diesel_Tx" SG_ 1068 BattULoSrvc_T_Actl 1;
BA_ "U_CD43_MY16_Gas_Tx" SG_ 1068 BattULoSrvc_T_Actl 1;
BA_ "U_CD4_MY14_Diesel_Tx" SG_ 1068 BattULoSrvc_T_Actl 1;
BA_ "U_CD4_MY14_Gas_Tx" SG_ 1068 BattULoSrvc_T_Actl 1;
BA_ "U_CD4_MY14_Hev_Tx" SG_ 1068 BattULoSrvc_T_Actl 1;
BA_ "U_CD4_MY14_Phev_Tx" SG_ 1068 BattULoSrvc_T_Actl 1;
BA_ "U_CD4_MY13_Gas_Rx" SG_ 1068 ULoRgenTestMde_B_Rq 1;
BA_ "U_CD42_MY14_Gas_Rx" SG_ 1068 ULoRgenTestMde_B_Rq 1;
BA_ "U_P552_MY15_Gas_Rx" SG_ 1068 ULoRgenTestMde_B_Rq 1;
BA_ "U_S550_MY15_Gas_Rx" SG_ 1068 ULoRgenTestMde_B_Rq 1;
BA_ "U_C489_MY14_Gas_Rx" SG_ 1068 ULoRgenTestMde_B_Rq 1;
BA_ "U_U502_MY15_Gas_Rx" SG_ 1068 ULoRgenTestMde_B_Rq 1;
BA_ "U_CD43_MY16_Gas_Rx" SG_ 1068 ULoRgenTestMde_B_Rq 1;
BA_ "U_CD4_MY14_Gas_Rx" SG_ 1068 ULoRgenTestMde_B_Rq 1;
BA_ "U_CD4_MY13_Diesel_Tx" SG_ 1068 ULoRgenTestMde_B_Rq 1;
BA_ "U_CD4_MY13_Gas_Tx" SG_ 1068 ULoRgenTestMde_B_Rq 1;
BA_ "U_CD4_MY13_Hev_Tx" SG_ 1068 ULoRgenTestMde_B_Rq 1;
BA_ "U_CD4_MY13_Phev_Tx" SG_ 1068 ULoRgenTestMde_B_Rq 1;
BA_ "U_CD42_MY14_Diesel_Tx" SG_ 1068 ULoRgenTestMde_B_Rq 1;
BA_ "U_CD42_MY14_Gas_Tx" SG_ 1068 ULoRgenTestMde_B_Rq 1;
BA_ "U_P552_MY15_Gas_Tx" SG_ 1068 ULoRgenTestMde_B_Rq 1;
BA_ "U_S550_MY15_Gas_Tx" SG_ 1068 ULoRgenTestMde_B_Rq 1;
BA_ "U_C489_MY14_Gas_Tx" SG_ 1068 ULoRgenTestMde_B_Rq 1;
BA_ "U_U502_MY15_Gas_Tx" SG_ 1068 ULoRgenTestMde_B_Rq 1;
BA_ "U_UP375_MY15_Gas_Tx" SG_ 1068 ULoRgenTestMde_B_Rq 1;
BA_ "U_UP375_MY15_Diesel_Tx" SG_ 1068 ULoRgenTestMde_B_Rq 1;
BA_ "U_CD43_MY16_Gas_Tx" SG_ 1068 ULoRgenTestMde_B_Rq 1;
BA_ "U_CD4_MY14_Diesel_Tx" SG_ 1068 ULoRgenTestMde_B_Rq 1;
BA_ "U_CD4_MY14_Gas_Tx" SG_ 1068 ULoRgenTestMde_B_Rq 1;
BA_ "U_CD4_MY14_Hev_Tx" SG_ 1068 ULoRgenTestMde_B_Rq 1;
BA_ "U_CD4_MY14_Phev_Tx" SG_ 1068 ULoRgenTestMde_B_Rq 1;
BA_ "U_CD4_MY13_Gas_Rx" SG_ 1068 ChargeMode 1;
BA_ "U_CD42_MY14_Gas_Rx" SG_ 1068 ChargeMode 1;
BA_ "U_P552_MY15_Gas_Rx" SG_ 1068 ChargeMode 1;
BA_ "U_S550_MY15_Gas_Rx" SG_ 1068 ChargeMode 1;
BA_ "U_C489_MY14_Gas_Rx" SG_ 1068 ChargeMode 1;
BA_ "U_U502_MY15_Gas_Rx" SG_ 1068 ChargeMode 1;
BA_ "U_CD43_MY16_Gas_Rx" SG_ 1068 ChargeMode 1;
BA_ "U_CD4_MY14_Gas_Rx" SG_ 1068 ChargeMode 1;
BA_ "U_CD4_MY13_Diesel_Tx" SG_ 1068 ChargeMode 1;
BA_ "U_CD4_MY13_Gas_Tx" SG_ 1068 ChargeMode 1;
BA_ "U_CD4_MY13_Hev_Tx" SG_ 1068 ChargeMode 1;
BA_ "U_CD4_MY13_Phev_Tx" SG_ 1068 ChargeMode 1;
BA_ "U_CD42_MY14_Diesel_Tx" SG_ 1068 ChargeMode 1;
BA_ "U_CD42_MY14_Gas_Tx" SG_ 1068 ChargeMode 1;
BA_ "U_P552_MY15_Gas_Tx" SG_ 1068 ChargeMode 1;
BA_ "U_S550_MY15_Gas_Tx" SG_ 1068 ChargeMode 1;
BA_ "U_C489_MY14_Gas_Tx" SG_ 1068 ChargeMode 1;
BA_ "U_U502_MY15_Gas_Tx" SG_ 1068 ChargeMode 1;
BA_ "U_UP375_MY15_Gas_Tx" SG_ 1068 ChargeMode 1;
BA_ "U_UP375_MY15_Diesel_Tx" SG_ 1068 ChargeMode 1;
BA_ "U_CD43_MY16_Gas_Tx" SG_ 1068 ChargeMode 1;
BA_ "U_CD4_MY14_Diesel_Tx" SG_ 1068 ChargeMode 1;
BA_ "U_CD4_MY14_Gas_Tx" SG_ 1068 ChargeMode 1;
BA_ "U_CD4_MY14_Hev_Tx" SG_ 1068 ChargeMode 1;
BA_ "U_CD4_MY14_Phev_Tx" SG_ 1068 ChargeMode 1;
BA_ "U_CD4_MY13_Diesel_Tx" SG_ 1068 IdleSpeedIncrease_El 1;
BA_ "U_CD4_MY13_Gas_Tx" SG_ 1068 IdleSpeedIncrease_El 1;
BA_ "U_CD4_MY13_Hev_Tx" SG_ 1068 IdleSpeedIncrease_El 1;
BA_ "U_CD4_MY13_Phev_Tx" SG_ 1068 IdleSpeedIncrease_El 1;
BA_ "U_CD42_MY14_Diesel_Tx" SG_ 1068 IdleSpeedIncrease_El 1;
BA_ "U_CD42_MY14_Gas_Tx" SG_ 1068 IdleSpeedIncrease_El 1;
BA_ "U_P552_MY15_Gas_Tx" SG_ 1068 IdleSpeedIncrease_El 1;
BA_ "U_S550_MY15_Gas_Tx" SG_ 1068 IdleSpeedIncrease_El 1;
BA_ "U_C489_MY14_Gas_Tx" SG_ 1068 IdleSpeedIncrease_El 1;
BA_ "U_U502_MY15_Gas_Tx" SG_ 1068 IdleSpeedIncrease_El 1;
BA_ "U_UP375_MY15_Gas_Tx" SG_ 1068 IdleSpeedIncrease_El 1;
BA_ "U_UP375_MY15_Diesel_Tx" SG_ 1068 IdleSpeedIncrease_El 1;
BA_ "U_CD43_MY16_Gas_Tx" SG_ 1068 IdleSpeedIncrease_El 1;
BA_ "U_CD4_MY14_Diesel_Tx" SG_ 1068 IdleSpeedIncrease_El 1;
BA_ "U_CD4_MY14_Gas_Tx" SG_ 1068 IdleSpeedIncrease_El 1;
BA_ "U_CD4_MY14_Hev_Tx" SG_ 1068 IdleSpeedIncrease_El 1;
BA_ "U_CD4_MY14_Phev_Tx" SG_ 1068 IdleSpeedIncrease_El 1;
BA_ "CrossOver_InfoCAN" SG_ 1068 Batt_Lo_SoC_B 1;
BA_ "U_CD4_MY13_Diesel_Tx" SG_ 1068 Batt_Lo_SoC_B 1;
BA_ "U_CD4_MY13_Gas_Tx" SG_ 1068 Batt_Lo_SoC_B 1;
BA_ "U_CD4_MY13_Hev_Tx" SG_ 1068 Batt_Lo_SoC_B 1;
BA_ "U_CD4_MY13_Phev_Tx" SG_ 1068 Batt_Lo_SoC_B 1;
BA_ "U_CD42_MY14_Diesel_Tx" SG_ 1068 Batt_Lo_SoC_B 1;
BA_ "U_CD42_MY14_Gas_Tx" SG_ 1068 Batt_Lo_SoC_B 1;
BA_ "U_P552_MY15_Gas_Tx" SG_ 1068 Batt_Lo_SoC_B 1;
BA_ "U_S550_MY15_Gas_Tx" SG_ 1068 Batt_Lo_SoC_B 1;
BA_ "U_C489_MY14_Gas_Tx" SG_ 1068 Batt_Lo_SoC_B 1;
BA_ "U_U502_MY15_Gas_Tx" SG_ 1068 Batt_Lo_SoC_B 1;
BA_ "U_UP375_MY15_Gas_Tx" SG_ 1068 Batt_Lo_SoC_B 1;
BA_ "U_UP375_MY15_Diesel_Tx" SG_ 1068 Batt_Lo_SoC_B 1;
BA_ "U_CD43_MY16_Gas_Tx" SG_ 1068 Batt_Lo_SoC_B 1;
BA_ "U_CD4_MY14_Diesel_Tx" SG_ 1068 Batt_Lo_SoC_B 1;
BA_ "U_CD4_MY14_Gas_Tx" SG_ 1068 Batt_Lo_SoC_B 1;
BA_ "U_CD4_MY14_Hev_Tx" SG_ 1068 Batt_Lo_SoC_B 1;
BA_ "U_CD4_MY14_Phev_Tx" SG_ 1068 Batt_Lo_SoC_B 1;
BA_ "U_CD4_MY13_Gas_Rx" SG_ 1068 PeriodicElLoad_B_Stat 1;
BA_ "U_CD42_MY14_Gas_Rx" SG_ 1068 PeriodicElLoad_B_Stat 1;
BA_ "U_P552_MY15_Gas_Rx" SG_ 1068 PeriodicElLoad_B_Stat 1;
BA_ "U_S550_MY15_Gas_Rx" SG_ 1068 PeriodicElLoad_B_Stat 1;
BA_ "U_C489_MY14_Gas_Rx" SG_ 1068 PeriodicElLoad_B_Stat 1;
BA_ "U_U502_MY15_Gas_Rx" SG_ 1068 PeriodicElLoad_B_Stat 1;
BA_ "U_CD43_MY16_Gas_Rx" SG_ 1068 PeriodicElLoad_B_Stat 1;
BA_ "U_CD4_MY14_Gas_Rx" SG_ 1068 PeriodicElLoad_B_Stat 1;
BA_ "U_CD4_MY13_Diesel_Tx" SG_ 1068 PeriodicElLoad_B_Stat 1;
BA_ "U_CD4_MY13_Gas_Tx" SG_ 1068 PeriodicElLoad_B_Stat 1;
BA_ "U_CD4_MY13_Hev_Tx" SG_ 1068 PeriodicElLoad_B_Stat 1;
BA_ "U_CD4_MY13_Phev_Tx" SG_ 1068 PeriodicElLoad_B_Stat 1;
BA_ "U_CD42_MY14_Diesel_Tx" SG_ 1068 PeriodicElLoad_B_Stat 1;
BA_ "U_CD42_MY14_Gas_Tx" SG_ 1068 PeriodicElLoad_B_Stat 1;
BA_ "U_P552_MY15_Gas_Tx" SG_ 1068 PeriodicElLoad_B_Stat 1;
BA_ "U_S550_MY15_Gas_Tx" SG_ 1068 PeriodicElLoad_B_Stat 1;
BA_ "U_C489_MY14_Gas_Tx" SG_ 1068 PeriodicElLoad_B_Stat 1;
BA_ "U_U502_MY15_Gas_Tx" SG_ 1068 PeriodicElLoad_B_Stat 1;
BA_ "U_UP375_MY15_Gas_Tx" SG_ 1068 PeriodicElLoad_B_Stat 1;
BA_ "U_UP375_MY15_Diesel_Tx" SG_ 1068 PeriodicElLoad_B_Stat 1;
BA_ "U_CD43_MY16_Gas_Tx" SG_ 1068 PeriodicElLoad_B_Stat 1;
BA_ "U_CD4_MY14_Diesel_Tx" SG_ 1068 PeriodicElLoad_B_Stat 1;
BA_ "U_CD4_MY14_Gas_Tx" SG_ 1068 PeriodicElLoad_B_Stat 1;
BA_ "U_CD4_MY14_Hev_Tx" SG_ 1068 PeriodicElLoad_B_Stat 1;
BA_ "U_CD4_MY14_Phev_Tx" SG_ 1068 PeriodicElLoad_B_Stat 1;
BA_ "CrossOver_InfoCAN" SG_ 1068 Batt_Crit_SoC_B 1;
BA_ "U_CD4_MY13_Diesel_Tx" SG_ 1068 Batt_Crit_SoC_B 1;
BA_ "U_CD4_MY13_Gas_Tx" SG_ 1068 Batt_Crit_SoC_B 1;
BA_ "U_CD4_MY13_Hev_Tx" SG_ 1068 Batt_Crit_SoC_B 1;
BA_ "U_CD4_MY13_Phev_Tx" SG_ 1068 Batt_Crit_SoC_B 1;
BA_ "U_CD42_MY14_Diesel_Tx" SG_ 1068 Batt_Crit_SoC_B 1;
BA_ "U_CD42_MY14_Gas_Tx" SG_ 1068 Batt_Crit_SoC_B 1;
BA_ "U_P552_MY15_Gas_Tx" SG_ 1068 Batt_Crit_SoC_B 1;
BA_ "U_S550_MY15_Gas_Tx" SG_ 1068 Batt_Crit_SoC_B 1;
BA_ "U_C489_MY14_Gas_Tx" SG_ 1068 Batt_Crit_SoC_B 1;
BA_ "U_U502_MY15_Gas_Tx" SG_ 1068 Batt_Crit_SoC_B 1;
BA_ "U_UP375_MY15_Gas_Tx" SG_ 1068 Batt_Crit_SoC_B 1;
BA_ "U_UP375_MY15_Diesel_Tx" SG_ 1068 Batt_Crit_SoC_B 1;
BA_ "U_CD43_MY16_Gas_Tx" SG_ 1068 Batt_Crit_SoC_B 1;
BA_ "U_CD4_MY14_Diesel_Tx" SG_ 1068 Batt_Crit_SoC_B 1;
BA_ "U_CD4_MY14_Gas_Tx" SG_ 1068 Batt_Crit_SoC_B 1;
BA_ "U_CD4_MY14_Hev_Tx" SG_ 1068 Batt_Crit_SoC_B 1;
BA_ "U_CD4_MY14_Phev_Tx" SG_ 1068 Batt_Crit_SoC_B 1;
BA_ "GenSigSendType" SG_ 947 ValetMode_D_Mem 3;
BA_ "U_CD4_MY17_Diesel_Tx" SG_ 947 ValetMode_D_Mem 1;
BA_ "U_CD4_MY17_Gas_Tx" SG_ 947 ValetMode_D_Mem 1;
BA_ "U_CD4_MY17_Hev_Tx" SG_ 947 ValetMode_D_Mem 1;
BA_ "U_CD4_MY17_Phev_Tx" SG_ 947 ValetMode_D_Mem 1;
BA_ "U_U55x_MY18_Gas_Tx" SG_ 947 ValetMode_D_Mem 1;
BA_ "Gateway_ID" SG_ 947 DimmingLvlEvnt_No_Actl 27603;
BA_ "U_V36X_MY16_5_Diesel_Tx" SG_ 947 DimmingLvlEvnt_No_Actl 1;
BA_ "U_P558_MY17_Diesel_Tx" SG_ 947 DimmingLvlEvnt_No_Actl 1;
BA_ "U_P558_MY17_Gas_Tx" SG_ 947 DimmingLvlEvnt_No_Actl 1;
BA_ "U_CD4_MY15_Phev_Tx" SG_ 947 DimmingLvlEvnt_No_Actl 1;
BA_ "U_CD4_MY15_Hev_Tx" SG_ 947 DimmingLvlEvnt_No_Actl 1;
BA_ "U_CD4_MY15_Gas_Tx" SG_ 947 DimmingLvlEvnt_No_Actl 1;
BA_ "U_CD4_MY15_Diesel_Tx" SG_ 947 DimmingLvlEvnt_No_Actl 1;
BA_ "U_UP375_MY15_Diesel_Tx" SG_ 947 DimmingLvlEvnt_No_Actl 1;
BA_ "U_UP375_MY15_Gas_Tx" SG_ 947 DimmingLvlEvnt_No_Actl 1;
BA_ "U_S550_MY15_Gas_Tx" SG_ 947 DimmingLvlEvnt_No_Actl 1;
BA_ "U_CD42_MY15_Gas_Tx" SG_ 947 DimmingLvlEvnt_No_Actl 1;
BA_ "U_CD42_MY15_Diesel_Tx" SG_ 947 DimmingLvlEvnt_No_Actl 1;
BA_ "WakeupSignal" SG_ 947 DimmingLvlEvnt_No_Actl 1;
BA_ "GenSigSendType" SG_ 947 DimmingLvlEvnt_No_Actl 3;
BA_ "GenSigSendType" SG_ 947 DrStatDrvErrCnt_B_Stat 3;
BA_ "U_U502_MY15_Gas_Rx" SG_ 947 DrStatDrvErrCnt_B_Stat 1;
BA_ "U_CD43_MY16_Gas_Rx" SG_ 947 DrStatDrvErrCnt_B_Stat 1;
BA_ "U_CD4_MY14_Gas_Rx" SG_ 947 DrStatDrvErrCnt_B_Stat 1;
BA_ "U_CD4_MY13_Diesel_Tx" SG_ 947 DrStatDrvErrCnt_B_Stat 1;
BA_ "U_CD4_MY13_Gas_Tx" SG_ 947 DrStatDrvErrCnt_B_Stat 1;
BA_ "U_CD4_MY13_Hev_Tx" SG_ 947 DrStatDrvErrCnt_B_Stat 1;
BA_ "U_CD4_MY13_Phev_Tx" SG_ 947 DrStatDrvErrCnt_B_Stat 1;
BA_ "U_CD42_MY14_Diesel_Tx" SG_ 947 DrStatDrvErrCnt_B_Stat 1;
BA_ "U_CD42_MY14_Gas_Tx" SG_ 947 DrStatDrvErrCnt_B_Stat 1;
BA_ "U_P552_MY15_Gas_Tx" SG_ 947 DrStatDrvErrCnt_B_Stat 1;
BA_ "U_S550_MY15_Gas_Tx" SG_ 947 DrStatDrvErrCnt_B_Stat 1;
BA_ "U_C489_MY14_Gas_Tx" SG_ 947 DrStatDrvErrCnt_B_Stat 1;
BA_ "U_U502_MY15_Gas_Tx" SG_ 947 DrStatDrvErrCnt_B_Stat 1;
BA_ "U_UP375_MY15_Gas_Tx" SG_ 947 DrStatDrvErrCnt_B_Stat 1;
BA_ "U_UP375_MY15_Diesel_Tx" SG_ 947 DrStatDrvErrCnt_B_Stat 1;
BA_ "U_CD43_MY16_Gas_Tx" SG_ 947 DrStatDrvErrCnt_B_Stat 1;
BA_ "U_CD4_MY14_Diesel_Tx" SG_ 947 DrStatDrvErrCnt_B_Stat 1;
BA_ "U_CD4_MY14_Gas_Tx" SG_ 947 DrStatDrvErrCnt_B_Stat 1;
BA_ "U_CD4_MY14_Hev_Tx" SG_ 947 DrStatDrvErrCnt_B_Stat 1;
BA_ "U_CD4_MY14_Phev_Tx" SG_ 947 DrStatDrvErrCnt_B_Stat 1;
BA_ "WakeupSignal" SG_ 947 TurnLghtRight_D_Rq 1;
BA_ "CrossOver_InfoCAN" SG_ 947 TurnLghtRight_D_Rq 1;
BA_ "GenSigSendType" SG_ 947 TurnLghtRight_D_Rq 3;
BA_ "U_CD4_MY13_Diesel_Rx" SG_ 947 TurnLghtRight_D_Rq 1;
BA_ "U_CD4_MY13_Gas_Rx" SG_ 947 TurnLghtRight_D_Rq 1;
BA_ "U_CD4_MY13_Hev_Rx" SG_ 947 TurnLghtRight_D_Rq 1;
BA_ "U_CD4_MY13_Phev_Rx" SG_ 947 TurnLghtRight_D_Rq 1;
BA_ "U_CD42_MY14_Diesel_Rx" SG_ 947 TurnLghtRight_D_Rq 1;
BA_ "U_CD42_MY14_Gas_Rx" SG_ 947 TurnLghtRight_D_Rq 1;
BA_ "U_P552_MY15_Gas_Rx" SG_ 947 TurnLghtRight_D_Rq 1;
BA_ "U_S550_MY15_Gas_Rx" SG_ 947 TurnLghtRight_D_Rq 1;
BA_ "U_C489_MY14_Gas_Rx" SG_ 947 TurnLghtRight_D_Rq 1;
BA_ "U_U502_MY15_Gas_Rx" SG_ 947 TurnLghtRight_D_Rq 1;
BA_ "U_B479_MY15_Gas_Rx" SG_ 947 TurnLghtRight_D_Rq 1;
BA_ "U_UP375_MY15_Gas_Rx" SG_ 947 TurnLghtRight_D_Rq 1;
BA_ "U_UP375_MY15_Diesel_Rx" SG_ 947 TurnLghtRight_D_Rq 1;
BA_ "U_CD4_MY13_Diesel_Tx" SG_ 947 TurnLghtRight_D_Rq 1;
BA_ "U_CD4_MY13_Gas_Tx" SG_ 947 TurnLghtRight_D_Rq 1;
BA_ "U_CD4_MY13_Hev_Tx" SG_ 947 TurnLghtRight_D_Rq 1;
BA_ "U_CD4_MY13_Phev_Tx" SG_ 947 TurnLghtRight_D_Rq 1;
BA_ "U_CD42_MY14_Diesel_Tx" SG_ 947 TurnLghtRight_D_Rq 1;
BA_ "U_CD42_MY14_Gas_Tx" SG_ 947 TurnLghtRight_D_Rq 1;
BA_ "U_P552_MY15_Gas_Tx" SG_ 947 TurnLghtRight_D_Rq 1;
BA_ "U_S550_MY15_Gas_Tx" SG_ 947 TurnLghtRight_D_Rq 1;
BA_ "U_C489_MY14_Gas_Tx" SG_ 947 TurnLghtRight_D_Rq 1;
BA_ "U_U502_MY15_Gas_Tx" SG_ 947 TurnLghtRight_D_Rq 1;
BA_ "U_UP375_MY15_Gas_Tx" SG_ 947 TurnLghtRight_D_Rq 1;
BA_ "U_UP375_MY15_Diesel_Tx" SG_ 947 TurnLghtRight_D_Rq 1;
BA_ "U_CD43_MY16_Gas_Tx" SG_ 947 TurnLghtRight_D_Rq 1;
BA_ "U_CD4_MY14_Diesel_Tx" SG_ 947 TurnLghtRight_D_Rq 1;
BA_ "U_CD4_MY14_Gas_Tx" SG_ 947 TurnLghtRight_D_Rq 1;
BA_ "U_CD4_MY14_Hev_Tx" SG_ 947 TurnLghtRight_D_Rq 1;
BA_ "U_CD4_MY14_Phev_Tx" SG_ 947 TurnLghtRight_D_Rq 1;
BA_ "CrossOver_InfoCAN" SG_ 947 TurnLghtRightOn_B_Stat 1;
BA_ "CrossOver_LIN" SG_ 947 TurnLghtRightOn_B_Stat 1;
BA_ "GenSigSendType" SG_ 947 TurnLghtRightOn_B_Stat 3;
BA_ "U_CD4_MY13_Diesel_Tx" SG_ 947 TurnLghtRightOn_B_Stat 1;
BA_ "U_CD4_MY13_Gas_Tx" SG_ 947 TurnLghtRightOn_B_Stat 1;
BA_ "U_CD4_MY13_Hev_Tx" SG_ 947 TurnLghtRightOn_B_Stat 1;
BA_ "U_CD4_MY13_Phev_Tx" SG_ 947 TurnLghtRightOn_B_Stat 1;
BA_ "U_CD42_MY14_Diesel_Tx" SG_ 947 TurnLghtRightOn_B_Stat 1;
BA_ "U_CD42_MY14_Gas_Tx" SG_ 947 TurnLghtRightOn_B_Stat 1;
BA_ "U_P552_MY15_Gas_Tx" SG_ 947 TurnLghtRightOn_B_Stat 1;
BA_ "U_S550_MY15_Gas_Tx" SG_ 947 TurnLghtRightOn_B_Stat 1;
BA_ "U_C489_MY14_Gas_Tx" SG_ 947 TurnLghtRightOn_B_Stat 1;
BA_ "U_U502_MY15_Gas_Tx" SG_ 947 TurnLghtRightOn_B_Stat 1;
BA_ "U_UP375_MY15_Gas_Tx" SG_ 947 TurnLghtRightOn_B_Stat 1;
BA_ "U_UP375_MY15_Diesel_Tx" SG_ 947 TurnLghtRightOn_B_Stat 1;
BA_ "U_CD43_MY16_Gas_Tx" SG_ 947 TurnLghtRightOn_B_Stat 1;
BA_ "U_CD4_MY14_Diesel_Tx" SG_ 947 TurnLghtRightOn_B_Stat 1;
BA_ "U_CD4_MY14_Gas_Tx" SG_ 947 TurnLghtRightOn_B_Stat 1;
BA_ "U_CD4_MY14_Hev_Tx" SG_ 947 TurnLghtRightOn_B_Stat 1;
BA_ "U_CD4_MY14_Phev_Tx" SG_ 947 TurnLghtRightOn_B_Stat 1;
BA_ "CrossOver_InfoCAN" SG_ 947 TurnLghtLeftOn_B_Stat 1;
BA_ "CrossOver_LIN" SG_ 947 TurnLghtLeftOn_B_Stat 1;
BA_ "GenSigSendType" SG_ 947 TurnLghtLeftOn_B_Stat 3;
BA_ "U_CD4_MY13_Diesel_Tx" SG_ 947 TurnLghtLeftOn_B_Stat 1;
BA_ "U_CD4_MY13_Gas_Tx" SG_ 947 TurnLghtLeftOn_B_Stat 1;
BA_ "U_CD4_MY13_Hev_Tx" SG_ 947 TurnLghtLeftOn_B_Stat 1;
BA_ "U_CD4_MY13_Phev_Tx" SG_ 947 TurnLghtLeftOn_B_Stat 1;
BA_ "U_CD42_MY14_Diesel_Tx" SG_ 947 TurnLghtLeftOn_B_Stat 1;
BA_ "U_CD42_MY14_Gas_Tx" SG_ 947 TurnLghtLeftOn_B_Stat 1;
BA_ "U_P552_MY15_Gas_Tx" SG_ 947 TurnLghtLeftOn_B_Stat 1;
BA_ "U_S550_MY15_Gas_Tx" SG_ 947 TurnLghtLeftOn_B_Stat 1;
BA_ "U_C489_MY14_Gas_Tx" SG_ 947 TurnLghtLeftOn_B_Stat 1;
BA_ "U_U502_MY15_Gas_Tx" SG_ 947 TurnLghtLeftOn_B_Stat 1;
BA_ "U_UP375_MY15_Gas_Tx" SG_ 947 TurnLghtLeftOn_B_Stat 1;
BA_ "U_UP375_MY15_Diesel_Tx" SG_ 947 TurnLghtLeftOn_B_Stat 1;
BA_ "U_CD43_MY16_Gas_Tx" SG_ 947 TurnLghtLeftOn_B_Stat 1;
BA_ "U_CD4_MY14_Diesel_Tx" SG_ 947 TurnLghtLeftOn_B_Stat 1;
BA_ "U_CD4_MY14_Gas_Tx" SG_ 947 TurnLghtLeftOn_B_Stat 1;
BA_ "U_CD4_MY14_Hev_Tx" SG_ 947 TurnLghtLeftOn_B_Stat 1;
BA_ "U_CD4_MY14_Phev_Tx" SG_ 947 TurnLghtLeftOn_B_Stat 1;
BA_ "CrossOver_InfoCAN" SG_ 947 FogLghtRearOn_B_Stat 1;
BA_ "GenSigSendType" SG_ 947 FogLghtRearOn_B_Stat 3;
BA_ "U_CD4_MY13_Diesel_Tx" SG_ 947 FogLghtRearOn_B_Stat 1;
BA_ "U_CD4_MY13_Gas_Tx" SG_ 947 FogLghtRearOn_B_Stat 1;
BA_ "U_CD4_MY13_Hev_Tx" SG_ 947 FogLghtRearOn_B_Stat 1;
BA_ "U_CD4_MY13_Phev_Tx" SG_ 947 FogLghtRearOn_B_Stat 1;
BA_ "U_CD42_MY14_Diesel_Tx" SG_ 947 FogLghtRearOn_B_Stat 1;
BA_ "U_CD42_MY14_Gas_Tx" SG_ 947 FogLghtRearOn_B_Stat 1;
BA_ "U_P552_MY15_Gas_Tx" SG_ 947 FogLghtRearOn_B_Stat 1;
BA_ "U_S550_MY15_Gas_Tx" SG_ 947 FogLghtRearOn_B_Stat 1;
BA_ "U_C489_MY14_Gas_Tx" SG_ 947 FogLghtRearOn_B_Stat 1;
BA_ "U_U502_MY15_Gas_Tx" SG_ 947 FogLghtRearOn_B_Stat 1;
BA_ "U_UP375_MY15_Gas_Tx" SG_ 947 FogLghtRearOn_B_Stat 1;
BA_ "U_UP375_MY15_Diesel_Tx" SG_ 947 FogLghtRearOn_B_Stat 1;
BA_ "U_CD43_MY16_Gas_Tx" SG_ 947 FogLghtRearOn_B_Stat 1;
BA_ "U_CD4_MY14_Diesel_Tx" SG_ 947 FogLghtRearOn_B_Stat 1;
BA_ "U_CD4_MY14_Gas_Tx" SG_ 947 FogLghtRearOn_B_Stat 1;
BA_ "U_CD4_MY14_Hev_Tx" SG_ 947 FogLghtRearOn_B_Stat 1;
BA_ "U_CD4_MY14_Phev_Tx" SG_ 947 FogLghtRearOn_B_Stat 1;
BA_ "WakeupSignal" SG_ 947 Backlit_LED_Status 1;
BA_ "CrossOver_InfoCAN" SG_ 947 Backlit_LED_Status 1;
BA_ "GenSigSendType" SG_ 947 Backlit_LED_Status 3;
BA_ "U_CD4_MY13_Diesel_Rx" SG_ 947 Backlit_LED_Status 1;
BA_ "U_CD4_MY13_Gas_Rx" SG_ 947 Backlit_LED_Status 1;
BA_ "U_CD4_MY13_Hev_Rx" SG_ 947 Backlit_LED_Status 1;
BA_ "U_CD4_MY13_Phev_Rx" SG_ 947 Backlit_LED_Status 1;
BA_ "U_CD42_MY14_Diesel_Rx" SG_ 947 Backlit_LED_Status 1;
BA_ "U_CD42_MY14_Gas_Rx" SG_ 947 Backlit_LED_Status 1;
BA_ "U_P552_MY15_Gas_Rx" SG_ 947 Backlit_LED_Status 1;
BA_ "U_S550_MY15_Gas_Rx" SG_ 947 Backlit_LED_Status 1;
BA_ "U_C489_MY14_Gas_Rx" SG_ 947 Backlit_LED_Status 1;
BA_ "U_U502_MY15_Gas_Rx" SG_ 947 Backlit_LED_Status 1;
BA_ "U_B479_MY15_Gas_Rx" SG_ 947 Backlit_LED_Status 1;
BA_ "U_UP375_MY15_Gas_Rx" SG_ 947 Backlit_LED_Status 1;
BA_ "U_UP375_MY15_Diesel_Rx" SG_ 947 Backlit_LED_Status 1;
BA_ "U_CD4_MY13_Diesel_Tx" SG_ 947 Backlit_LED_Status 1;
BA_ "U_CD4_MY13_Gas_Tx" SG_ 947 Backlit_LED_Status 1;
BA_ "U_CD4_MY13_Hev_Tx" SG_ 947 Backlit_LED_Status 1;
BA_ "U_CD4_MY13_Phev_Tx" SG_ 947 Backlit_LED_Status 1;
BA_ "U_CD42_MY14_Diesel_Tx" SG_ 947 Backlit_LED_Status 1;
BA_ "U_CD42_MY14_Gas_Tx" SG_ 947 Backlit_LED_Status 1;
BA_ "U_P552_MY15_Gas_Tx" SG_ 947 Backlit_LED_Status 1;
BA_ "U_S550_MY15_Gas_Tx" SG_ 947 Backlit_LED_Status 1;
BA_ "U_C489_MY14_Gas_Tx" SG_ 947 Backlit_LED_Status 1;
BA_ "U_U502_MY15_Gas_Tx" SG_ 947 Backlit_LED_Status 1;
BA_ "U_UP375_MY15_Gas_Tx" SG_ 947 Backlit_LED_Status 1;
BA_ "U_UP375_MY15_Diesel_Tx" SG_ 947 Backlit_LED_Status 1;
BA_ "U_CD43_MY16_Gas_Tx" SG_ 947 Backlit_LED_Status 1;
BA_ "U_CD4_MY14_Diesel_Tx" SG_ 947 Backlit_LED_Status 1;
BA_ "U_CD4_MY14_Gas_Tx" SG_ 947 Backlit_LED_Status 1;
BA_ "U_CD4_MY14_Hev_Tx" SG_ 947 Backlit_LED_Status 1;
BA_ "U_CD4_MY14_Phev_Tx" SG_ 947 Backlit_LED_Status 1;
BA_ "WakeupSignal" SG_ 947 TurnLghtLeft_D_Rq 1;
BA_ "CrossOver_InfoCAN" SG_ 947 TurnLghtLeft_D_Rq 1;
BA_ "GenSigSendType" SG_ 947 TurnLghtLeft_D_Rq 3;
BA_ "U_CD4_MY13_Diesel_Rx" SG_ 947 TurnLghtLeft_D_Rq 1;
BA_ "U_CD4_MY13_Gas_Rx" SG_ 947 TurnLghtLeft_D_Rq 1;
BA_ "U_CD4_MY13_Hev_Rx" SG_ 947 TurnLghtLeft_D_Rq 1;
BA_ "U_CD4_MY13_Phev_Rx" SG_ 947 TurnLghtLeft_D_Rq 1;
BA_ "U_CD42_MY14_Diesel_Rx" SG_ 947 TurnLghtLeft_D_Rq 1;
BA_ "U_CD42_MY14_Gas_Rx" SG_ 947 TurnLghtLeft_D_Rq 1;
BA_ "U_P552_MY15_Gas_Rx" SG_ 947 TurnLghtLeft_D_Rq 1;
BA_ "U_S550_MY15_Gas_Rx" SG_ 947 TurnLghtLeft_D_Rq 1;
BA_ "U_C489_MY14_Gas_Rx" SG_ 947 TurnLghtLeft_D_Rq 1;
BA_ "U_U502_MY15_Gas_Rx" SG_ 947 TurnLghtLeft_D_Rq 1;
BA_ "U_B479_MY15_Gas_Rx" SG_ 947 TurnLghtLeft_D_Rq 1;
BA_ "U_UP375_MY15_Gas_Rx" SG_ 947 TurnLghtLeft_D_Rq 1;
BA_ "U_UP375_MY15_Diesel_Rx" SG_ 947 TurnLghtLeft_D_Rq 1;
BA_ "U_CD4_MY13_Diesel_Tx" SG_ 947 TurnLghtLeft_D_Rq 1;
BA_ "U_CD4_MY13_Gas_Tx" SG_ 947 TurnLghtLeft_D_Rq 1;
BA_ "U_CD4_MY13_Hev_Tx" SG_ 947 TurnLghtLeft_D_Rq 1;
BA_ "U_CD4_MY13_Phev_Tx" SG_ 947 TurnLghtLeft_D_Rq 1;
BA_ "U_CD42_MY14_Diesel_Tx" SG_ 947 TurnLghtLeft_D_Rq 1;
BA_ "U_CD42_MY14_Gas_Tx" SG_ 947 TurnLghtLeft_D_Rq 1;
BA_ "U_P552_MY15_Gas_Tx" SG_ 947 TurnLghtLeft_D_Rq 1;
BA_ "U_S550_MY15_Gas_Tx" SG_ 947 TurnLghtLeft_D_Rq 1;
BA_ "U_C489_MY14_Gas_Tx" SG_ 947 TurnLghtLeft_D_Rq 1;
BA_ "U_U502_MY15_Gas_Tx" SG_ 947 TurnLghtLeft_D_Rq 1;
BA_ "U_UP375_MY15_Gas_Tx" SG_ 947 TurnLghtLeft_D_Rq 1;
BA_ "U_UP375_MY15_Diesel_Tx" SG_ 947 TurnLghtLeft_D_Rq 1;
BA_ "U_CD43_MY16_Gas_Tx" SG_ 947 TurnLghtLeft_D_Rq 1;
BA_ "U_CD4_MY14_Diesel_Tx" SG_ 947 TurnLghtLeft_D_Rq 1;
BA_ "U_CD4_MY14_Gas_Tx" SG_ 947 TurnLghtLeft_D_Rq 1;
BA_ "U_CD4_MY14_Hev_Tx" SG_ 947 TurnLghtLeft_D_Rq 1;
BA_ "U_CD4_MY14_Phev_Tx" SG_ 947 TurnLghtLeft_D_Rq 1;
BA_ "CrossOver_InfoCAN" SG_ 947 FogLghtFrontOn_B_Stat 1;
BA_ "GenSigSendType" SG_ 947 FogLghtFrontOn_B_Stat 3;
BA_ "U_CD4_MY13_Diesel_Tx" SG_ 947 FogLghtFrontOn_B_Stat 1;
BA_ "U_CD4_MY13_Gas_Tx" SG_ 947 FogLghtFrontOn_B_Stat 1;
BA_ "U_CD4_MY13_Hev_Tx" SG_ 947 FogLghtFrontOn_B_Stat 1;
BA_ "U_CD4_MY13_Phev_Tx" SG_ 947 FogLghtFrontOn_B_Stat 1;
BA_ "U_CD42_MY14_Diesel_Tx" SG_ 947 FogLghtFrontOn_B_Stat 1;
BA_ "U_CD42_MY14_Gas_Tx" SG_ 947 FogLghtFrontOn_B_Stat 1;
BA_ "U_P552_MY15_Gas_Tx" SG_ 947 FogLghtFrontOn_B_Stat 1;
BA_ "U_S550_MY15_Gas_Tx" SG_ 947 FogLghtFrontOn_B_Stat 1;
BA_ "U_C489_MY14_Gas_Tx" SG_ 947 FogLghtFrontOn_B_Stat 1;
BA_ "U_U502_MY15_Gas_Tx" SG_ 947 FogLghtFrontOn_B_Stat 1;
BA_ "U_UP375_MY15_Gas_Tx" SG_ 947 FogLghtFrontOn_B_Stat 1;
BA_ "U_UP375_MY15_Diesel_Tx" SG_ 947 FogLghtFrontOn_B_Stat 1;
BA_ "U_CD43_MY16_Gas_Tx" SG_ 947 FogLghtFrontOn_B_Stat 1;
BA_ "U_CD4_MY14_Diesel_Tx" SG_ 947 FogLghtFrontOn_B_Stat 1;
BA_ "U_CD4_MY14_Gas_Tx" SG_ 947 FogLghtFrontOn_B_Stat 1;
BA_ "U_CD4_MY14_Hev_Tx" SG_ 947 FogLghtFrontOn_B_Stat 1;
BA_ "U_CD4_MY14_Phev_Tx" SG_ 947 FogLghtFrontOn_B_Stat 1;
BA_ "CrossOver_InfoCAN" SG_ 947 IgnKeyType_D_Actl 1;
BA_ "GenSigStartValue" SG_ 947 IgnKeyType_D_Actl 14;
BA_ "GenSigSendType" SG_ 947 IgnKeyType_D_Actl 3;
BA_ "U_U502_MY15_Gas_Rx" SG_ 947 IgnKeyType_D_Actl 1;
BA_ "U_CD43_MY16_Gas_Rx" SG_ 947 IgnKeyType_D_Actl 1;
BA_ "U_CD4_MY14_Gas_Rx" SG_ 947 IgnKeyType_D_Actl 1;
BA_ "U_UP375_MY15_Gas_Rx" SG_ 947 IgnKeyType_D_Actl 1;
BA_ "U_UP375_MY15_Diesel_Rx" SG_ 947 IgnKeyType_D_Actl 1;
BA_ "U_CD4_MY14_Diesel_Rx" SG_ 947 IgnKeyType_D_Actl 1;
BA_ "U_CD4_MY14_Hev_Rx" SG_ 947 IgnKeyType_D_Actl 1;
BA_ "U_CD4_MY14_Phev_Rx" SG_ 947 IgnKeyType_D_Actl 1;
BA_ "U_CD4_MY13_Diesel_Tx" SG_ 947 IgnKeyType_D_Actl 1;
BA_ "U_CD4_MY13_Gas_Tx" SG_ 947 IgnKeyType_D_Actl 1;
BA_ "U_CD4_MY13_Hev_Tx" SG_ 947 IgnKeyType_D_Actl 1;
BA_ "U_CD4_MY13_Phev_Tx" SG_ 947 IgnKeyType_D_Actl 1;
BA_ "U_CD42_MY14_Diesel_Tx" SG_ 947 IgnKeyType_D_Actl 1;
BA_ "U_CD42_MY14_Gas_Tx" SG_ 947 IgnKeyType_D_Actl 1;
BA_ "U_P552_MY15_Gas_Tx" SG_ 947 IgnKeyType_D_Actl 1;
BA_ "U_S550_MY15_Gas_Tx" SG_ 947 IgnKeyType_D_Actl 1;
BA_ "U_C489_MY14_Gas_Tx" SG_ 947 IgnKeyType_D_Actl 1;
BA_ "U_U502_MY15_Gas_Tx" SG_ 947 IgnKeyType_D_Actl 1;
BA_ "U_UP375_MY15_Gas_Tx" SG_ 947 IgnKeyType_D_Actl 1;
BA_ "U_UP375_MY15_Diesel_Tx" SG_ 947 IgnKeyType_D_Actl 1;
BA_ "U_CD43_MY16_Gas_Tx" SG_ 947 IgnKeyType_D_Actl 1;
BA_ "U_CD4_MY14_Diesel_Tx" SG_ 947 IgnKeyType_D_Actl 1;
BA_ "U_CD4_MY14_Gas_Tx" SG_ 947 IgnKeyType_D_Actl 1;
BA_ "U_CD4_MY14_Hev_Tx" SG_ 947 IgnKeyType_D_Actl 1;
BA_ "U_CD4_MY14_Phev_Tx" SG_ 947 IgnKeyType_D_Actl 1;
BA_ "WakeupSignal" SG_ 947 Parklamp_Status 1;
BA_ "CrossOver_InfoCAN" SG_ 947 Parklamp_Status 1;
BA_ "GenSigStartValue" SG_ 947 Parklamp_Status 1;
BA_ "GenSigSendType" SG_ 947 Parklamp_Status 3;
BA_ "U_CD4_MY13_Diesel_Rx" SG_ 947 Parklamp_Status 1;
BA_ "U_CD4_MY13_Gas_Rx" SG_ 947 Parklamp_Status 1;
BA_ "U_CD4_MY13_Hev_Rx" SG_ 947 Parklamp_Status 1;
BA_ "U_CD4_MY13_Phev_Rx" SG_ 947 Parklamp_Status 1;
BA_ "U_CD42_MY14_Diesel_Rx" SG_ 947 Parklamp_Status 1;
BA_ "U_CD42_MY14_Gas_Rx" SG_ 947 Parklamp_Status 1;
BA_ "U_P552_MY15_Gas_Rx" SG_ 947 Parklamp_Status 1;
BA_ "U_S550_MY15_Gas_Rx" SG_ 947 Parklamp_Status 1;
BA_ "U_C489_MY14_Gas_Rx" SG_ 947 Parklamp_Status 1;
BA_ "U_U502_MY15_Gas_Rx" SG_ 947 Parklamp_Status 1;
BA_ "U_B479_MY15_Gas_Rx" SG_ 947 Parklamp_Status 1;
BA_ "U_UP375_MY15_Gas_Rx" SG_ 947 Parklamp_Status 1;
BA_ "U_UP375_MY15_Diesel_Rx" SG_ 947 Parklamp_Status 1;
BA_ "U_CD4_MY13_Diesel_Tx" SG_ 947 Parklamp_Status 1;
BA_ "U_CD4_MY13_Gas_Tx" SG_ 947 Parklamp_Status 1;
BA_ "U_CD4_MY13_Hev_Tx" SG_ 947 Parklamp_Status 1;
BA_ "U_CD4_MY13_Phev_Tx" SG_ 947 Parklamp_Status 1;
BA_ "U_CD42_MY14_Diesel_Tx" SG_ 947 Parklamp_Status 1;
BA_ "U_CD42_MY14_Gas_Tx" SG_ 947 Parklamp_Status 1;
BA_ "U_P552_MY15_Gas_Tx" SG_ 947 Parklamp_Status 1;
BA_ "U_S550_MY15_Gas_Tx" SG_ 947 Parklamp_Status 1;
BA_ "U_C489_MY14_Gas_Tx" SG_ 947 Parklamp_Status 1;
BA_ "U_U502_MY15_Gas_Tx" SG_ 947 Parklamp_Status 1;
BA_ "U_UP375_MY15_Gas_Tx" SG_ 947 Parklamp_Status 1;
BA_ "U_UP375_MY15_Diesel_Tx" SG_ 947 Parklamp_Status 1;
BA_ "U_CD43_MY16_Gas_Tx" SG_ 947 Parklamp_Status 1;
BA_ "U_CD4_MY14_Diesel_Tx" SG_ 947 Parklamp_Status 1;
BA_ "U_CD4_MY14_Gas_Tx" SG_ 947 Parklamp_Status 1;
BA_ "U_CD4_MY14_Hev_Tx" SG_ 947 Parklamp_Status 1;
BA_ "U_CD4_MY14_Phev_Tx" SG_ 947 Parklamp_Status 1;
BA_ "WakeupSignal" SG_ 947 Litval 1;
BA_ "CrossOver_InfoCAN" SG_ 947 Litval 1;
BA_ "GenSigSendType" SG_ 947 Litval 3;
BA_ "U_CD4_MY13_Diesel_Rx" SG_ 947 Litval 1;
BA_ "U_CD4_MY13_Gas_Rx" SG_ 947 Litval 1;
BA_ "U_CD4_MY13_Hev_Rx" SG_ 947 Litval 1;
BA_ "U_CD4_MY13_Phev_Rx" SG_ 947 Litval 1;
BA_ "U_CD42_MY14_Diesel_Rx" SG_ 947 Litval 1;
BA_ "U_CD42_MY14_Gas_Rx" SG_ 947 Litval 1;
BA_ "U_P552_MY15_Gas_Rx" SG_ 947 Litval 1;
BA_ "U_S550_MY15_Gas_Rx" SG_ 947 Litval 1;
BA_ "U_C489_MY14_Gas_Rx" SG_ 947 Litval 1;
BA_ "U_U502_MY15_Gas_Rx" SG_ 947 Litval 1;
BA_ "U_B479_MY15_Gas_Rx" SG_ 947 Litval 1;
BA_ "U_UP375_MY15_Gas_Rx" SG_ 947 Litval 1;
BA_ "U_UP375_MY15_Diesel_Rx" SG_ 947 Litval 1;
BA_ "U_CD4_MY13_Diesel_Tx" SG_ 947 Litval 1;
BA_ "U_CD4_MY13_Gas_Tx" SG_ 947 Litval 1;
BA_ "U_CD4_MY13_Hev_Tx" SG_ 947 Litval 1;
BA_ "U_CD4_MY13_Phev_Tx" SG_ 947 Litval 1;
BA_ "U_CD42_MY14_Diesel_Tx" SG_ 947 Litval 1;
BA_ "U_CD42_MY14_Gas_Tx" SG_ 947 Litval 1;
BA_ "U_P552_MY15_Gas_Tx" SG_ 947 Litval 1;
BA_ "U_S550_MY15_Gas_Tx" SG_ 947 Litval 1;
BA_ "U_C489_MY14_Gas_Tx" SG_ 947 Litval 1;
BA_ "U_U502_MY15_Gas_Tx" SG_ 947 Litval 1;
BA_ "U_UP375_MY15_Gas_Tx" SG_ 947 Litval 1;
BA_ "U_UP375_MY15_Diesel_Tx" SG_ 947 Litval 1;
BA_ "U_CD43_MY16_Gas_Tx" SG_ 947 Litval 1;
BA_ "U_CD4_MY14_Diesel_Tx" SG_ 947 Litval 1;
BA_ "U_CD4_MY14_Gas_Tx" SG_ 947 Litval 1;
BA_ "U_CD4_MY14_Hev_Tx" SG_ 947 Litval 1;
BA_ "U_CD4_MY14_Phev_Tx" SG_ 947 Litval 1;
BA_ "WakeupSignal" SG_ 947 Key_In_Ignition_Stat 1;
BA_ "CrossOver_InfoCAN" SG_ 947 Key_In_Ignition_Stat 1;
BA_ "GenSigSendType" SG_ 947 Key_In_Ignition_Stat 3;
BA_ "U_CD4_MY13_Diesel_Rx" SG_ 947 Key_In_Ignition_Stat 1;
BA_ "U_CD4_MY13_Gas_Rx" SG_ 947 Key_In_Ignition_Stat 1;
BA_ "U_CD4_MY13_Hev_Rx" SG_ 947 Key_In_Ignition_Stat 1;
BA_ "U_CD4_MY13_Phev_Rx" SG_ 947 Key_In_Ignition_Stat 1;
BA_ "U_CD42_MY14_Diesel_Rx" SG_ 947 Key_In_Ignition_Stat 1;
BA_ "U_CD42_MY14_Gas_Rx" SG_ 947 Key_In_Ignition_Stat 1;
BA_ "U_P552_MY15_Gas_Rx" SG_ 947 Key_In_Ignition_Stat 1;
BA_ "U_S550_MY15_Gas_Rx" SG_ 947 Key_In_Ignition_Stat 1;
BA_ "U_C489_MY14_Gas_Rx" SG_ 947 Key_In_Ignition_Stat 1;
BA_ "U_U502_MY15_Gas_Rx" SG_ 947 Key_In_Ignition_Stat 1;
BA_ "U_B479_MY15_Gas_Rx" SG_ 947 Key_In_Ignition_Stat 1;
BA_ "U_UP375_MY15_Gas_Rx" SG_ 947 Key_In_Ignition_Stat 1;
BA_ "U_UP375_MY15_Diesel_Rx" SG_ 947 Key_In_Ignition_Stat 1;
BA_ "U_CD4_MY13_Diesel_Tx" SG_ 947 Key_In_Ignition_Stat 1;
BA_ "U_CD4_MY13_Gas_Tx" SG_ 947 Key_In_Ignition_Stat 1;
BA_ "U_CD4_MY13_Hev_Tx" SG_ 947 Key_In_Ignition_Stat 1;
BA_ "U_CD4_MY13_Phev_Tx" SG_ 947 Key_In_Ignition_Stat 1;
BA_ "U_CD42_MY14_Diesel_Tx" SG_ 947 Key_In_Ignition_Stat 1;
BA_ "U_CD42_MY14_Gas_Tx" SG_ 947 Key_In_Ignition_Stat 1;
BA_ "U_P552_MY15_Gas_Tx" SG_ 947 Key_In_Ignition_Stat 1;
BA_ "U_S550_MY15_Gas_Tx" SG_ 947 Key_In_Ignition_Stat 1;
BA_ "U_C489_MY14_Gas_Tx" SG_ 947 Key_In_Ignition_Stat 1;
BA_ "U_U502_MY15_Gas_Tx" SG_ 947 Key_In_Ignition_Stat 1;
BA_ "U_UP375_MY15_Gas_Tx" SG_ 947 Key_In_Ignition_Stat 1;
BA_ "U_UP375_MY15_Diesel_Tx" SG_ 947 Key_In_Ignition_Stat 1;
BA_ "U_CD43_MY16_Gas_Tx" SG_ 947 Key_In_Ignition_Stat 1;
BA_ "U_CD4_MY14_Diesel_Tx" SG_ 947 Key_In_Ignition_Stat 1;
BA_ "U_CD4_MY14_Gas_Tx" SG_ 947 Key_In_Ignition_Stat 1;
BA_ "U_CD4_MY14_Hev_Tx" SG_ 947 Key_In_Ignition_Stat 1;
BA_ "U_CD4_MY14_Phev_Tx" SG_ 947 Key_In_Ignition_Stat 1;
BA_ "U_U502_MY16_Gas_Rx" SG_ 947 Ignition_Status 1;
BA_ "U_B479_MY17_Gas_Rx" SG_ 947 Ignition_Status 1;
BA_ "U_CD4_MY17_Diesel_Rx" SG_ 947 Ignition_Status 1;
BA_ "U_CD4_MY17_Gas_Rx" SG_ 947 Ignition_Status 1;
BA_ "U_CD4_MY17_Hev_Rx" SG_ 947 Ignition_Status 1;
BA_ "U_CD4_MY17_Phev_Rx" SG_ 947 Ignition_Status 1;
BA_ "U_P558_MY17_Gas_Rx" SG_ 947 Ignition_Status 1;
BA_ "U_P558_MY17_Diesel_Rx" SG_ 947 Ignition_Status 1;
BA_ "U_V36X_MY16_5_Diesel_Rx" SG_ 947 Ignition_Status 1;
BA_ "U_C489_MY17_Gas_Rx" SG_ 947 Ignition_Status 1;
BA_ "U_CD42_MY16_Diesel_Rx" SG_ 947 Ignition_Status 1;
BA_ "U_CD42_MY16_Gas_Rx" SG_ 947 Ignition_Status 1;
BA_ "U_CD43_MY17_Gas_Rx" SG_ 947 Ignition_Status 1;
BA_ "U_P552_MY17_Gas_Rx" SG_ 947 Ignition_Status 1;
BA_ "U_B515_MCA_MY17_Diesel_Rx" SG_ 947 Ignition_Status 1;
BA_ "U_B515_MCA_MY17_Gas_Rx" SG_ 947 Ignition_Status 1;
BA_ "U_U55x_MY18_Gas_Rx" SG_ 947 Ignition_Status 1;
BA_ "U_CD42_MY15_Diesel_Tx" SG_ 947 Ignition_Status 1;
BA_ "U_CD42_MY15_Gas_Tx" SG_ 947 Ignition_Status 1;
BA_ "U_U502_MY16_Gas_Tx" SG_ 947 Ignition_Status 1;
BA_ "U_CD4_MY17_Diesel_Tx" SG_ 947 Ignition_Status 1;
BA_ "U_CD4_MY17_Gas_Tx" SG_ 947 Ignition_Status 1;
BA_ "U_CD4_MY17_Hev_Tx" SG_ 947 Ignition_Status 1;
BA_ "U_CD4_MY17_Phev_Tx" SG_ 947 Ignition_Status 1;
BA_ "U_P558_MY17_Gas_Tx" SG_ 947 Ignition_Status 1;
BA_ "U_P558_MY17_Diesel_Tx" SG_ 947 Ignition_Status 1;
BA_ "U_V36X_MY16_5_Diesel_Tx" SG_ 947 Ignition_Status 1;
BA_ "U_C489_MY17_Gas_Tx" SG_ 947 Ignition_Status 1;
BA_ "U_CD42_MY16_Diesel_Tx" SG_ 947 Ignition_Status 1;
BA_ "U_CD42_MY16_Gas_Tx" SG_ 947 Ignition_Status 1;
BA_ "U_CD43_MY17_Gas_Tx" SG_ 947 Ignition_Status 1;
BA_ "U_P552_MY17_Gas_Tx" SG_ 947 Ignition_Status 1;
BA_ "U_B515_MCA_MY17_Diesel_Tx" SG_ 947 Ignition_Status 1;
BA_ "U_B515_MCA_MY17_Gas_Tx" SG_ 947 Ignition_Status 1;
BA_ "U_U55x_MY18_Gas_Tx" SG_ 947 Ignition_Status 1;
BA_ "WakeupSignal" SG_ 947 Ignition_Status 1;
BA_ "CrossOver_InfoCAN" SG_ 947 Ignition_Status 1;
BA_ "CrossOver_LIN" SG_ 947 Ignition_Status 1;
BA_ "GenSigSendType" SG_ 947 Ignition_Status 3;
BA_ "U_CD4_MY13_Phev_Rx" SG_ 947 Ignition_Status 1;
BA_ "U_CD42_MY14_Diesel_Rx" SG_ 947 Ignition_Status 1;
BA_ "U_CD42_MY14_Gas_Rx" SG_ 947 Ignition_Status 1;
BA_ "U_S550_MY15_Gas_Rx" SG_ 947 Ignition_Status 1;
BA_ "U_U502_MY15_Gas_Rx" SG_ 947 Ignition_Status 1;
BA_ "U_B479_MY15_Gas_Rx" SG_ 947 Ignition_Status 1;
BA_ "U_UP375_MY15_Gas_Rx" SG_ 947 Ignition_Status 1;
BA_ "U_UP375_MY15_Diesel_Rx" SG_ 947 Ignition_Status 1;
BA_ "U_CD43_MY16_Gas_Rx" SG_ 947 Ignition_Status 1;
BA_ "U_CD4_MY14_Gas_Rx" SG_ 947 Ignition_Status 1;
BA_ "U_CD4_MY14_Diesel_Rx" SG_ 947 Ignition_Status 1;
BA_ "U_CD4_MY14_Hev_Rx" SG_ 947 Ignition_Status 1;
BA_ "U_CD4_MY14_Phev_Rx" SG_ 947 Ignition_Status 1;
BA_ "U_CD4_MY13_Diesel_Tx" SG_ 947 Ignition_Status 1;
BA_ "U_CD4_MY13_Gas_Tx" SG_ 947 Ignition_Status 1;
BA_ "U_CD4_MY13_Hev_Tx" SG_ 947 Ignition_Status 1;
BA_ "U_CD4_MY13_Phev_Tx" SG_ 947 Ignition_Status 1;
BA_ "U_CD42_MY14_Diesel_Tx" SG_ 947 Ignition_Status 1;
BA_ "U_CD42_MY14_Gas_Tx" SG_ 947 Ignition_Status 1;
BA_ "U_P552_MY15_Gas_Tx" SG_ 947 Ignition_Status 1;
BA_ "U_S550_MY15_Gas_Tx" SG_ 947 Ignition_Status 1;
BA_ "U_C489_MY14_Gas_Tx" SG_ 947 Ignition_Status 1;
BA_ "U_U502_MY15_Gas_Tx" SG_ 947 Ignition_Status 1;
BA_ "U_UP375_MY15_Gas_Tx" SG_ 947 Ignition_Status 1;
BA_ "U_UP375_MY15_Diesel_Tx" SG_ 947 Ignition_Status 1;
BA_ "U_CD43_MY16_Gas_Tx" SG_ 947 Ignition_Status 1;
BA_ "U_CD4_MY14_Diesel_Tx" SG_ 947 Ignition_Status 1;
BA_ "U_CD4_MY14_Gas_Tx" SG_ 947 Ignition_Status 1;
BA_ "U_CD4_MY14_Hev_Tx" SG_ 947 Ignition_Status 1;
BA_ "U_CD4_MY14_Phev_Tx" SG_ 947 Ignition_Status 1;
BA_ "GenSigTimeoutTime_TCM" SG_ 947 Ignition_Status 1500;
BA_ "WakeupSignal" SG_ 947 Dimming_Lvl 1;
BA_ "CrossOver_InfoCAN" SG_ 947 Dimming_Lvl 1;
BA_ "CrossOver_LIN" SG_ 947 Dimming_Lvl 1;
BA_ "GenSigStartValue" SG_ 947 Dimming_Lvl 12;
BA_ "GenSigSendType" SG_ 947 Dimming_Lvl 3;
BA_ "U_CD4_MY13_Diesel_Rx" SG_ 947 Dimming_Lvl 1;
BA_ "U_CD4_MY13_Gas_Rx" SG_ 947 Dimming_Lvl 1;
BA_ "U_CD4_MY13_Hev_Rx" SG_ 947 Dimming_Lvl 1;
BA_ "U_CD4_MY13_Phev_Rx" SG_ 947 Dimming_Lvl 1;
BA_ "U_CD42_MY14_Diesel_Rx" SG_ 947 Dimming_Lvl 1;
BA_ "U_CD42_MY14_Gas_Rx" SG_ 947 Dimming_Lvl 1;
BA_ "U_P552_MY15_Gas_Rx" SG_ 947 Dimming_Lvl 1;
BA_ "U_S550_MY15_Gas_Rx" SG_ 947 Dimming_Lvl 1;
BA_ "U_C489_MY14_Gas_Rx" SG_ 947 Dimming_Lvl 1;
BA_ "U_U502_MY15_Gas_Rx" SG_ 947 Dimming_Lvl 1;
BA_ "U_B479_MY15_Gas_Rx" SG_ 947 Dimming_Lvl 1;
BA_ "U_UP375_MY15_Gas_Rx" SG_ 947 Dimming_Lvl 1;
BA_ "U_UP375_MY15_Diesel_Rx" SG_ 947 Dimming_Lvl 1;
BA_ "U_CD4_MY13_Diesel_Tx" SG_ 947 Dimming_Lvl 1;
BA_ "U_CD4_MY13_Gas_Tx" SG_ 947 Dimming_Lvl 1;
BA_ "U_CD4_MY13_Hev_Tx" SG_ 947 Dimming_Lvl 1;
BA_ "U_CD4_MY13_Phev_Tx" SG_ 947 Dimming_Lvl 1;
BA_ "U_CD42_MY14_Diesel_Tx" SG_ 947 Dimming_Lvl 1;
BA_ "U_CD42_MY14_Gas_Tx" SG_ 947 Dimming_Lvl 1;
BA_ "U_P552_MY15_Gas_Tx" SG_ 947 Dimming_Lvl 1;
BA_ "U_S550_MY15_Gas_Tx" SG_ 947 Dimming_Lvl 1;
BA_ "U_C489_MY14_Gas_Tx" SG_ 947 Dimming_Lvl 1;
BA_ "U_U502_MY15_Gas_Tx" SG_ 947 Dimming_Lvl 1;
BA_ "U_UP375_MY15_Gas_Tx" SG_ 947 Dimming_Lvl 1;
BA_ "U_UP375_MY15_Diesel_Tx" SG_ 947 Dimming_Lvl 1;
BA_ "U_CD43_MY16_Gas_Tx" SG_ 947 Dimming_Lvl 1;
BA_ "U_CD4_MY14_Diesel_Tx" SG_ 947 Dimming_Lvl 1;
BA_ "U_CD4_MY14_Gas_Tx" SG_ 947 Dimming_Lvl 1;
BA_ "U_CD4_MY14_Hev_Tx" SG_ 947 Dimming_Lvl 1;
BA_ "U_CD4_MY14_Phev_Tx" SG_ 947 Dimming_Lvl 1;
BA_ "WakeupSignal" SG_ 947 Day_Night_Status 1;
BA_ "CrossOver_InfoCAN" SG_ 947 Day_Night_Status 1;
BA_ "GenSigSendType" SG_ 947 Day_Night_Status 3;
BA_ "U_CD4_MY13_Gas_Rx" SG_ 947 Day_Night_Status 1;
BA_ "U_CD42_MY14_Gas_Rx" SG_ 947 Day_Night_Status 1;
BA_ "U_P552_MY15_Gas_Rx" SG_ 947 Day_Night_Status 1;
BA_ "U_S550_MY15_Gas_Rx" SG_ 947 Day_Night_Status 1;
BA_ "U_C489_MY14_Gas_Rx" SG_ 947 Day_Night_Status 1;
BA_ "U_U502_MY15_Gas_Rx" SG_ 947 Day_Night_Status 1;
BA_ "U_B479_MY15_Gas_Rx" SG_ 947 Day_Night_Status 1;
BA_ "U_UP375_MY15_Gas_Rx" SG_ 947 Day_Night_Status 1;
BA_ "U_UP375_MY15_Diesel_Rx" SG_ 947 Day_Night_Status 1;
BA_ "U_CD43_MY16_Gas_Rx" SG_ 947 Day_Night_Status 1;
BA_ "U_CD4_MY14_Gas_Rx" SG_ 947 Day_Night_Status 1;
BA_ "U_CD4_MY13_Diesel_Tx" SG_ 947 Day_Night_Status 1;
BA_ "U_CD4_MY13_Gas_Tx" SG_ 947 Day_Night_Status 1;
BA_ "U_CD4_MY13_Hev_Tx" SG_ 947 Day_Night_Status 1;
BA_ "U_CD4_MY13_Phev_Tx" SG_ 947 Day_Night_Status 1;
BA_ "U_CD42_MY14_Diesel_Tx" SG_ 947 Day_Night_Status 1;
BA_ "U_CD42_MY14_Gas_Tx" SG_ 947 Day_Night_Status 1;
BA_ "U_P552_MY15_Gas_Tx" SG_ 947 Day_Night_Status 1;
BA_ "U_S550_MY15_Gas_Tx" SG_ 947 Day_Night_Status 1;
BA_ "U_C489_MY14_Gas_Tx" SG_ 947 Day_Night_Status 1;
BA_ "U_U502_MY15_Gas_Tx" SG_ 947 Day_Night_Status 1;
BA_ "U_UP375_MY15_Gas_Tx" SG_ 947 Day_Night_Status 1;
BA_ "U_UP375_MY15_Diesel_Tx" SG_ 947 Day_Night_Status 1;
BA_ "U_CD43_MY16_Gas_Tx" SG_ 947 Day_Night_Status 1;
BA_ "U_CD4_MY14_Diesel_Tx" SG_ 947 Day_Night_Status 1;
BA_ "U_CD4_MY14_Gas_Tx" SG_ 947 Day_Night_Status 1;
BA_ "U_CD4_MY14_Hev_Tx" SG_ 947 Day_Night_Status 1;
BA_ "U_CD4_MY14_Phev_Tx" SG_ 947 Day_Night_Status 1;
BA_ "U_CD42_MY15_Diesel_Rx" SG_ 947 Remote_Start_Status 1;
BA_ "U_CD42_MY15_Gas_Rx" SG_ 947 Remote_Start_Status 1;
BA_ "U_U502_MY16_Gas_Rx" SG_ 947 Remote_Start_Status 1;
BA_ "U_B479_MY17_Gas_Rx" SG_ 947 Remote_Start_Status 1;
BA_ "U_CD4_MY17_Diesel_Rx" SG_ 947 Remote_Start_Status 1;
BA_ "U_CD4_MY17_Gas_Rx" SG_ 947 Remote_Start_Status 1;
BA_ "U_CD4_MY17_Hev_Rx" SG_ 947 Remote_Start_Status 1;
BA_ "U_CD4_MY17_Phev_Rx" SG_ 947 Remote_Start_Status 1;
BA_ "U_P558_MY17_Gas_Rx" SG_ 947 Remote_Start_Status 1;
BA_ "U_P558_MY17_Diesel_Rx" SG_ 947 Remote_Start_Status 1;
BA_ "U_C489_MY17_Gas_Rx" SG_ 947 Remote_Start_Status 1;
BA_ "U_CD43_MY17_Gas_Rx" SG_ 947 Remote_Start_Status 1;
BA_ "U_U55x_MY18_Gas_Rx" SG_ 947 Remote_Start_Status 1;
BA_ "U_CD42_MY15_Diesel_Tx" SG_ 947 Remote_Start_Status 1;
BA_ "U_CD42_MY15_Gas_Tx" SG_ 947 Remote_Start_Status 1;
BA_ "U_U502_MY16_Gas_Tx" SG_ 947 Remote_Start_Status 1;
BA_ "U_CD4_MY17_Diesel_Tx" SG_ 947 Remote_Start_Status 1;
BA_ "U_CD4_MY17_Gas_Tx" SG_ 947 Remote_Start_Status 1;
BA_ "U_CD4_MY17_Hev_Tx" SG_ 947 Remote_Start_Status 1;
BA_ "U_CD4_MY17_Phev_Tx" SG_ 947 Remote_Start_Status 1;
BA_ "U_P558_MY17_Gas_Tx" SG_ 947 Remote_Start_Status 1;
BA_ "U_P558_MY17_Diesel_Tx" SG_ 947 Remote_Start_Status 1;
BA_ "U_V36X_MY16_5_Diesel_Tx" SG_ 947 Remote_Start_Status 1;
BA_ "U_C489_MY17_Gas_Tx" SG_ 947 Remote_Start_Status 1;
BA_ "U_CD42_MY16_Diesel_Tx" SG_ 947 Remote_Start_Status 1;
BA_ "U_CD42_MY16_Gas_Tx" SG_ 947 Remote_Start_Status 1;
BA_ "U_CD43_MY17_Gas_Tx" SG_ 947 Remote_Start_Status 1;
BA_ "U_P552_MY17_Gas_Tx" SG_ 947 Remote_Start_Status 1;
BA_ "U_B515_MCA_MY17_Diesel_Tx" SG_ 947 Remote_Start_Status 1;
BA_ "U_B515_MCA_MY17_Gas_Tx" SG_ 947 Remote_Start_Status 1;
BA_ "U_U55x_MY18_Gas_Tx" SG_ 947 Remote_Start_Status 1;
BA_ "WakeupSignal" SG_ 947 Remote_Start_Status 1;
BA_ "CrossOver_InfoCAN" SG_ 947 Remote_Start_Status 1;
BA_ "GenSigSendType" SG_ 947 Remote_Start_Status 3;
BA_ "U_CD4_MY13_Diesel_Rx" SG_ 947 Remote_Start_Status 1;
BA_ "U_CD4_MY13_Gas_Rx" SG_ 947 Remote_Start_Status 1;
BA_ "U_CD4_MY13_Hev_Rx" SG_ 947 Remote_Start_Status 1;
BA_ "U_CD4_MY13_Phev_Rx" SG_ 947 Remote_Start_Status 1;
BA_ "U_CD42_MY14_Diesel_Rx" SG_ 947 Remote_Start_Status 1;
BA_ "U_CD42_MY14_Gas_Rx" SG_ 947 Remote_Start_Status 1;
BA_ "U_P552_MY15_Gas_Rx" SG_ 947 Remote_Start_Status 1;
BA_ "U_S550_MY15_Gas_Rx" SG_ 947 Remote_Start_Status 1;
BA_ "U_C489_MY14_Gas_Rx" SG_ 947 Remote_Start_Status 1;
BA_ "U_U502_MY15_Gas_Rx" SG_ 947 Remote_Start_Status 1;
BA_ "U_B479_MY15_Gas_Rx" SG_ 947 Remote_Start_Status 1;
BA_ "U_UP375_MY15_Gas_Rx" SG_ 947 Remote_Start_Status 1;
BA_ "U_UP375_MY15_Diesel_Rx" SG_ 947 Remote_Start_Status 1;
BA_ "U_CD4_MY13_Diesel_Tx" SG_ 947 Remote_Start_Status 1;
BA_ "U_CD4_MY13_Gas_Tx" SG_ 947 Remote_Start_Status 1;
BA_ "U_CD4_MY13_Hev_Tx" SG_ 947 Remote_Start_Status 1;
BA_ "U_CD4_MY13_Phev_Tx" SG_ 947 Remote_Start_Status 1;
BA_ "U_CD42_MY14_Diesel_Tx" SG_ 947 Remote_Start_Status 1;
BA_ "U_CD42_MY14_Gas_Tx" SG_ 947 Remote_Start_Status 1;
BA_ "U_P552_MY15_Gas_Tx" SG_ 947 Remote_Start_Status 1;
BA_ "U_S550_MY15_Gas_Tx" SG_ 947 Remote_Start_Status 1;
BA_ "U_C489_MY14_Gas_Tx" SG_ 947 Remote_Start_Status 1;
BA_ "U_U502_MY15_Gas_Tx" SG_ 947 Remote_Start_Status 1;
BA_ "U_UP375_MY15_Gas_Tx" SG_ 947 Remote_Start_Status 1;
BA_ "U_UP375_MY15_Diesel_Tx" SG_ 947 Remote_Start_Status 1;
BA_ "U_CD43_MY16_Gas_Tx" SG_ 947 Remote_Start_Status 1;
BA_ "U_CD4_MY14_Diesel_Tx" SG_ 947 Remote_Start_Status 1;
BA_ "U_CD4_MY14_Gas_Tx" SG_ 947 Remote_Start_Status 1;
BA_ "U_CD4_MY14_Hev_Tx" SG_ 947 Remote_Start_Status 1;
BA_ "U_CD4_MY14_Phev_Tx" SG_ 947 Remote_Start_Status 1;
BA_ "WakeupSignal" SG_ 947 DrStatTgate_B_Actl 1;
BA_ "CrossOver_InfoCAN" SG_ 947 DrStatTgate_B_Actl 1;
BA_ "CrossOver_LIN" SG_ 947 DrStatTgate_B_Actl 1;
BA_ "GenSigSendType" SG_ 947 DrStatTgate_B_Actl 3;
BA_ "U_CD4_MY13_Diesel_Rx" SG_ 947 DrStatTgate_B_Actl 1;
BA_ "U_CD4_MY13_Gas_Rx" SG_ 947 DrStatTgate_B_Actl 1;
BA_ "U_CD4_MY13_Hev_Rx" SG_ 947 DrStatTgate_B_Actl 1;
BA_ "U_CD4_MY13_Phev_Rx" SG_ 947 DrStatTgate_B_Actl 1;
BA_ "U_CD42_MY14_Diesel_Rx" SG_ 947 DrStatTgate_B_Actl 1;
BA_ "U_CD42_MY14_Gas_Rx" SG_ 947 DrStatTgate_B_Actl 1;
BA_ "U_P552_MY15_Gas_Rx" SG_ 947 DrStatTgate_B_Actl 1;
BA_ "U_C489_MY14_Gas_Rx" SG_ 947 DrStatTgate_B_Actl 1;
BA_ "U_U502_MY15_Gas_Rx" SG_ 947 DrStatTgate_B_Actl 1;
BA_ "U_B479_MY15_Gas_Rx" SG_ 947 DrStatTgate_B_Actl 1;
BA_ "U_UP375_MY15_Gas_Rx" SG_ 947 DrStatTgate_B_Actl 1;
BA_ "U_UP375_MY15_Diesel_Rx" SG_ 947 DrStatTgate_B_Actl 1;
BA_ "U_CD43_MY16_Gas_Rx" SG_ 947 DrStatTgate_B_Actl 1;
BA_ "U_CD4_MY14_Diesel_Rx" SG_ 947 DrStatTgate_B_Actl 1;
BA_ "U_CD4_MY14_Gas_Rx" SG_ 947 DrStatTgate_B_Actl 1;
BA_ "U_CD4_MY14_Hev_Rx" SG_ 947 DrStatTgate_B_Actl 1;
BA_ "U_CD4_MY14_Phev_Rx" SG_ 947 DrStatTgate_B_Actl 1;
BA_ "U_CD4_MY13_Diesel_Tx" SG_ 947 DrStatTgate_B_Actl 1;
BA_ "U_CD4_MY13_Gas_Tx" SG_ 947 DrStatTgate_B_Actl 1;
BA_ "U_CD4_MY13_Hev_Tx" SG_ 947 DrStatTgate_B_Actl 1;
BA_ "U_CD4_MY13_Phev_Tx" SG_ 947 DrStatTgate_B_Actl 1;
BA_ "U_CD42_MY14_Diesel_Tx" SG_ 947 DrStatTgate_B_Actl 1;
BA_ "U_CD42_MY14_Gas_Tx" SG_ 947 DrStatTgate_B_Actl 1;
BA_ "U_P552_MY15_Gas_Tx" SG_ 947 DrStatTgate_B_Actl 1;
BA_ "U_S550_MY15_Gas_Tx" SG_ 947 DrStatTgate_B_Actl 1;
BA_ "U_C489_MY14_Gas_Tx" SG_ 947 DrStatTgate_B_Actl 1;
BA_ "U_U502_MY15_Gas_Tx" SG_ 947 DrStatTgate_B_Actl 1;
BA_ "U_UP375_MY15_Gas_Tx" SG_ 947 DrStatTgate_B_Actl 1;
BA_ "U_UP375_MY15_Diesel_Tx" SG_ 947 DrStatTgate_B_Actl 1;
BA_ "U_CD43_MY16_Gas_Tx" SG_ 947 DrStatTgate_B_Actl 1;
BA_ "U_CD4_MY14_Diesel_Tx" SG_ 947 DrStatTgate_B_Actl 1;
BA_ "U_CD4_MY14_Gas_Tx" SG_ 947 DrStatTgate_B_Actl 1;
BA_ "U_CD4_MY14_Hev_Tx" SG_ 947 DrStatTgate_B_Actl 1;
BA_ "U_CD4_MY14_Phev_Tx" SG_ 947 DrStatTgate_B_Actl 1;
BA_ "WakeupSignal" SG_ 947 DrStatRr_B_Actl 1;
BA_ "CrossOver_InfoCAN" SG_ 947 DrStatRr_B_Actl 1;
BA_ "GenSigSendType" SG_ 947 DrStatRr_B_Actl 3;
BA_ "U_CD4_MY13_Diesel_Rx" SG_ 947 DrStatRr_B_Actl 1;
BA_ "U_CD4_MY13_Gas_Rx" SG_ 947 DrStatRr_B_Actl 1;
BA_ "U_CD4_MY13_Hev_Rx" SG_ 947 DrStatRr_B_Actl 1;
BA_ "U_CD4_MY13_Phev_Rx" SG_ 947 DrStatRr_B_Actl 1;
BA_ "U_CD42_MY14_Diesel_Rx" SG_ 947 DrStatRr_B_Actl 1;
BA_ "U_CD42_MY14_Gas_Rx" SG_ 947 DrStatRr_B_Actl 1;
BA_ "U_P552_MY15_Gas_Rx" SG_ 947 DrStatRr_B_Actl 1;
BA_ "U_C489_MY14_Gas_Rx" SG_ 947 DrStatRr_B_Actl 1;
BA_ "U_U502_MY15_Gas_Rx" SG_ 947 DrStatRr_B_Actl 1;
BA_ "U_B479_MY15_Gas_Rx" SG_ 947 DrStatRr_B_Actl 1;
BA_ "U_UP375_MY15_Gas_Rx" SG_ 947 DrStatRr_B_Actl 1;
BA_ "U_UP375_MY15_Diesel_Rx" SG_ 947 DrStatRr_B_Actl 1;
BA_ "U_CD43_MY16_Gas_Rx" SG_ 947 DrStatRr_B_Actl 1;
BA_ "U_CD4_MY14_Diesel_Rx" SG_ 947 DrStatRr_B_Actl 1;
BA_ "U_CD4_MY14_Gas_Rx" SG_ 947 DrStatRr_B_Actl 1;
BA_ "U_CD4_MY14_Hev_Rx" SG_ 947 DrStatRr_B_Actl 1;
BA_ "U_CD4_MY14_Phev_Rx" SG_ 947 DrStatRr_B_Actl 1;
BA_ "U_CD4_MY13_Diesel_Tx" SG_ 947 DrStatRr_B_Actl 1;
BA_ "U_CD4_MY13_Gas_Tx" SG_ 947 DrStatRr_B_Actl 1;
BA_ "U_CD4_MY13_Hev_Tx" SG_ 947 DrStatRr_B_Actl 1;
BA_ "U_CD4_MY13_Phev_Tx" SG_ 947 DrStatRr_B_Actl 1;
BA_ "U_CD42_MY14_Diesel_Tx" SG_ 947 DrStatRr_B_Actl 1;
BA_ "U_CD42_MY14_Gas_Tx" SG_ 947 DrStatRr_B_Actl 1;
BA_ "U_P552_MY15_Gas_Tx" SG_ 947 DrStatRr_B_Actl 1;
BA_ "U_S550_MY15_Gas_Tx" SG_ 947 DrStatRr_B_Actl 1;
BA_ "U_C489_MY14_Gas_Tx" SG_ 947 DrStatRr_B_Actl 1;
BA_ "U_U502_MY15_Gas_Tx" SG_ 947 DrStatRr_B_Actl 1;
BA_ "U_UP375_MY15_Gas_Tx" SG_ 947 DrStatRr_B_Actl 1;
BA_ "U_UP375_MY15_Diesel_Tx" SG_ 947 DrStatRr_B_Actl 1;
BA_ "U_CD43_MY16_Gas_Tx" SG_ 947 DrStatRr_B_Actl 1;
BA_ "U_CD4_MY14_Diesel_Tx" SG_ 947 DrStatRr_B_Actl 1;
BA_ "U_CD4_MY14_Gas_Tx" SG_ 947 DrStatRr_B_Actl 1;
BA_ "U_CD4_MY14_Hev_Tx" SG_ 947 DrStatRr_B_Actl 1;
BA_ "U_CD4_MY14_Phev_Tx" SG_ 947 DrStatRr_B_Actl 1;
BA_ "WakeupSignal" SG_ 947 DrStatRl_B_Actl 1;
BA_ "CrossOver_InfoCAN" SG_ 947 DrStatRl_B_Actl 1;
BA_ "GenSigSendType" SG_ 947 DrStatRl_B_Actl 3;
BA_ "U_CD4_MY13_Diesel_Rx" SG_ 947 DrStatRl_B_Actl 1;
BA_ "U_CD4_MY13_Gas_Rx" SG_ 947 DrStatRl_B_Actl 1;
BA_ "U_CD4_MY13_Hev_Rx" SG_ 947 DrStatRl_B_Actl 1;
BA_ "U_CD4_MY13_Phev_Rx" SG_ 947 DrStatRl_B_Actl 1;
BA_ "U_CD42_MY14_Diesel_Rx" SG_ 947 DrStatRl_B_Actl 1;
BA_ "U_CD42_MY14_Gas_Rx" SG_ 947 DrStatRl_B_Actl 1;
BA_ "U_P552_MY15_Gas_Rx" SG_ 947 DrStatRl_B_Actl 1;
BA_ "U_C489_MY14_Gas_Rx" SG_ 947 DrStatRl_B_Actl 1;
BA_ "U_U502_MY15_Gas_Rx" SG_ 947 DrStatRl_B_Actl 1;
BA_ "U_B479_MY15_Gas_Rx" SG_ 947 DrStatRl_B_Actl 1;
BA_ "U_UP375_MY15_Gas_Rx" SG_ 947 DrStatRl_B_Actl 1;
BA_ "U_UP375_MY15_Diesel_Rx" SG_ 947 DrStatRl_B_Actl 1;
BA_ "U_CD43_MY16_Gas_Rx" SG_ 947 DrStatRl_B_Actl 1;
BA_ "U_CD4_MY14_Diesel_Rx" SG_ 947 DrStatRl_B_Actl 1;
BA_ "U_CD4_MY14_Gas_Rx" SG_ 947 DrStatRl_B_Actl 1;
BA_ "U_CD4_MY14_Hev_Rx" SG_ 947 DrStatRl_B_Actl 1;
BA_ "U_CD4_MY14_Phev_Rx" SG_ 947 DrStatRl_B_Actl 1;
BA_ "U_CD4_MY13_Diesel_Tx" SG_ 947 DrStatRl_B_Actl 1;
BA_ "U_CD4_MY13_Gas_Tx" SG_ 947 DrStatRl_B_Actl 1;
BA_ "U_CD4_MY13_Hev_Tx" SG_ 947 DrStatRl_B_Actl 1;
BA_ "U_CD4_MY13_Phev_Tx" SG_ 947 DrStatRl_B_Actl 1;
BA_ "U_CD42_MY14_Diesel_Tx" SG_ 947 DrStatRl_B_Actl 1;
BA_ "U_CD42_MY14_Gas_Tx" SG_ 947 DrStatRl_B_Actl 1;
BA_ "U_P552_MY15_Gas_Tx" SG_ 947 DrStatRl_B_Actl 1;
BA_ "U_S550_MY15_Gas_Tx" SG_ 947 DrStatRl_B_Actl 1;
BA_ "U_C489_MY14_Gas_Tx" SG_ 947 DrStatRl_B_Actl 1;
BA_ "U_U502_MY15_Gas_Tx" SG_ 947 DrStatRl_B_Actl 1;
BA_ "U_UP375_MY15_Gas_Tx" SG_ 947 DrStatRl_B_Actl 1;
BA_ "U_UP375_MY15_Diesel_Tx" SG_ 947 DrStatRl_B_Actl 1;
BA_ "U_CD43_MY16_Gas_Tx" SG_ 947 DrStatRl_B_Actl 1;
BA_ "U_CD4_MY14_Diesel_Tx" SG_ 947 DrStatRl_B_Actl 1;
BA_ "U_CD4_MY14_Gas_Tx" SG_ 947 DrStatRl_B_Actl 1;
BA_ "U_CD4_MY14_Hev_Tx" SG_ 947 DrStatRl_B_Actl 1;
BA_ "U_CD4_MY14_Phev_Tx" SG_ 947 DrStatRl_B_Actl 1;
BA_ "WakeupSignal" SG_ 947 DrStatPsngr_B_Actl 1;
BA_ "CrossOver_InfoCAN" SG_ 947 DrStatPsngr_B_Actl 1;
BA_ "GenSigSendType" SG_ 947 DrStatPsngr_B_Actl 3;
BA_ "U_CD4_MY13_Diesel_Rx" SG_ 947 DrStatPsngr_B_Actl 1;
BA_ "U_CD4_MY13_Gas_Rx" SG_ 947 DrStatPsngr_B_Actl 1;
BA_ "U_CD4_MY13_Hev_Rx" SG_ 947 DrStatPsngr_B_Actl 1;
BA_ "U_CD4_MY13_Phev_Rx" SG_ 947 DrStatPsngr_B_Actl 1;
BA_ "U_CD42_MY14_Diesel_Rx" SG_ 947 DrStatPsngr_B_Actl 1;
BA_ "U_CD42_MY14_Gas_Rx" SG_ 947 DrStatPsngr_B_Actl 1;
BA_ "U_P552_MY15_Gas_Rx" SG_ 947 DrStatPsngr_B_Actl 1;
BA_ "U_C489_MY14_Gas_Rx" SG_ 947 DrStatPsngr_B_Actl 1;
BA_ "U_U502_MY15_Gas_Rx" SG_ 947 DrStatPsngr_B_Actl 1;
BA_ "U_B479_MY15_Gas_Rx" SG_ 947 DrStatPsngr_B_Actl 1;
BA_ "U_UP375_MY15_Gas_Rx" SG_ 947 DrStatPsngr_B_Actl 1;
BA_ "U_UP375_MY15_Diesel_Rx" SG_ 947 DrStatPsngr_B_Actl 1;
BA_ "U_CD43_MY16_Gas_Rx" SG_ 947 DrStatPsngr_B_Actl 1;
BA_ "U_CD4_MY14_Diesel_Rx" SG_ 947 DrStatPsngr_B_Actl 1;
BA_ "U_CD4_MY14_Gas_Rx" SG_ 947 DrStatPsngr_B_Actl 1;
BA_ "U_CD4_MY14_Hev_Rx" SG_ 947 DrStatPsngr_B_Actl 1;
BA_ "U_CD4_MY14_Phev_Rx" SG_ 947 DrStatPsngr_B_Actl 1;
BA_ "U_CD4_MY13_Diesel_Tx" SG_ 947 DrStatPsngr_B_Actl 1;
BA_ "U_CD4_MY13_Gas_Tx" SG_ 947 DrStatPsngr_B_Actl 1;
BA_ "U_CD4_MY13_Hev_Tx" SG_ 947 DrStatPsngr_B_Actl 1;
BA_ "U_CD4_MY13_Phev_Tx" SG_ 947 DrStatPsngr_B_Actl 1;
BA_ "U_CD42_MY14_Diesel_Tx" SG_ 947 DrStatPsngr_B_Actl 1;
BA_ "U_CD42_MY14_Gas_Tx" SG_ 947 DrStatPsngr_B_Actl 1;
BA_ "U_P552_MY15_Gas_Tx" SG_ 947 DrStatPsngr_B_Actl 1;
BA_ "U_S550_MY15_Gas_Tx" SG_ 947 DrStatPsngr_B_Actl 1;
BA_ "U_C489_MY14_Gas_Tx" SG_ 947 DrStatPsngr_B_Actl 1;
BA_ "U_U502_MY15_Gas_Tx" SG_ 947 DrStatPsngr_B_Actl 1;
BA_ "U_UP375_MY15_Gas_Tx" SG_ 947 DrStatPsngr_B_Actl 1;
BA_ "U_UP375_MY15_Diesel_Tx" SG_ 947 DrStatPsngr_B_Actl 1;
BA_ "U_CD43_MY16_Gas_Tx" SG_ 947 DrStatPsngr_B_Actl 1;
BA_ "U_CD4_MY14_Diesel_Tx" SG_ 947 DrStatPsngr_B_Actl 1;
BA_ "U_CD4_MY14_Gas_Tx" SG_ 947 DrStatPsngr_B_Actl 1;
BA_ "U_CD4_MY14_Hev_Tx" SG_ 947 DrStatPsngr_B_Actl 1;
BA_ "U_CD4_MY14_Phev_Tx" SG_ 947 DrStatPsngr_B_Actl 1;
BA_ "WakeupSignal" SG_ 947 DrStatInnrTgate_B_Actl 1;
BA_ "CrossOver_InfoCAN" SG_ 947 DrStatInnrTgate_B_Actl 1;
BA_ "CrossOver_LIN" SG_ 947 DrStatInnrTgate_B_Actl 1;
BA_ "GenSigSendType" SG_ 947 DrStatInnrTgate_B_Actl 3;
BA_ "U_CD4_MY13_Diesel_Rx" SG_ 947 DrStatInnrTgate_B_Actl 1;
BA_ "U_CD4_MY13_Gas_Rx" SG_ 947 DrStatInnrTgate_B_Actl 1;
BA_ "U_CD4_MY13_Hev_Rx" SG_ 947 DrStatInnrTgate_B_Actl 1;
BA_ "U_CD4_MY13_Phev_Rx" SG_ 947 DrStatInnrTgate_B_Actl 1;
BA_ "U_CD42_MY14_Diesel_Rx" SG_ 947 DrStatInnrTgate_B_Actl 1;
BA_ "U_CD42_MY14_Gas_Rx" SG_ 947 DrStatInnrTgate_B_Actl 1;
BA_ "U_P552_MY15_Gas_Rx" SG_ 947 DrStatInnrTgate_B_Actl 1;
BA_ "U_C489_MY14_Gas_Rx" SG_ 947 DrStatInnrTgate_B_Actl 1;
BA_ "U_U502_MY15_Gas_Rx" SG_ 947 DrStatInnrTgate_B_Actl 1;
BA_ "U_B479_MY15_Gas_Rx" SG_ 947 DrStatInnrTgate_B_Actl 1;
BA_ "U_UP375_MY15_Gas_Rx" SG_ 947 DrStatInnrTgate_B_Actl 1;
BA_ "U_UP375_MY15_Diesel_Rx" SG_ 947 DrStatInnrTgate_B_Actl 1;
BA_ "U_CD43_MY16_Gas_Rx" SG_ 947 DrStatInnrTgate_B_Actl 1;
BA_ "U_CD4_MY14_Diesel_Rx" SG_ 947 DrStatInnrTgate_B_Actl 1;
BA_ "U_CD4_MY14_Gas_Rx" SG_ 947 DrStatInnrTgate_B_Actl 1;
BA_ "U_CD4_MY14_Hev_Rx" SG_ 947 DrStatInnrTgate_B_Actl 1;
BA_ "U_CD4_MY14_Phev_Rx" SG_ 947 DrStatInnrTgate_B_Actl 1;
BA_ "U_CD4_MY13_Diesel_Tx" SG_ 947 DrStatInnrTgate_B_Actl 1;
BA_ "U_CD4_MY13_Gas_Tx" SG_ 947 DrStatInnrTgate_B_Actl 1;
BA_ "U_CD4_MY13_Hev_Tx" SG_ 947 DrStatInnrTgate_B_Actl 1;
BA_ "U_CD4_MY13_Phev_Tx" SG_ 947 DrStatInnrTgate_B_Actl 1;
BA_ "U_CD42_MY14_Diesel_Tx" SG_ 947 DrStatInnrTgate_B_Actl 1;
BA_ "U_CD42_MY14_Gas_Tx" SG_ 947 DrStatInnrTgate_B_Actl 1;
BA_ "U_P552_MY15_Gas_Tx" SG_ 947 DrStatInnrTgate_B_Actl 1;
BA_ "U_S550_MY15_Gas_Tx" SG_ 947 DrStatInnrTgate_B_Actl 1;
BA_ "U_C489_MY14_Gas_Tx" SG_ 947 DrStatInnrTgate_B_Actl 1;
BA_ "U_U502_MY15_Gas_Tx" SG_ 947 DrStatInnrTgate_B_Actl 1;
BA_ "U_UP375_MY15_Gas_Tx" SG_ 947 DrStatInnrTgate_B_Actl 1;
BA_ "U_UP375_MY15_Diesel_Tx" SG_ 947 DrStatInnrTgate_B_Actl 1;
BA_ "U_CD43_MY16_Gas_Tx" SG_ 947 DrStatInnrTgate_B_Actl 1;
BA_ "U_CD4_MY14_Diesel_Tx" SG_ 947 DrStatInnrTgate_B_Actl 1;
BA_ "U_CD4_MY14_Gas_Tx" SG_ 947 DrStatInnrTgate_B_Actl 1;
BA_ "U_CD4_MY14_Hev_Tx" SG_ 947 DrStatInnrTgate_B_Actl 1;
BA_ "U_CD4_MY14_Phev_Tx" SG_ 947 DrStatInnrTgate_B_Actl 1;
BA_ "WakeupSignal" SG_ 947 DrStatHood_B_Actl 1;
BA_ "CrossOver_InfoCAN" SG_ 947 DrStatHood_B_Actl 1;
BA_ "GenSigSendType" SG_ 947 DrStatHood_B_Actl 3;
BA_ "U_CD4_MY13_Diesel_Rx" SG_ 947 DrStatHood_B_Actl 1;
BA_ "U_CD4_MY13_Gas_Rx" SG_ 947 DrStatHood_B_Actl 1;
BA_ "U_CD4_MY13_Hev_Rx" SG_ 947 DrStatHood_B_Actl 1;
BA_ "U_CD4_MY13_Phev_Rx" SG_ 947 DrStatHood_B_Actl 1;
BA_ "U_CD42_MY14_Diesel_Rx" SG_ 947 DrStatHood_B_Actl 1;
BA_ "U_CD42_MY14_Gas_Rx" SG_ 947 DrStatHood_B_Actl 1;
BA_ "U_P552_MY15_Gas_Rx" SG_ 947 DrStatHood_B_Actl 1;
BA_ "U_S550_MY15_Gas_Rx" SG_ 947 DrStatHood_B_Actl 1;
BA_ "U_C489_MY14_Gas_Rx" SG_ 947 DrStatHood_B_Actl 1;
BA_ "U_U502_MY15_Gas_Rx" SG_ 947 DrStatHood_B_Actl 1;
BA_ "U_B479_MY15_Gas_Rx" SG_ 947 DrStatHood_B_Actl 1;
BA_ "U_UP375_MY15_Gas_Rx" SG_ 947 DrStatHood_B_Actl 1;
BA_ "U_UP375_MY15_Diesel_Rx" SG_ 947 DrStatHood_B_Actl 1;
BA_ "U_CD4_MY13_Diesel_Tx" SG_ 947 DrStatHood_B_Actl 1;
BA_ "U_CD4_MY13_Gas_Tx" SG_ 947 DrStatHood_B_Actl 1;
BA_ "U_CD4_MY13_Hev_Tx" SG_ 947 DrStatHood_B_Actl 1;
BA_ "U_CD4_MY13_Phev_Tx" SG_ 947 DrStatHood_B_Actl 1;
BA_ "U_CD42_MY14_Diesel_Tx" SG_ 947 DrStatHood_B_Actl 1;
BA_ "U_CD42_MY14_Gas_Tx" SG_ 947 DrStatHood_B_Actl 1;
BA_ "U_P552_MY15_Gas_Tx" SG_ 947 DrStatHood_B_Actl 1;
BA_ "U_S550_MY15_Gas_Tx" SG_ 947 DrStatHood_B_Actl 1;
BA_ "U_C489_MY14_Gas_Tx" SG_ 947 DrStatHood_B_Actl 1;
BA_ "U_U502_MY15_Gas_Tx" SG_ 947 DrStatHood_B_Actl 1;
BA_ "U_UP375_MY15_Gas_Tx" SG_ 947 DrStatHood_B_Actl 1;
BA_ "U_UP375_MY15_Diesel_Tx" SG_ 947 DrStatHood_B_Actl 1;
BA_ "U_CD43_MY16_Gas_Tx" SG_ 947 DrStatHood_B_Actl 1;
BA_ "U_CD4_MY14_Diesel_Tx" SG_ 947 DrStatHood_B_Actl 1;
BA_ "U_CD4_MY14_Gas_Tx" SG_ 947 DrStatHood_B_Actl 1;
BA_ "U_CD4_MY14_Hev_Tx" SG_ 947 DrStatHood_B_Actl 1;
BA_ "U_CD4_MY14_Phev_Tx" SG_ 947 DrStatHood_B_Actl 1;
BA_ "WakeupSignal" SG_ 947 DrStatDrv_B_Actl 1;
BA_ "CrossOver_InfoCAN" SG_ 947 DrStatDrv_B_Actl 1;
BA_ "GenSigSendType" SG_ 947 DrStatDrv_B_Actl 3;
BA_ "U_CD4_MY13_Diesel_Rx" SG_ 947 DrStatDrv_B_Actl 1;
BA_ "U_CD4_MY13_Gas_Rx" SG_ 947 DrStatDrv_B_Actl 1;
BA_ "U_CD4_MY13_Hev_Rx" SG_ 947 DrStatDrv_B_Actl 1;
BA_ "U_CD4_MY13_Phev_Rx" SG_ 947 DrStatDrv_B_Actl 1;
BA_ "U_CD42_MY14_Diesel_Rx" SG_ 947 DrStatDrv_B_Actl 1;
BA_ "U_CD42_MY14_Gas_Rx" SG_ 947 DrStatDrv_B_Actl 1;
BA_ "U_P552_MY15_Gas_Rx" SG_ 947 DrStatDrv_B_Actl 1;
BA_ "U_C489_MY14_Gas_Rx" SG_ 947 DrStatDrv_B_Actl 1;
BA_ "U_U502_MY15_Gas_Rx" SG_ 947 DrStatDrv_B_Actl 1;
BA_ "U_B479_MY15_Gas_Rx" SG_ 947 DrStatDrv_B_Actl 1;
BA_ "U_UP375_MY15_Gas_Rx" SG_ 947 DrStatDrv_B_Actl 1;
BA_ "U_UP375_MY15_Diesel_Rx" SG_ 947 DrStatDrv_B_Actl 1;
BA_ "U_CD43_MY16_Gas_Rx" SG_ 947 DrStatDrv_B_Actl 1;
BA_ "U_CD4_MY14_Gas_Rx" SG_ 947 DrStatDrv_B_Actl 1;
BA_ "U_CD4_MY14_Diesel_Rx" SG_ 947 DrStatDrv_B_Actl 1;
BA_ "U_CD4_MY14_Hev_Rx" SG_ 947 DrStatDrv_B_Actl 1;
BA_ "U_CD4_MY14_Phev_Rx" SG_ 947 DrStatDrv_B_Actl 1;
BA_ "U_CD4_MY13_Diesel_Tx" SG_ 947 DrStatDrv_B_Actl 1;
BA_ "U_CD4_MY13_Gas_Tx" SG_ 947 DrStatDrv_B_Actl 1;
BA_ "U_CD4_MY13_Hev_Tx" SG_ 947 DrStatDrv_B_Actl 1;
BA_ "U_CD4_MY13_Phev_Tx" SG_ 947 DrStatDrv_B_Actl 1;
BA_ "U_CD42_MY14_Diesel_Tx" SG_ 947 DrStatDrv_B_Actl 1;
BA_ "U_CD42_MY14_Gas_Tx" SG_ 947 DrStatDrv_B_Actl 1;
BA_ "U_P552_MY15_Gas_Tx" SG_ 947 DrStatDrv_B_Actl 1;
BA_ "U_S550_MY15_Gas_Tx" SG_ 947 DrStatDrv_B_Actl 1;
BA_ "U_C489_MY14_Gas_Tx" SG_ 947 DrStatDrv_B_Actl 1;
BA_ "U_U502_MY15_Gas_Tx" SG_ 947 DrStatDrv_B_Actl 1;
BA_ "U_UP375_MY15_Gas_Tx" SG_ 947 DrStatDrv_B_Actl 1;
BA_ "U_UP375_MY15_Diesel_Tx" SG_ 947 DrStatDrv_B_Actl 1;
BA_ "U_CD43_MY16_Gas_Tx" SG_ 947 DrStatDrv_B_Actl 1;
BA_ "U_CD4_MY14_Diesel_Tx" SG_ 947 DrStatDrv_B_Actl 1;
BA_ "U_CD4_MY14_Gas_Tx" SG_ 947 DrStatDrv_B_Actl 1;
BA_ "U_CD4_MY14_Hev_Tx" SG_ 947 DrStatDrv_B_Actl 1;
BA_ "U_CD4_MY14_Phev_Tx" SG_ 947 DrStatDrv_B_Actl 1;
BA_ "WakeupSignal" SG_ 947 PrkBrkActv_B_Actl 1;
BA_ "CrossOver_InfoCAN" SG_ 947 PrkBrkActv_B_Actl 1;
BA_ "ContentDependant" SG_ 947 PrkBrkActv_B_Actl 1;
BA_ "GenSigSendType" SG_ 947 PrkBrkActv_B_Actl 3;
BA_ "U_CD4_MY13_Diesel_Rx" SG_ 947 PrkBrkActv_B_Actl 1;
BA_ "U_CD4_MY13_Gas_Rx" SG_ 947 PrkBrkActv_B_Actl 1;
BA_ "U_CD4_MY13_Hev_Rx" SG_ 947 PrkBrkActv_B_Actl 1;
BA_ "U_CD4_MY13_Phev_Rx" SG_ 947 PrkBrkActv_B_Actl 1;
BA_ "U_CD42_MY14_Diesel_Rx" SG_ 947 PrkBrkActv_B_Actl 1;
BA_ "U_P552_MY15_Gas_Rx" SG_ 947 PrkBrkActv_B_Actl 1;
BA_ "U_S550_MY15_Gas_Rx" SG_ 947 PrkBrkActv_B_Actl 1;
BA_ "U_C489_MY14_Gas_Rx" SG_ 947 PrkBrkActv_B_Actl 1;
BA_ "U_CD43_MY16_Gas_Rx" SG_ 947 PrkBrkActv_B_Actl 1;
BA_ "U_CD4_MY14_Gas_Rx" SG_ 947 PrkBrkActv_B_Actl 1;
BA_ "U_CD42_MY14_Gas_Rx" SG_ 947 PrkBrkActv_B_Actl 1;
BA_ "U_U502_MY15_Gas_Rx" SG_ 947 PrkBrkActv_B_Actl 1;
BA_ "U_B479_MY15_Gas_Rx" SG_ 947 PrkBrkActv_B_Actl 1;
BA_ "U_UP375_MY15_Gas_Rx" SG_ 947 PrkBrkActv_B_Actl 1;
BA_ "U_UP375_MY15_Diesel_Rx" SG_ 947 PrkBrkActv_B_Actl 1;
BA_ "U_CD4_MY14_Diesel_Rx" SG_ 947 PrkBrkActv_B_Actl 1;
BA_ "U_CD4_MY14_Hev_Rx" SG_ 947 PrkBrkActv_B_Actl 1;
BA_ "U_CD4_MY14_Phev_Rx" SG_ 947 PrkBrkActv_B_Actl 1;
BA_ "U_CD4_MY13_Diesel_Tx" SG_ 947 PrkBrkActv_B_Actl 1;
BA_ "U_CD4_MY13_Gas_Tx" SG_ 947 PrkBrkActv_B_Actl 1;
BA_ "U_CD4_MY13_Hev_Tx" SG_ 947 PrkBrkActv_B_Actl 1;
BA_ "U_CD4_MY13_Phev_Tx" SG_ 947 PrkBrkActv_B_Actl 1;
BA_ "U_CD42_MY14_Diesel_Tx" SG_ 947 PrkBrkActv_B_Actl 1;
BA_ "U_CD42_MY14_Gas_Tx" SG_ 947 PrkBrkActv_B_Actl 1;
BA_ "U_P552_MY15_Gas_Tx" SG_ 947 PrkBrkActv_B_Actl 1;
BA_ "U_S550_MY15_Gas_Tx" SG_ 947 PrkBrkActv_B_Actl 1;
BA_ "U_C489_MY14_Gas_Tx" SG_ 947 PrkBrkActv_B_Actl 1;
BA_ "U_U502_MY15_Gas_Tx" SG_ 947 PrkBrkActv_B_Actl 1;
BA_ "U_UP375_MY15_Gas_Tx" SG_ 947 PrkBrkActv_B_Actl 1;
BA_ "U_UP375_MY15_Diesel_Tx" SG_ 947 PrkBrkActv_B_Actl 1;
BA_ "U_CD43_MY16_Gas_Tx" SG_ 947 PrkBrkActv_B_Actl 1;
BA_ "U_CD4_MY14_Diesel_Tx" SG_ 947 PrkBrkActv_B_Actl 1;
BA_ "U_CD4_MY14_Gas_Tx" SG_ 947 PrkBrkActv_B_Actl 1;
BA_ "U_CD4_MY14_Hev_Tx" SG_ 947 PrkBrkActv_B_Actl 1;
BA_ "U_CD4_MY14_Phev_Tx" SG_ 947 PrkBrkActv_B_Actl 1;
BA_ "GenSigTimeoutTime_TCM" SG_ 947 PrkBrkActv_B_Actl 1500;
BA_ "CrossOver_InfoCAN" SG_ 947 LifeCycMde_D_Actl 1;
BA_ "GenSigSendType" SG_ 947 LifeCycMde_D_Actl 3;
BA_ "U_CD4_MY13_Diesel_Rx" SG_ 947 LifeCycMde_D_Actl 1;
BA_ "U_CD4_MY13_Gas_Rx" SG_ 947 LifeCycMde_D_Actl 1;
BA_ "U_CD4_MY13_Hev_Rx" SG_ 947 LifeCycMde_D_Actl 1;
BA_ "U_CD4_MY13_Phev_Rx" SG_ 947 LifeCycMde_D_Actl 1;
BA_ "U_CD42_MY14_Diesel_Rx" SG_ 947 LifeCycMde_D_Actl 1;
BA_ "U_CD42_MY14_Gas_Rx" SG_ 947 LifeCycMde_D_Actl 1;
BA_ "U_P552_MY15_Gas_Rx" SG_ 947 LifeCycMde_D_Actl 1;
BA_ "U_S550_MY15_Gas_Rx" SG_ 947 LifeCycMde_D_Actl 1;
BA_ "U_C489_MY14_Gas_Rx" SG_ 947 LifeCycMde_D_Actl 1;
BA_ "U_U502_MY15_Gas_Rx" SG_ 947 LifeCycMde_D_Actl 1;
BA_ "U_CD43_MY16_Gas_Rx" SG_ 947 LifeCycMde_D_Actl 1;
BA_ "U_CD4_MY14_Gas_Rx" SG_ 947 LifeCycMde_D_Actl 1;
BA_ "U_UP375_MY15_Gas_Rx" SG_ 947 LifeCycMde_D_Actl 1;
BA_ "U_UP375_MY15_Diesel_Rx" SG_ 947 LifeCycMde_D_Actl 1;
BA_ "U_CD4_MY14_Diesel_Rx" SG_ 947 LifeCycMde_D_Actl 1;
BA_ "U_CD4_MY14_Hev_Rx" SG_ 947 LifeCycMde_D_Actl 1;
BA_ "U_CD4_MY14_Phev_Rx" SG_ 947 LifeCycMde_D_Actl 1;
BA_ "U_CD4_MY13_Diesel_Tx" SG_ 947 LifeCycMde_D_Actl 1;
BA_ "U_CD4_MY13_Gas_Tx" SG_ 947 LifeCycMde_D_Actl 1;
BA_ "U_CD4_MY13_Hev_Tx" SG_ 947 LifeCycMde_D_Actl 1;
BA_ "U_CD4_MY13_Phev_Tx" SG_ 947 LifeCycMde_D_Actl 1;
BA_ "U_CD42_MY14_Diesel_Tx" SG_ 947 LifeCycMde_D_Actl 1;
BA_ "U_CD42_MY14_Gas_Tx" SG_ 947 LifeCycMde_D_Actl 1;
BA_ "U_P552_MY15_Gas_Tx" SG_ 947 LifeCycMde_D_Actl 1;
BA_ "U_S550_MY15_Gas_Tx" SG_ 947 LifeCycMde_D_Actl 1;
BA_ "U_C489_MY14_Gas_Tx" SG_ 947 LifeCycMde_D_Actl 1;
BA_ "U_U502_MY15_Gas_Tx" SG_ 947 LifeCycMde_D_Actl 1;
BA_ "U_UP375_MY15_Gas_Tx" SG_ 947 LifeCycMde_D_Actl 1;
BA_ "U_UP375_MY15_Diesel_Tx" SG_ 947 LifeCycMde_D_Actl 1;
BA_ "U_CD43_MY16_Gas_Tx" SG_ 947 LifeCycMde_D_Actl 1;
BA_ "U_CD4_MY14_Diesel_Tx" SG_ 947 LifeCycMde_D_Actl 1;
BA_ "U_CD4_MY14_Gas_Tx" SG_ 947 LifeCycMde_D_Actl 1;
BA_ "U_CD4_MY14_Hev_Tx" SG_ 947 LifeCycMde_D_Actl 1;
BA_ "U_CD4_MY14_Phev_Tx" SG_ 947 LifeCycMde_D_Actl 1;
BA_ "GenSigTimeoutTime_TCM" SG_ 947 LifeCycMde_D_Actl 1500;
BA_ "WakeupSignal" SG_ 947 Delay_Accy 1;
BA_ "CrossOver_InfoCAN" SG_ 947 Delay_Accy 1;
BA_ "GenSigSendType" SG_ 947 Delay_Accy 3;
BA_ "U_CD4_MY13_Diesel_Rx" SG_ 947 Delay_Accy 1;
BA_ "U_CD4_MY13_Gas_Rx" SG_ 947 Delay_Accy 1;
BA_ "U_CD4_MY13_Hev_Rx" SG_ 947 Delay_Accy 1;
BA_ "U_CD4_MY13_Phev_Rx" SG_ 947 Delay_Accy 1;
BA_ "U_CD42_MY14_Diesel_Rx" SG_ 947 Delay_Accy 1;
BA_ "U_CD42_MY14_Gas_Rx" SG_ 947 Delay_Accy 1;
BA_ "U_P552_MY15_Gas_Rx" SG_ 947 Delay_Accy 1;
BA_ "U_S550_MY15_Gas_Rx" SG_ 947 Delay_Accy 1;
BA_ "U_C489_MY14_Gas_Rx" SG_ 947 Delay_Accy 1;
BA_ "U_U502_MY15_Gas_Rx" SG_ 947 Delay_Accy 1;
BA_ "U_B479_MY15_Gas_Rx" SG_ 947 Delay_Accy 1;
BA_ "U_UP375_MY15_Gas_Rx" SG_ 947 Delay_Accy 1;
BA_ "U_UP375_MY15_Diesel_Rx" SG_ 947 Delay_Accy 1;
BA_ "U_CD4_MY13_Diesel_Tx" SG_ 947 Delay_Accy 1;
BA_ "U_CD4_MY13_Gas_Tx" SG_ 947 Delay_Accy 1;
BA_ "U_CD4_MY13_Hev_Tx" SG_ 947 Delay_Accy 1;
BA_ "U_CD4_MY13_Phev_Tx" SG_ 947 Delay_Accy 1;
BA_ "U_CD42_MY14_Diesel_Tx" SG_ 947 Delay_Accy 1;
BA_ "U_CD42_MY14_Gas_Tx" SG_ 947 Delay_Accy 1;
BA_ "U_P552_MY15_Gas_Tx" SG_ 947 Delay_Accy 1;
BA_ "U_S550_MY15_Gas_Tx" SG_ 947 Delay_Accy 1;
BA_ "U_C489_MY14_Gas_Tx" SG_ 947 Delay_Accy 1;
BA_ "U_U502_MY15_Gas_Tx" SG_ 947 Delay_Accy 1;
BA_ "U_UP375_MY15_Gas_Tx" SG_ 947 Delay_Accy 1;
BA_ "U_UP375_MY15_Diesel_Tx" SG_ 947 Delay_Accy 1;
BA_ "U_CD43_MY16_Gas_Tx" SG_ 947 Delay_Accy 1;
BA_ "U_CD4_MY14_Diesel_Tx" SG_ 947 Delay_Accy 1;
BA_ "U_CD4_MY14_Gas_Tx" SG_ 947 Delay_Accy 1;
BA_ "U_CD4_MY14_Hev_Tx" SG_ 947 Delay_Accy 1;
BA_ "U_CD4_MY14_Phev_Tx" SG_ 947 Delay_Accy 1;
BA_ "WakeupSignal" SG_ 947 CrashEvnt_D_Stat 1;
BA_ "CrossOver_InfoCAN" SG_ 947 CrashEvnt_D_Stat 1;
BA_ "GenSigStartValue" SG_ 947 CrashEvnt_D_Stat 3;
BA_ "GenSigSendType" SG_ 947 CrashEvnt_D_Stat 3;
BA_ "U_CD4_MY13_Diesel_Rx" SG_ 947 CrashEvnt_D_Stat 1;
BA_ "U_CD4_MY13_Gas_Rx" SG_ 947 CrashEvnt_D_Stat 1;
BA_ "U_CD4_MY13_Hev_Rx" SG_ 947 CrashEvnt_D_Stat 1;
BA_ "U_CD4_MY13_Phev_Rx" SG_ 947 CrashEvnt_D_Stat 1;
BA_ "U_CD42_MY14_Diesel_Rx" SG_ 947 CrashEvnt_D_Stat 1;
BA_ "U_CD42_MY14_Gas_Rx" SG_ 947 CrashEvnt_D_Stat 1;
BA_ "U_P552_MY15_Gas_Rx" SG_ 947 CrashEvnt_D_Stat 1;
BA_ "U_S550_MY15_Gas_Rx" SG_ 947 CrashEvnt_D_Stat 1;
BA_ "U_C489_MY14_Gas_Rx" SG_ 947 CrashEvnt_D_Stat 1;
BA_ "U_U502_MY15_Gas_Rx" SG_ 947 CrashEvnt_D_Stat 1;
BA_ "U_B479_MY15_Gas_Rx" SG_ 947 CrashEvnt_D_Stat 1;
BA_ "U_UP375_MY15_Gas_Rx" SG_ 947 CrashEvnt_D_Stat 1;
BA_ "U_UP375_MY15_Diesel_Rx" SG_ 947 CrashEvnt_D_Stat 1;
BA_ "U_CD4_MY13_Diesel_Tx" SG_ 947 CrashEvnt_D_Stat 1;
BA_ "U_CD4_MY13_Gas_Tx" SG_ 947 CrashEvnt_D_Stat 1;
BA_ "U_CD4_MY13_Hev_Tx" SG_ 947 CrashEvnt_D_Stat 1;
BA_ "U_CD4_MY13_Phev_Tx" SG_ 947 CrashEvnt_D_Stat 1;
BA_ "U_CD42_MY14_Diesel_Tx" SG_ 947 CrashEvnt_D_Stat 1;
BA_ "U_CD42_MY14_Gas_Tx" SG_ 947 CrashEvnt_D_Stat 1;
BA_ "U_P552_MY15_Gas_Tx" SG_ 947 CrashEvnt_D_Stat 1;
BA_ "U_S550_MY15_Gas_Tx" SG_ 947 CrashEvnt_D_Stat 1;
BA_ "U_C489_MY14_Gas_Tx" SG_ 947 CrashEvnt_D_Stat 1;
BA_ "U_U502_MY15_Gas_Tx" SG_ 947 CrashEvnt_D_Stat 1;
BA_ "U_UP375_MY15_Gas_Tx" SG_ 947 CrashEvnt_D_Stat 1;
BA_ "U_UP375_MY15_Diesel_Tx" SG_ 947 CrashEvnt_D_Stat 1;
BA_ "U_CD43_MY16_Gas_Tx" SG_ 947 CrashEvnt_D_Stat 1;
BA_ "U_CD4_MY14_Diesel_Tx" SG_ 947 CrashEvnt_D_Stat 1;
BA_ "U_CD4_MY14_Gas_Tx" SG_ 947 CrashEvnt_D_Stat 1;
BA_ "U_CD4_MY14_Hev_Tx" SG_ 947 CrashEvnt_D_Stat 1;
BA_ "U_CD4_MY14_Phev_Tx" SG_ 947 CrashEvnt_D_Stat 1;
BA_ "CrossOver_InfoCAN" SG_ 947 FuelPmpInhbt_B_Stat 1;
BA_ "GenSigSendType" SG_ 947 FuelPmpInhbt_B_Stat 3;
BA_ "U_CD4_MY13_Diesel_Tx" SG_ 947 FuelPmpInhbt_B_Stat 1;
BA_ "U_CD4_MY13_Gas_Tx" SG_ 947 FuelPmpInhbt_B_Stat 1;
BA_ "U_CD4_MY13_Hev_Tx" SG_ 947 FuelPmpInhbt_B_Stat 1;
BA_ "U_CD4_MY13_Phev_Tx" SG_ 947 FuelPmpInhbt_B_Stat 1;
BA_ "U_CD42_MY14_Diesel_Tx" SG_ 947 FuelPmpInhbt_B_Stat 1;
BA_ "U_CD42_MY14_Gas_Tx" SG_ 947 FuelPmpInhbt_B_Stat 1;
BA_ "U_P552_MY15_Gas_Tx" SG_ 947 FuelPmpInhbt_B_Stat 1;
BA_ "U_S550_MY15_Gas_Tx" SG_ 947 FuelPmpInhbt_B_Stat 1;
BA_ "U_C489_MY14_Gas_Tx" SG_ 947 FuelPmpInhbt_B_Stat 1;
BA_ "U_U502_MY15_Gas_Tx" SG_ 947 FuelPmpInhbt_B_Stat 1;
BA_ "U_UP375_MY15_Gas_Tx" SG_ 947 FuelPmpInhbt_B_Stat 1;
BA_ "U_UP375_MY15_Diesel_Tx" SG_ 947 FuelPmpInhbt_B_Stat 1;
BA_ "U_CD43_MY16_Gas_Tx" SG_ 947 FuelPmpInhbt_B_Stat 1;
BA_ "U_CD4_MY14_Diesel_Tx" SG_ 947 FuelPmpInhbt_B_Stat 1;
BA_ "U_CD4_MY14_Gas_Tx" SG_ 947 FuelPmpInhbt_B_Stat 1;
BA_ "U_CD4_MY14_Hev_Tx" SG_ 947 FuelPmpInhbt_B_Stat 1;
BA_ "U_CD4_MY14_Phev_Tx" SG_ 947 FuelPmpInhbt_B_Stat 1;
BA_ "CrossOver_InfoCAN" SG_ 947 BodySrvcRqd_B_Rq 1;
BA_ "GenSigSendType" SG_ 947 BodySrvcRqd_B_Rq 3;
BA_ "U_CD4_MY13_Diesel_Tx" SG_ 947 BodySrvcRqd_B_Rq 1;
BA_ "U_CD4_MY13_Gas_Tx" SG_ 947 BodySrvcRqd_B_Rq 1;
BA_ "U_CD4_MY13_Hev_Tx" SG_ 947 BodySrvcRqd_B_Rq 1;
BA_ "U_CD4_MY13_Phev_Tx" SG_ 947 BodySrvcRqd_B_Rq 1;
BA_ "U_CD42_MY14_Diesel_Tx" SG_ 947 BodySrvcRqd_B_Rq 1;
BA_ "U_CD42_MY14_Gas_Tx" SG_ 947 BodySrvcRqd_B_Rq 1;
BA_ "U_P552_MY15_Gas_Tx" SG_ 947 BodySrvcRqd_B_Rq 1;
BA_ "U_S550_MY15_Gas_Tx" SG_ 947 BodySrvcRqd_B_Rq 1;
BA_ "U_C489_MY14_Gas_Tx" SG_ 947 BodySrvcRqd_B_Rq 1;
BA_ "U_U502_MY15_Gas_Tx" SG_ 947 BodySrvcRqd_B_Rq 1;
BA_ "U_UP375_MY15_Gas_Tx" SG_ 947 BodySrvcRqd_B_Rq 1;
BA_ "U_UP375_MY15_Diesel_Tx" SG_ 947 BodySrvcRqd_B_Rq 1;
BA_ "U_CD43_MY16_Gas_Tx" SG_ 947 BodySrvcRqd_B_Rq 1;
BA_ "U_CD4_MY14_Diesel_Tx" SG_ 947 BodySrvcRqd_B_Rq 1;
BA_ "U_CD4_MY14_Gas_Tx" SG_ 947 BodySrvcRqd_B_Rq 1;
BA_ "U_CD4_MY14_Hev_Tx" SG_ 947 BodySrvcRqd_B_Rq 1;
BA_ "U_CD4_MY14_Phev_Tx" SG_ 947 BodySrvcRqd_B_Rq 1;
BA_ "CrossOver_InfoCAN" SG_ 986 LightAmbIntsty_No_Rq 1;
BA_ "U_CD4_MY13_Diesel_Rx" SG_ 986 LightAmbIntsty_No_Rq 1;
BA_ "U_CD4_MY13_Gas_Rx" SG_ 986 LightAmbIntsty_No_Rq 1;
BA_ "U_CD4_MY13_Hev_Rx" SG_ 986 LightAmbIntsty_No_Rq 1;
BA_ "U_CD4_MY13_Phev_Rx" SG_ 986 LightAmbIntsty_No_Rq 1;
BA_ "U_CD42_MY14_Diesel_Rx" SG_ 986 LightAmbIntsty_No_Rq 1;
BA_ "U_CD42_MY14_Gas_Rx" SG_ 986 LightAmbIntsty_No_Rq 1;
BA_ "U_P552_MY15_Gas_Rx" SG_ 986 LightAmbIntsty_No_Rq 1;
BA_ "U_S550_MY15_Gas_Rx" SG_ 986 LightAmbIntsty_No_Rq 1;
BA_ "U_C489_MY14_Gas_Rx" SG_ 986 LightAmbIntsty_No_Rq 1;
BA_ "U_U502_MY15_Gas_Rx" SG_ 986 LightAmbIntsty_No_Rq 1;
BA_ "U_UP375_MY15_Gas_Rx" SG_ 986 LightAmbIntsty_No_Rq 1;
BA_ "U_UP375_MY15_Diesel_Rx" SG_ 986 LightAmbIntsty_No_Rq 1;
BA_ "U_CD43_MY16_Gas_Rx" SG_ 986 LightAmbIntsty_No_Rq 1;
BA_ "U_CD4_MY14_Diesel_Rx" SG_ 986 LightAmbIntsty_No_Rq 1;
BA_ "U_CD4_MY14_Gas_Rx" SG_ 986 LightAmbIntsty_No_Rq 1;
BA_ "U_CD4_MY14_Hev_Rx" SG_ 986 LightAmbIntsty_No_Rq 1;
BA_ "U_CD4_MY14_Phev_Rx" SG_ 986 LightAmbIntsty_No_Rq 1;
BA_ "CrossOver_InfoCAN" SG_ 986 LightAmbColor_No_Rq 1;
BA_ "U_CD4_MY13_Diesel_Rx" SG_ 986 LightAmbColor_No_Rq 1;
BA_ "U_CD4_MY13_Gas_Rx" SG_ 986 LightAmbColor_No_Rq 1;
BA_ "U_CD4_MY13_Hev_Rx" SG_ 986 LightAmbColor_No_Rq 1;
BA_ "U_CD4_MY13_Phev_Rx" SG_ 986 LightAmbColor_No_Rq 1;
BA_ "U_CD42_MY14_Diesel_Rx" SG_ 986 LightAmbColor_No_Rq 1;
BA_ "U_CD42_MY14_Gas_Rx" SG_ 986 LightAmbColor_No_Rq 1;
BA_ "U_P552_MY15_Gas_Rx" SG_ 986 LightAmbColor_No_Rq 1;
BA_ "U_S550_MY15_Gas_Rx" SG_ 986 LightAmbColor_No_Rq 1;
BA_ "U_C489_MY14_Gas_Rx" SG_ 986 LightAmbColor_No_Rq 1;
BA_ "U_U502_MY15_Gas_Rx" SG_ 986 LightAmbColor_No_Rq 1;
BA_ "U_UP375_MY15_Gas_Rx" SG_ 986 LightAmbColor_No_Rq 1;
BA_ "U_UP375_MY15_Diesel_Rx" SG_ 986 LightAmbColor_No_Rq 1;
BA_ "U_CD43_MY16_Gas_Rx" SG_ 986 LightAmbColor_No_Rq 1;
BA_ "U_CD4_MY14_Diesel_Rx" SG_ 986 LightAmbColor_No_Rq 1;
BA_ "U_CD4_MY14_Gas_Rx" SG_ 986 LightAmbColor_No_Rq 1;
BA_ "U_CD4_MY14_Hev_Rx" SG_ 986 LightAmbColor_No_Rq 1;
BA_ "U_CD4_MY14_Phev_Rx" SG_ 986 LightAmbColor_No_Rq 1;
BA_ "CrossOver_InfoCAN" SG_ 995 FobAssocChime_B_Rq 1;
BA_ "GenSigSendType" SG_ 995 FobAssocChime_B_Rq 3;
BA_ "U_CD4_MY13_Diesel_Tx" SG_ 995 FobAssocChime_B_Rq 1;
BA_ "U_CD4_MY13_Gas_Tx" SG_ 995 FobAssocChime_B_Rq 1;
BA_ "U_CD4_MY13_Hev_Tx" SG_ 995 FobAssocChime_B_Rq 1;
BA_ "U_CD4_MY13_Phev_Tx" SG_ 995 FobAssocChime_B_Rq 1;
BA_ "U_CD42_MY14_Diesel_Tx" SG_ 995 FobAssocChime_B_Rq 1;
BA_ "U_CD42_MY14_Gas_Tx" SG_ 995 FobAssocChime_B_Rq 1;
BA_ "U_P552_MY15_Gas_Tx" SG_ 995 FobAssocChime_B_Rq 1;
BA_ "U_S550_MY15_Gas_Tx" SG_ 995 FobAssocChime_B_Rq 1;
BA_ "U_C489_MY14_Gas_Tx" SG_ 995 FobAssocChime_B_Rq 1;
BA_ "U_U502_MY15_Gas_Tx" SG_ 995 FobAssocChime_B_Rq 1;
BA_ "U_UP375_MY15_Gas_Tx" SG_ 995 FobAssocChime_B_Rq 1;
BA_ "U_UP375_MY15_Diesel_Tx" SG_ 995 FobAssocChime_B_Rq 1;
BA_ "U_CD43_MY16_Gas_Tx" SG_ 995 FobAssocChime_B_Rq 1;
BA_ "U_CD4_MY14_Diesel_Tx" SG_ 995 FobAssocChime_B_Rq 1;
BA_ "U_CD4_MY14_Gas_Tx" SG_ 995 FobAssocChime_B_Rq 1;
BA_ "U_CD4_MY14_Hev_Tx" SG_ 995 FobAssocChime_B_Rq 1;
BA_ "U_CD4_MY14_Phev_Tx" SG_ 995 FobAssocChime_B_Rq 1;
BA_ "CrossOver_InfoCAN" SG_ 995 LightAmbIntsty_No_Actl 1;
BA_ "GenSigSendType" SG_ 995 LightAmbIntsty_No_Actl 3;
BA_ "U_CD4_MY13_Diesel_Rx" SG_ 995 LightAmbIntsty_No_Actl 1;
BA_ "U_CD4_MY13_Gas_Rx" SG_ 995 LightAmbIntsty_No_Actl 1;
BA_ "U_CD4_MY13_Hev_Rx" SG_ 995 LightAmbIntsty_No_Actl 1;
BA_ "U_CD4_MY13_Phev_Rx" SG_ 995 LightAmbIntsty_No_Actl 1;
BA_ "U_CD42_MY14_Diesel_Rx" SG_ 995 LightAmbIntsty_No_Actl 1;
BA_ "U_CD42_MY14_Gas_Rx" SG_ 995 LightAmbIntsty_No_Actl 1;
BA_ "U_P552_MY15_Gas_Rx" SG_ 995 LightAmbIntsty_No_Actl 1;
BA_ "U_S550_MY15_Gas_Rx" SG_ 995 LightAmbIntsty_No_Actl 1;
BA_ "U_C489_MY14_Gas_Rx" SG_ 995 LightAmbIntsty_No_Actl 1;
BA_ "U_U502_MY15_Gas_Rx" SG_ 995 LightAmbIntsty_No_Actl 1;
BA_ "U_CD43_MY16_Gas_Rx" SG_ 995 LightAmbIntsty_No_Actl 1;
BA_ "U_CD4_MY14_Diesel_Rx" SG_ 995 LightAmbIntsty_No_Actl 1;
BA_ "U_CD4_MY14_Gas_Rx" SG_ 995 LightAmbIntsty_No_Actl 1;
BA_ "U_CD4_MY14_Hev_Rx" SG_ 995 LightAmbIntsty_No_Actl 1;
BA_ "U_CD4_MY14_Phev_Rx" SG_ 995 LightAmbIntsty_No_Actl 1;
BA_ "U_CD4_MY13_Diesel_Tx" SG_ 995 LightAmbIntsty_No_Actl 1;
BA_ "U_CD4_MY13_Gas_Tx" SG_ 995 LightAmbIntsty_No_Actl 1;
BA_ "U_CD4_MY13_Hev_Tx" SG_ 995 LightAmbIntsty_No_Actl 1;
BA_ "U_CD4_MY13_Phev_Tx" SG_ 995 LightAmbIntsty_No_Actl 1;
BA_ "U_CD42_MY14_Diesel_Tx" SG_ 995 LightAmbIntsty_No_Actl 1;
BA_ "U_CD42_MY14_Gas_Tx" SG_ 995 LightAmbIntsty_No_Actl 1;
BA_ "U_P552_MY15_Gas_Tx" SG_ 995 LightAmbIntsty_No_Actl 1;
BA_ "U_S550_MY15_Gas_Tx" SG_ 995 LightAmbIntsty_No_Actl 1;
BA_ "U_C489_MY14_Gas_Tx" SG_ 995 LightAmbIntsty_No_Actl 1;
BA_ "U_U502_MY15_Gas_Tx" SG_ 995 LightAmbIntsty_No_Actl 1;
BA_ "U_UP375_MY15_Gas_Tx" SG_ 995 LightAmbIntsty_No_Actl 1;
BA_ "U_UP375_MY15_Diesel_Tx" SG_ 995 LightAmbIntsty_No_Actl 1;
BA_ "U_CD43_MY16_Gas_Tx" SG_ 995 LightAmbIntsty_No_Actl 1;
BA_ "U_CD4_MY14_Diesel_Tx" SG_ 995 LightAmbIntsty_No_Actl 1;
BA_ "U_CD4_MY14_Gas_Tx" SG_ 995 LightAmbIntsty_No_Actl 1;
BA_ "U_CD4_MY14_Hev_Tx" SG_ 995 LightAmbIntsty_No_Actl 1;
BA_ "U_CD4_MY14_Phev_Tx" SG_ 995 LightAmbIntsty_No_Actl 1;
BA_ "CrossOver_InfoCAN" SG_ 995 PersIndexBcm_D_Actl 1;
BA_ "GenSigStartValue" SG_ 995 PersIndexBcm_D_Actl 4;
BA_ "GenSigSendType" SG_ 995 PersIndexBcm_D_Actl 3;
BA_ "U_CD4_MY13_Diesel_Rx" SG_ 995 PersIndexBcm_D_Actl 1;
BA_ "U_CD4_MY13_Gas_Rx" SG_ 995 PersIndexBcm_D_Actl 1;
BA_ "U_CD4_MY13_Hev_Rx" SG_ 995 PersIndexBcm_D_Actl 1;
BA_ "U_CD4_MY13_Phev_Rx" SG_ 995 PersIndexBcm_D_Actl 1;
BA_ "U_CD42_MY14_Diesel_Rx" SG_ 995 PersIndexBcm_D_Actl 1;
BA_ "U_CD42_MY14_Gas_Rx" SG_ 995 PersIndexBcm_D_Actl 1;
BA_ "U_P552_MY15_Gas_Rx" SG_ 995 PersIndexBcm_D_Actl 1;
BA_ "U_S550_MY15_Gas_Rx" SG_ 995 PersIndexBcm_D_Actl 1;
BA_ "U_C489_MY14_Gas_Rx" SG_ 995 PersIndexBcm_D_Actl 1;
BA_ "U_U502_MY15_Gas_Rx" SG_ 995 PersIndexBcm_D_Actl 1;
BA_ "U_CD43_MY16_Gas_Rx" SG_ 995 PersIndexBcm_D_Actl 1;
BA_ "U_CD4_MY14_Diesel_Rx" SG_ 995 PersIndexBcm_D_Actl 1;
BA_ "U_CD4_MY14_Gas_Rx" SG_ 995 PersIndexBcm_D_Actl 1;
BA_ "U_CD4_MY14_Hev_Rx" SG_ 995 PersIndexBcm_D_Actl 1;
BA_ "U_CD4_MY14_Phev_Rx" SG_ 995 PersIndexBcm_D_Actl 1;
BA_ "U_CD4_MY13_Diesel_Tx" SG_ 995 PersIndexBcm_D_Actl 1;
BA_ "U_CD4_MY13_Gas_Tx" SG_ 995 PersIndexBcm_D_Actl 1;
BA_ "U_CD4_MY13_Hev_Tx" SG_ 995 PersIndexBcm_D_Actl 1;
BA_ "U_CD4_MY13_Phev_Tx" SG_ 995 PersIndexBcm_D_Actl 1;
BA_ "U_CD42_MY14_Diesel_Tx" SG_ 995 PersIndexBcm_D_Actl 1;
BA_ "U_CD42_MY14_Gas_Tx" SG_ 995 PersIndexBcm_D_Actl 1;
BA_ "U_P552_MY15_Gas_Tx" SG_ 995 PersIndexBcm_D_Actl 1;
BA_ "U_S550_MY15_Gas_Tx" SG_ 995 PersIndexBcm_D_Actl 1;
BA_ "U_C489_MY14_Gas_Tx" SG_ 995 PersIndexBcm_D_Actl 1;
BA_ "U_U502_MY15_Gas_Tx" SG_ 995 PersIndexBcm_D_Actl 1;
BA_ "U_UP375_MY15_Gas_Tx" SG_ 995 PersIndexBcm_D_Actl 1;
BA_ "U_UP375_MY15_Diesel_Tx" SG_ 995 PersIndexBcm_D_Actl 1;
BA_ "U_CD43_MY16_Gas_Tx" SG_ 995 PersIndexBcm_D_Actl 1;
BA_ "U_CD4_MY14_Diesel_Tx" SG_ 995 PersIndexBcm_D_Actl 1;
BA_ "U_CD4_MY14_Gas_Tx" SG_ 995 PersIndexBcm_D_Actl 1;
BA_ "U_CD4_MY14_Hev_Tx" SG_ 995 PersIndexBcm_D_Actl 1;
BA_ "U_CD4_MY14_Phev_Tx" SG_ 995 PersIndexBcm_D_Actl 1;
BA_ "CrossOver_InfoCAN" SG_ 995 FeatNoBcm_No_Actl 1;
BA_ "GenSigSendType" SG_ 995 FeatNoBcm_No_Actl 3;
BA_ "U_CD4_MY13_Diesel_Rx" SG_ 995 FeatNoBcm_No_Actl 1;
BA_ "U_CD4_MY13_Gas_Rx" SG_ 995 FeatNoBcm_No_Actl 1;
BA_ "U_CD4_MY13_Hev_Rx" SG_ 995 FeatNoBcm_No_Actl 1;
BA_ "U_CD4_MY13_Phev_Rx" SG_ 995 FeatNoBcm_No_Actl 1;
BA_ "U_CD42_MY14_Diesel_Rx" SG_ 995 FeatNoBcm_No_Actl 1;
BA_ "U_CD42_MY14_Gas_Rx" SG_ 995 FeatNoBcm_No_Actl 1;
BA_ "U_P552_MY15_Gas_Rx" SG_ 995 FeatNoBcm_No_Actl 1;
BA_ "U_S550_MY15_Gas_Rx" SG_ 995 FeatNoBcm_No_Actl 1;
BA_ "U_C489_MY14_Gas_Rx" SG_ 995 FeatNoBcm_No_Actl 1;
BA_ "U_U502_MY15_Gas_Rx" SG_ 995 FeatNoBcm_No_Actl 1;
BA_ "U_CD43_MY16_Gas_Rx" SG_ 995 FeatNoBcm_No_Actl 1;
BA_ "U_CD4_MY14_Diesel_Rx" SG_ 995 FeatNoBcm_No_Actl 1;
BA_ "U_CD4_MY14_Gas_Rx" SG_ 995 FeatNoBcm_No_Actl 1;
BA_ "U_CD4_MY14_Hev_Rx" SG_ 995 FeatNoBcm_No_Actl 1;
BA_ "U_CD4_MY14_Phev_Rx" SG_ 995 FeatNoBcm_No_Actl 1;
BA_ "U_CD4_MY13_Diesel_Tx" SG_ 995 FeatNoBcm_No_Actl 1;
BA_ "U_CD4_MY13_Gas_Tx" SG_ 995 FeatNoBcm_No_Actl 1;
BA_ "U_CD4_MY13_Hev_Tx" SG_ 995 FeatNoBcm_No_Actl 1;
BA_ "U_CD4_MY13_Phev_Tx" SG_ 995 FeatNoBcm_No_Actl 1;
BA_ "U_CD42_MY14_Diesel_Tx" SG_ 995 FeatNoBcm_No_Actl 1;
BA_ "U_CD42_MY14_Gas_Tx" SG_ 995 FeatNoBcm_No_Actl 1;
BA_ "U_P552_MY15_Gas_Tx" SG_ 995 FeatNoBcm_No_Actl 1;
BA_ "U_S550_MY15_Gas_Tx" SG_ 995 FeatNoBcm_No_Actl 1;
BA_ "U_C489_MY14_Gas_Tx" SG_ 995 FeatNoBcm_No_Actl 1;
BA_ "U_U502_MY15_Gas_Tx" SG_ 995 FeatNoBcm_No_Actl 1;
BA_ "U_UP375_MY15_Gas_Tx" SG_ 995 FeatNoBcm_No_Actl 1;
BA_ "U_UP375_MY15_Diesel_Tx" SG_ 995 FeatNoBcm_No_Actl 1;
BA_ "U_CD43_MY16_Gas_Tx" SG_ 995 FeatNoBcm_No_Actl 1;
BA_ "U_CD4_MY14_Diesel_Tx" SG_ 995 FeatNoBcm_No_Actl 1;
BA_ "U_CD4_MY14_Gas_Tx" SG_ 995 FeatNoBcm_No_Actl 1;
BA_ "U_CD4_MY14_Hev_Tx" SG_ 995 FeatNoBcm_No_Actl 1;
BA_ "U_CD4_MY14_Phev_Tx" SG_ 995 FeatNoBcm_No_Actl 1;
BA_ "CrossOver_InfoCAN" SG_ 995 FeatConfigBcmActl 1;
BA_ "GenSigSendType" SG_ 995 FeatConfigBcmActl 3;
BA_ "U_CD4_MY13_Diesel_Rx" SG_ 995 FeatConfigBcmActl 1;
BA_ "U_CD4_MY13_Gas_Rx" SG_ 995 FeatConfigBcmActl 1;
BA_ "U_CD4_MY13_Hev_Rx" SG_ 995 FeatConfigBcmActl 1;
BA_ "U_CD4_MY13_Phev_Rx" SG_ 995 FeatConfigBcmActl 1;
BA_ "U_CD42_MY14_Diesel_Rx" SG_ 995 FeatConfigBcmActl 1;
BA_ "U_CD42_MY14_Gas_Rx" SG_ 995 FeatConfigBcmActl 1;
BA_ "U_P552_MY15_Gas_Rx" SG_ 995 FeatConfigBcmActl 1;
BA_ "U_S550_MY15_Gas_Rx" SG_ 995 FeatConfigBcmActl 1;
BA_ "U_C489_MY14_Gas_Rx" SG_ 995 FeatConfigBcmActl 1;
BA_ "U_U502_MY15_Gas_Rx" SG_ 995 FeatConfigBcmActl 1;
BA_ "U_CD43_MY16_Gas_Rx" SG_ 995 FeatConfigBcmActl 1;
BA_ "U_CD4_MY14_Diesel_Rx" SG_ 995 FeatConfigBcmActl 1;
BA_ "U_CD4_MY14_Gas_Rx" SG_ 995 FeatConfigBcmActl 1;
BA_ "U_CD4_MY14_Hev_Rx" SG_ 995 FeatConfigBcmActl 1;
BA_ "U_CD4_MY14_Phev_Rx" SG_ 995 FeatConfigBcmActl 1;
BA_ "U_CD4_MY13_Diesel_Tx" SG_ 995 FeatConfigBcmActl 1;
BA_ "U_CD4_MY13_Gas_Tx" SG_ 995 FeatConfigBcmActl 1;
BA_ "U_CD4_MY13_Hev_Tx" SG_ 995 FeatConfigBcmActl 1;
BA_ "U_CD4_MY13_Phev_Tx" SG_ 995 FeatConfigBcmActl 1;
BA_ "U_CD42_MY14_Diesel_Tx" SG_ 995 FeatConfigBcmActl 1;
BA_ "U_CD42_MY14_Gas_Tx" SG_ 995 FeatConfigBcmActl 1;
BA_ "U_P552_MY15_Gas_Tx" SG_ 995 FeatConfigBcmActl 1;
BA_ "U_S550_MY15_Gas_Tx" SG_ 995 FeatConfigBcmActl 1;
BA_ "U_C489_MY14_Gas_Tx" SG_ 995 FeatConfigBcmActl 1;
BA_ "U_U502_MY15_Gas_Tx" SG_ 995 FeatConfigBcmActl 1;
BA_ "U_UP375_MY15_Gas_Tx" SG_ 995 FeatConfigBcmActl 1;
BA_ "U_UP375_MY15_Diesel_Tx" SG_ 995 FeatConfigBcmActl 1;
BA_ "U_CD43_MY16_Gas_Tx" SG_ 995 FeatConfigBcmActl 1;
BA_ "U_CD4_MY14_Diesel_Tx" SG_ 995 FeatConfigBcmActl 1;
BA_ "U_CD4_MY14_Gas_Tx" SG_ 995 FeatConfigBcmActl 1;
BA_ "U_CD4_MY14_Hev_Tx" SG_ 995 FeatConfigBcmActl 1;
BA_ "U_CD4_MY14_Phev_Tx" SG_ 995 FeatConfigBcmActl 1;
BA_ "CrossOver_InfoCAN" SG_ 995 LightAmbColor_No_Actl 1;
BA_ "GenSigSendType" SG_ 995 LightAmbColor_No_Actl 3;
BA_ "U_CD4_MY13_Diesel_Rx" SG_ 995 LightAmbColor_No_Actl 1;
BA_ "U_CD4_MY13_Gas_Rx" SG_ 995 LightAmbColor_No_Actl 1;
BA_ "U_CD4_MY13_Hev_Rx" SG_ 995 LightAmbColor_No_Actl 1;
BA_ "U_CD4_MY13_Phev_Rx" SG_ 995 LightAmbColor_No_Actl 1;
BA_ "U_CD42_MY14_Diesel_Rx" SG_ 995 LightAmbColor_No_Actl 1;
BA_ "U_CD42_MY14_Gas_Rx" SG_ 995 LightAmbColor_No_Actl 1;
BA_ "U_P552_MY15_Gas_Rx" SG_ 995 LightAmbColor_No_Actl 1;
BA_ "U_S550_MY15_Gas_Rx" SG_ 995 LightAmbColor_No_Actl 1;
BA_ "U_C489_MY14_Gas_Rx" SG_ 995 LightAmbColor_No_Actl 1;
BA_ "U_U502_MY15_Gas_Rx" SG_ 995 LightAmbColor_No_Actl 1;
BA_ "U_CD43_MY16_Gas_Rx" SG_ 995 LightAmbColor_No_Actl 1;
BA_ "U_CD4_MY14_Diesel_Rx" SG_ 995 LightAmbColor_No_Actl 1;
BA_ "U_CD4_MY14_Gas_Rx" SG_ 995 LightAmbColor_No_Actl 1;
BA_ "U_CD4_MY14_Hev_Rx" SG_ 995 LightAmbColor_No_Actl 1;
BA_ "U_CD4_MY14_Phev_Rx" SG_ 995 LightAmbColor_No_Actl 1;
BA_ "U_CD4_MY13_Diesel_Tx" SG_ 995 LightAmbColor_No_Actl 1;
BA_ "U_CD4_MY13_Gas_Tx" SG_ 995 LightAmbColor_No_Actl 1;
BA_ "U_CD4_MY13_Hev_Tx" SG_ 995 LightAmbColor_No_Actl 1;
BA_ "U_CD4_MY13_Phev_Tx" SG_ 995 LightAmbColor_No_Actl 1;
BA_ "U_CD42_MY14_Diesel_Tx" SG_ 995 LightAmbColor_No_Actl 1;
BA_ "U_CD42_MY14_Gas_Tx" SG_ 995 LightAmbColor_No_Actl 1;
BA_ "U_P552_MY15_Gas_Tx" SG_ 995 LightAmbColor_No_Actl 1;
BA_ "U_S550_MY15_Gas_Tx" SG_ 995 LightAmbColor_No_Actl 1;
BA_ "U_C489_MY14_Gas_Tx" SG_ 995 LightAmbColor_No_Actl 1;
BA_ "U_U502_MY15_Gas_Tx" SG_ 995 LightAmbColor_No_Actl 1;
BA_ "U_UP375_MY15_Gas_Tx" SG_ 995 LightAmbColor_No_Actl 1;
BA_ "U_UP375_MY15_Diesel_Tx" SG_ 995 LightAmbColor_No_Actl 1;
BA_ "U_CD43_MY16_Gas_Tx" SG_ 995 LightAmbColor_No_Actl 1;
BA_ "U_CD4_MY14_Diesel_Tx" SG_ 995 LightAmbColor_No_Actl 1;
BA_ "U_CD4_MY14_Gas_Tx" SG_ 995 LightAmbColor_No_Actl 1;
BA_ "U_CD4_MY14_Hev_Tx" SG_ 995 LightAmbColor_No_Actl 1;
BA_ "U_CD4_MY14_Phev_Tx" SG_ 995 LightAmbColor_No_Actl 1;
BA_ "GenSigSendType" SG_ 2000 TesterPhysicalReqAPIM 3;
BA_ "U_CD4_MY13_Diesel_Rx" SG_ 2000 TesterPhysicalReqAPIM 1;
BA_ "U_CD4_MY13_Gas_Rx" SG_ 2000 TesterPhysicalReqAPIM 1;
BA_ "U_CD4_MY13_Hev_Rx" SG_ 2000 TesterPhysicalReqAPIM 1;
BA_ "U_CD4_MY13_Phev_Rx" SG_ 2000 TesterPhysicalReqAPIM 1;
BA_ "U_CD42_MY14_Diesel_Rx" SG_ 2000 TesterPhysicalReqAPIM 1;
BA_ "U_CD42_MY14_Gas_Rx" SG_ 2000 TesterPhysicalReqAPIM 1;
BA_ "U_P552_MY15_Gas_Rx" SG_ 2000 TesterPhysicalReqAPIM 1;
BA_ "U_S550_MY15_Gas_Rx" SG_ 2000 TesterPhysicalReqAPIM 1;
BA_ "U_C489_MY14_Gas_Rx" SG_ 2000 TesterPhysicalReqAPIM 1;
BA_ "U_U502_MY15_Gas_Rx" SG_ 2000 TesterPhysicalReqAPIM 1;
BA_ "U_CD43_MY16_Gas_Rx" SG_ 2000 TesterPhysicalReqAPIM 1;
BA_ "U_CD4_MY14_Diesel_Rx" SG_ 2000 TesterPhysicalReqAPIM 1;
BA_ "U_CD4_MY14_Gas_Rx" SG_ 2000 TesterPhysicalReqAPIM 1;
BA_ "U_CD4_MY14_Hev_Rx" SG_ 2000 TesterPhysicalReqAPIM 1;
BA_ "U_CD4_MY14_Phev_Rx" SG_ 2000 TesterPhysicalReqAPIM 1;
BA_ "U_CD4_MY13_Diesel_Tx" SG_ 2000 TesterPhysicalReqAPIM 1;
BA_ "U_CD4_MY13_Gas_Tx" SG_ 2000 TesterPhysicalReqAPIM 1;
BA_ "U_CD4_MY13_Hev_Tx" SG_ 2000 TesterPhysicalReqAPIM 1;
BA_ "U_CD4_MY13_Phev_Tx" SG_ 2000 TesterPhysicalReqAPIM 1;
BA_ "U_CD42_MY14_Diesel_Tx" SG_ 2000 TesterPhysicalReqAPIM 1;
BA_ "U_CD42_MY14_Gas_Tx" SG_ 2000 TesterPhysicalReqAPIM 1;
BA_ "U_P552_MY15_Gas_Tx" SG_ 2000 TesterPhysicalReqAPIM 1;
BA_ "U_S550_MY15_Gas_Tx" SG_ 2000 TesterPhysicalReqAPIM 1;
BA_ "U_C489_MY14_Gas_Tx" SG_ 2000 TesterPhysicalReqAPIM 1;
VAL_ 994 PersStore_D_Rq 7 "Unused_2" 6 "Unused_1" 5 "Vehicle" 4 "PERS_4" 3 "PERS_3" 2 "PERS_2" 1 "PERS_1" 0 "Null" ;
VAL_ 994 Pers4OptIn_B_Stats 1 "OPTED_IN" 0 "NOT_OPTED_IN" ;
VAL_ 994 Pers3OptIn_B_Stats 1 "OPTED_IN" 0 "NOT_OPTED_IN" ;
VAL_ 994 Pers2OptIn_B_Stats 1 "OPTED_IN" 0 "NOT_OPTED_IN" ;
VAL_ 994 Pers1OptIn_B_Stats 1 "OPTED_IN" 0 "NOT_OPTED_IN" ;
VAL_ 994 CtrStkPersIndex_D_Actl 7 "Unused_3" 6 "Unused_2" 5 "Unused_1" 4 "Vehicle" 3 "PERS_4" 2 "PERS_3" 1 "PERS_2" 0 "PERS_1" ;
VAL_ 994 CtrStkDsplyOp_D_Rq 7 "Unused_2" 6 "Unused_1" 5 "Copy" 4 "Restore" 3 "Upload" 2 "Set" 1 "Query" 0 "Null" ;
VAL_ 512 PtDrvMde_D_Stat 15 "Faulty" 14 "NotUsed11" 13 "NotUsed10" 12 "NotUsed9" 11 "NotUsed8" 10 "NotUsed7" 9 "NotUsed6" 8 "NotUsed5" 7 "NotUsed4" 6 "Rock" 5 "Baja" 4 "Sand" 3 "TowHaulGradeAssist" 2 "SnowWet" 1 "Sport" 0 "Normal" ;
VAL_ 65 immoControlCmd_T1 0 "IDLE" 1 "MOTIVE_START_RQST" 2 "NONMOTIVE_START_RQST" 3 "RQST_TARGET1_IDBLOCK1" 4 "RQST_TARGET1_IDBLOCK2" 5 "Unused" 6 "ECHO_TARGET1_IDBLOCK2" 7 "SHUTDOWN" ;
VAL_ 560 GearLvr_D_ActlDrv 15 "Fault" 14 "Unknown_Position" 13 "Undefined_Treat_as__Fault" 12 "Undefined_Treat_as_Fault" 11 "sixth" 10 "fifth" 9 "fourth" 8 "third" 7 "second" 6 "first" 5 "Low" 4 "Sport_DriveSport" 3 "Drive" 2 "Neutral" 1 "Reverse" 0 "Park" ;
VAL_ 560 SelDrvMdeSwtch_D_Stat3 3 "Faulty" 2 "SwitchState2" 1 "SwitchState1" 0 "NotPressed" ;
VAL_ 560 TrnSrvcRqd_B_Rq 1 "On" 0 "Off" ;
VAL_ 560 GearPos_D_Trg 15 "Unknown" 14 "Reverse" 13 "Undefined_5" 12 "Undefined_4" 11 "Undefined_3" 10 "Tenth" 9 "Ninth" 8 "Eighth" 7 "Seventh" 6 "Sixth" 5 "Fifth" 4 "Fourth" 3 "Third" 2 "Second" 1 "First" 0 "Neutral" ;
VAL_ 560 TrnShifActv_B_Actl 1 "Active" 0 "Inactive" ;
VAL_ 560 GearLvrPos_D_Actl 15 "Fault" 14 "Unknown_Position" 13 "Undefined_Treat_as__Fault" 12 "Undefined_Treat_as_Fault" 11 "sixth" 10 "fifth" 9 "fourth" 8 "third" 7 "second" 6 "first" 5 "Low" 4 "Sport_DriveSport" 3 "Drive" 2 "Neutral" 1 "Reverse" 0 "Park" ;
VAL_ 560 GboxOil_Te_Actl 255 "Fault" 254 "Unknown" ;
VAL_ 357 CmbbEngTqMn_B_Actl 1 "Yes" 0 "No" ;
VAL_ 357 CmbbDeny_B_ActlPrpl 1 "Yes" 0 "No" ;
VAL_ 357 AccStopMde_D_Rq 3 "Stop_Mode_Active" 2 "EPBApplyOrBrakeReleaseWarn" 1 "Limit_Rolling_Speed" 0 "Stop_Mode_Not_Active" ;
VAL_ 357 BPedDrvAppl_D_QF 3 "OK" 2 "Not_Within_Specifications" 1 "No_Data_Exists" 0 "Faulty" ;
VAL_ 357 PrplTqMnSat_B_Actl 1 "Yes" 0 "No" ;
VAL_ 357 BpedDrvAppl_D_Actl 3 "_Not_Allowed" 2 "Driver_Braking" 1 "Driver_Not_Braking" 0 "Not_Allowed" ;
VAL_ 357 Veh_V_DsplyCcSet 255 "Fault" 254 "Unknown" ;
VAL_ 357 AccEngStat_D_Actl 7 "Undefined_2" 6 "Undefined_1" 5 "ACCSoonCancel_due_Low_Spd" 4 "Shift_Down_Recommendation" 3 "Shift_Up_Recommendation" 2 "ACCNotAllowedToBeActivated" 1 "ACCStandby_due_Auto_Cancel" 0 "Normal_Operation" ;
VAL_ 357 CcMde_D_Actl 7 "TapDownWaiting" 6 "TapUpWaiting" 5 "Resuming_Low" 4 "Resuming_High" 3 "Decelerating" 2 "Accelerating" 1 "Keeping_Speed" 0 "Not_Active" ;
VAL_ 357 CcStat_D_Actl 7 "Undefined_2" 6 "Undefined_1" 5 "Active" 4 "Active_Que_Assist" 3 "Standby" 2 "Standby_Denied" 1 "Denied" 0 "Off" ;
VAL_ 357 CcOvrrdActv_B_Actl 1 "Cruise_Overridden" 0 "Cruise_Req_Not_Overridden" ;
VAL_ 1003 PersRecallSrc_D_Actl 7 "NotUsed_3" 6 "NotUsed_2" 5 "NotUsed_1" 4 "MemorySwitch" 3 "RemoteStart" 2 "KeyFob" 1 "CenterStack" 0 "Null" ;
VAL_ 1003 Pers4Key_D_Stat 3 "NotUsed" 2 "KeyUnassociated" 1 "KeyAssociated" 0 "Null" ;
VAL_ 1003 Pers3Key_D_Stat 3 "NotUsed" 2 "KeyUnassociated" 1 "KeyAssociated" 0 "Null" ;
VAL_ 1003 Pers2Key_D_Stat 3 "NotUsed" 2 "KeyUnassociated" 1 "KeyAssociated" 0 "Null" ;
VAL_ 1003 Pers1Key_D_Stat 3 "NotUsed" 2 "KeyUnassociated" 1 "KeyAssociated" 0 "Null" ;
VAL_ 1003 EmPrflNo_D_Stat 7 "Unused_3" 6 "Unused_2" 5 "Unused_1" 4 "PERS_4" 3 "PERS_3" 2 "PERS_2" 1 "PERS_1" 0 "Null" ;
VAL_ 1003 EmPrflKeyAssoc_D_Stat 7 "NotUsed" 6 "KeyAssociateFailed" 5 "KeyAssociateSuccess" 4 "KeyAlreadyInUse" 3 "KeyDisassociated" 2 "KeyAssociationExited" 1 "KeyAssociationEntered" 0 "Null" ;
VAL_ 1003 VehKeyActv_D_Stat 15 "NotUsed7" 14 "NotUsed6" 13 "NotUsed5" 12 "NotUsed4" 11 "NotUsed3" 10 "NotUsed2" 9 "NotUsed1" 8 "Key8Active" 7 "Key7Active" 6 "Key6Active" 5 "Key5Active" 4 "Key4Active" 3 "Key3Active" 2 "Key2Active" 1 "Key1Active" 0 "NoKeyActive" ;
VAL_ 1003 PersNoPos_D_Actl 7 "Unused_3" 6 "Unused_2" 5 "Unused_1" 4 "Vehicle" 3 "PERS_4" 2 "PERS_3" 1 "PERS_2" 0 "PERS_1" ;
VAL_ 1003 PersSetupRestr_D_Actl 3 "Non_Moveable_Person" 2 "Moveable_Person" 1 "Vehicle" 0 "Factory" ;
VAL_ 1003 PersSetupAccessCtrl 1 "Limited" 0 "Full" ;
VAL_ 1003 PersConflict_D_Actl 1 "Conflict" 0 "No_Conflict" ;
VAL_ 1003 AssocConfirm_D_Actl 0 "None" 7 "Associate" 6 "Keycode_Rejected" 5 "Keycode_Accepted" 4 "In_Progress" 3 "Erase" 2 "Duplicate" 1 "Disassociate" ;
VAL_ 1003 PersNo_D_Actl 7 "Unused_3" 6 "Unused_2" 5 "Unused_1" 4 "Vehicle" 3 "PERS_4" 2 "PERS_3" 1 "PERS_2" 0 "PERS_1" ;
VAL_ 1068 EngStrtInhbt_B_RqBatt 1 "Start_Inhibit" 0 "Dont_Care" ;
VAL_ 1068 BattULoChrg_D_Rq 3 "Low_Battery_Temperature" 2 "Charging_Requested" 1 "Chrg_Requested_HighCurrent" 0 "No_Request" ;
VAL_ 1068 PwSysULoFalt_D_Stat 15 "Not_Used_6" 14 "LowBatterySOC" 13 "PSS_Shed2_Contin" 12 "Not_Used_4" 11 "Not_Used_3" 10 "Not_Used_2" 9 "BattMonitoringSensorFault" 8 "LowBattVoltDuringPwSrcOn" 7 "LowBatt2_PowerSaveMode" 6 "LowBatt1_Warning" 5 "Overvoltage" 4 "Fault_NoOutput" 3 "Fault_ReducedOutput" 2 "Fault_Nonspecific" 1 "Cluster_Proveout" 0 "No_Fault" ;
VAL_ 1068 Shed_T_Eng_Off_B 1 "Active" 0 "Inactive" ;
VAL_ 1068 Shed_Feature_Group_ID 14 "HtdMirr" 13 "HvacRearBlwr_Third" 12 "HvacRearBlwr_Second" 11 "HvacRearBlwr_First" 31 "All LSHED1 Features" 10 "Htd_Windscrn" 9 "SpltHtdBcklight_HtdMirr" 8 "HtdBcklight_HtdMirr" 7 "HtdCoolSeat_FrtDriver" 6 "HtdCoolSeat_FrtPass" 5 "HtdCoolSeat_RearPass" 4 "HtdCoolSeat_RearDriver" 3 "SmartTrlrTowBattCharge" 2 "Htd_StrWhl" 1 "Htd_Washer_Fluid" 0 "No_LSHED1_Features" 15 "Engine_Coolant_Fan" ;
VAL_ 1068 Shed_Drain_Eng_Off_B 1 "Active" 0 "Inactive" ;
VAL_ 1068 Shed_Level_Req 7 "Unused_2" 6 "Loads_On" 5 "SHED_ENG_OFF" 4 "SOON_ENG_OFF" 3 "SHED2_CONTIN" 2 "SHED2_TRANS" 1 "SHED1" 0 "NO_SHED" ;
VAL_ 1068 ULoRgenTestMde_B_Rq 1 "Request" 0 "NoRequest" ;
VAL_ 1068 ChargeMode 7 "Undefined_2" 6 "Undefined_1" 5 "Battery_Identify" 4 "Battery_Refresh" 3 "SlowRegenAllowNoDischarge" 2 "Fast_Regen_Allowed" 1 "Slow_Regen_Allowed" 0 "Conventional_Charging" ;
VAL_ 1068 IdleSpeedIncrease_El 1 "Yes" 0 "No" ;
VAL_ 1068 Batt_Lo_SoC_B 1 "Active" 0 "Inactive" ;
VAL_ 1068 PeriodicElLoad_B_Stat 1 "Active" 0 "Inactive" ;
VAL_ 1068 Batt_Crit_SoC_B 1 "Active" 0 "Inactive" ;
VAL_ 947 ValetMode_D_Mem 1 "On" 0 "Off" ;
VAL_ 947 DrStatDrvErrCnt_B_Stat 1 "Yes" 0 "No" ;
VAL_ 947 TurnLghtRight_D_Rq 3 "Seq" 2 "On" 1 "Off" 0 "Null" ;
VAL_ 947 TurnLghtRightOn_B_Stat 1 "On" 0 "Off" ;
VAL_ 947 TurnLghtLeftOn_B_Stat 1 "On" 0 "Off" ;
VAL_ 947 FogLghtRearOn_B_Stat 1 "On" 0 "Off" ;
VAL_ 947 Backlit_LED_Status 15 "Unused3" 14 "Unused2" 13 "Unused1" 12 "Night_12" 11 "Night_11" 10 "Night_10" 9 "Night_9" 8 "Night_8" 7 "Night_7" 6 "Night_6" 5 "Night_5" 4 "Night_4" 3 "Night_3" 2 "Night_2" 1 "Night_1" 0 "Off" ;
VAL_ 947 TurnLghtLeft_D_Rq 3 "Seq" 2 "On" 1 "Off" 0 "Null" ;
VAL_ 947 FogLghtFrontOn_B_Stat 1 "On" 0 "Off" ;
VAL_ 947 IgnKeyType_D_Actl 15 "Invalid" 14 "Unknown" 3 "Key_Not_Prgrm_Read_Failure" 2 "Key_In_Ign_My_Key" 1 "Key_In_Ign_Standard_Key" 0 "Key_Read_In_Progress" ;
VAL_ 947 Parklamp_Status 1 "On" 0 "Off" 3 "Invalid" 2 "Unknown" ;
VAL_ 947 Litval 255 "Invalid" 254 "Unknown" 5 "Day" 4 "Twilight_4" 3 "Twilight_3" 2 "Twilight_2" 1 "Twilight_1" 0 "Night" ;
VAL_ 947 Key_In_Ignition_Stat 1 "In" 0 "Out" ;
VAL_ 947 Ignition_Status 0 "Unknown" 1 "Off" 15 "Invalid" 8 "Start" 4 "Run" 2 "Accessory" ;
VAL_ 947 Dimming_Lvl 255 "Invalid" 254 "Unknown" 18 "Day_6" 17 "Day_5" 16 "Day_4" 15 "Day_3" 14 "Day_2" 13 "Day_1" 12 "Night_12" 11 "Night_11" 10 "Night_10" 9 "Night_9" 8 "Night_8" 7 "Night_7" 6 "Night_6" 5 "Night_5" 4 "Night_4" 3 "Night_3" 2 "Night_2" 1 "Night_1" 0 "Off" ;
VAL_ 947 Day_Night_Status 3 "NotUsed" 2 "Night" 1 "Day" 0 "Null" ;
VAL_ 947 Remote_Start_Status 3 "Invalid" 2 "Unknown" 1 "Remote" 0 "Null" ;
VAL_ 947 DrStatTgate_B_Actl 1 "Ajar" 0 "Closed" ;
VAL_ 947 DrStatRr_B_Actl 1 "Ajar" 0 "Closed" ;
VAL_ 947 DrStatRl_B_Actl 1 "Ajar" 0 "Closed" ;
VAL_ 947 DrStatPsngr_B_Actl 1 "Ajar" 0 "Closed" ;
VAL_ 947 DrStatInnrTgate_B_Actl 1 "Ajar" 0 "Closed" ;
VAL_ 947 DrStatHood_B_Actl 1 "Ajar" 0 "Closed" ;
VAL_ 947 DrStatDrv_B_Actl 1 "Ajar" 0 "Closed" ;
VAL_ 947 PrkBrkActv_B_Actl 1 "Active" 0 "Inactive" ;
VAL_ 947 LifeCycMde_D_Actl 3 "Transport" 2 "NotUsed" 1 "Factory" 0 "Normal" ;
VAL_ 947 Delay_Accy 1 "On" 0 "Off" ;
VAL_ 947 CrashEvnt_D_Stat 3 "Invalid" 2 "Fuel_Cutoff_Event" 1 "Deploy_Event" 0 "No_Event" ;
VAL_ 947 FuelPmpInhbt_B_Stat 1 "Inhibit" 0 "No_Inibit" ;
VAL_ 947 BodySrvcRqd_B_Rq 1 "Yes" 0 "No" ;
VAL_ 986 LightAmbIntsty_No_Rq 0 "Off" ;
VAL_ 995 FobAssocChime_B_Rq 1 "On" 0 "Off" ;
VAL_ 995 LightAmbIntsty_No_Actl 0 "Off" ;
VAL_ 995 PersIndexBcm_D_Actl 7 "Unused_3" 6 "Unused_2" 5 "Unused_1" 4 "Vehicle" 3 "PERS_4" 2 "PERS_3" 1 "PERS_2" 0 "PERS_1" ;
